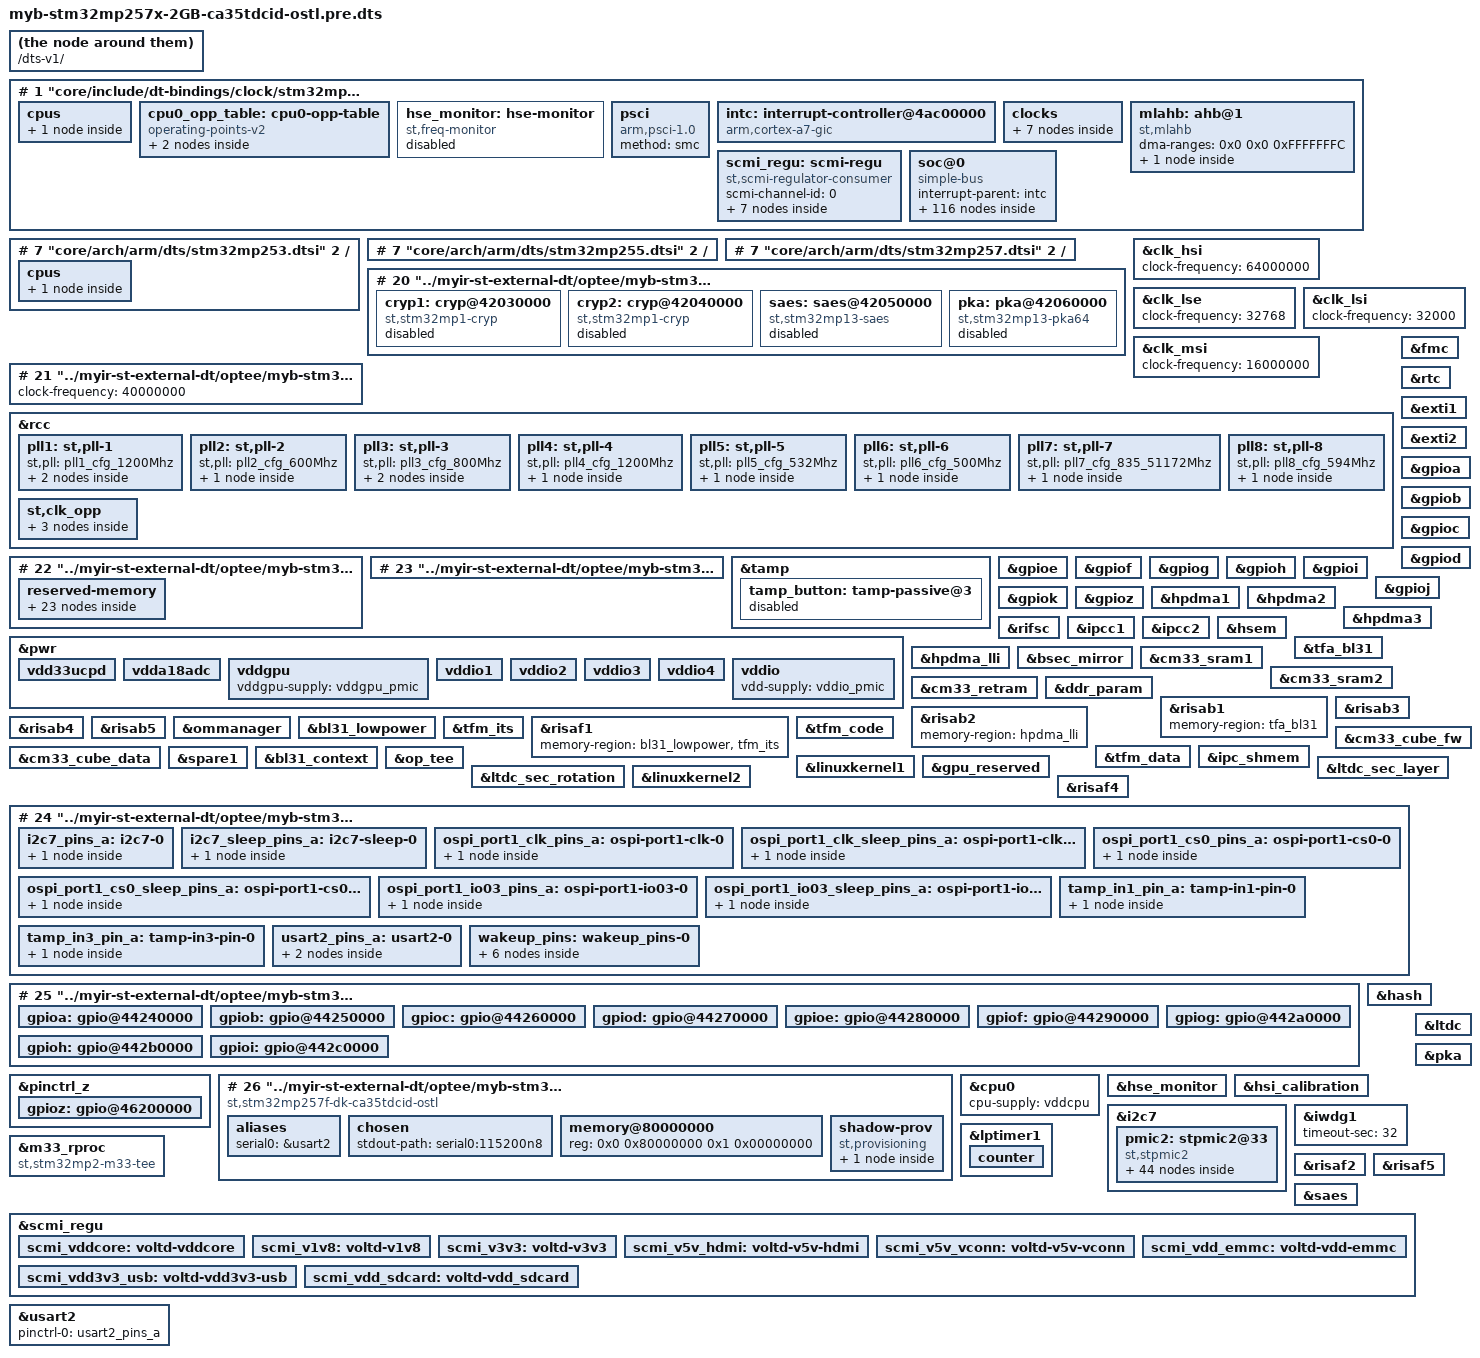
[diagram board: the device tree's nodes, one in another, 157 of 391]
# 0 "../myir-st-external-dt/optee/myb-stm32mp257x-2GB-ca35tdcid-ostl.dts"
# 0 "<built-in>"
# 0 "<command-line>"
# 1 "../myir-st-external-dt/optee/myb-stm32mp257x-2GB-ca35tdcid-ostl.dts"






/dts-v1/;

# 1 "core/include/dt-bindings/clock/stm32mp25-clksrc.h" 1
# 10 "../myir-st-external-dt/optee/myb-stm32mp257x-2GB-ca35tdcid-ostl.dts" 2
# 1 "core/include/dt-bindings/mfd/st,stpmic2.h" 1
# 11 "../myir-st-external-dt/optee/myb-stm32mp257x-2GB-ca35tdcid-ostl.dts" 2
# 1 "core/include/dt-bindings/regulator/st,stm32mp25-regulator.h" 1
# 12 "../myir-st-external-dt/optee/myb-stm32mp257x-2GB-ca35tdcid-ostl.dts" 2
# 1 "core/include/dt-bindings/reset/stm32mp25-resets.h" 1
# 13 "../myir-st-external-dt/optee/myb-stm32mp257x-2GB-ca35tdcid-ostl.dts" 2
# 1 "core/include/dt-bindings/soc/stm32mp-provisioning.h" 1
# 14 "../myir-st-external-dt/optee/myb-stm32mp257x-2GB-ca35tdcid-ostl.dts" 2
# 1 "core/include/dt-bindings/soc/stm32mp25-rif.h" 1
# 15 "../myir-st-external-dt/optee/myb-stm32mp257x-2GB-ca35tdcid-ostl.dts" 2
# 1 "core/include/dt-bindings/soc/stm32mp25-risab.h" 1
# 16 "../myir-st-external-dt/optee/myb-stm32mp257x-2GB-ca35tdcid-ostl.dts" 2
# 1 "core/include/dt-bindings/soc/stm32mp25-risaf.h" 1
# 17 "../myir-st-external-dt/optee/myb-stm32mp257x-2GB-ca35tdcid-ostl.dts" 2
# 1 "core/include/dt-bindings/soc/stm32mp25-rifsc.h" 1
# 18 "../myir-st-external-dt/optee/myb-stm32mp257x-2GB-ca35tdcid-ostl.dts" 2
# 1 "core/include/dt-bindings/tamper/st,stm32mp25-tamp.h" 1
# 19 "../myir-st-external-dt/optee/myb-stm32mp257x-2GB-ca35tdcid-ostl.dts" 2
# 1 "core/arch/arm/dts/stm32mp257.dtsi" 1





# 1 "core/arch/arm/dts/stm32mp255.dtsi" 1





# 1 "core/arch/arm/dts/stm32mp253.dtsi" 1





# 1 "core/arch/arm/dts/stm32mp251.dtsi" 1






# 1 "core/include/dt-bindings/interrupt-controller/arm-gic.h" 1
# 9 "core/include/dt-bindings/interrupt-controller/arm-gic.h"
# 1 "core/include/dt-bindings/interrupt-controller/irq.h" 1
# 10 "core/include/dt-bindings/interrupt-controller/arm-gic.h" 2
# 8 "core/arch/arm/dts/stm32mp251.dtsi" 2
# 1 "core/include/dt-bindings/clock/stm32mp25-clks.h" 1
# 9 "core/arch/arm/dts/stm32mp251.dtsi" 2



/ {
 #address-cells = <2>;
 #size-cells = <2>;

 cpus {
  #address-cells = <1>;
  #size-cells = <0>;

  cpu0: cpu@0 {
   compatible = "arm,cortex-a35";
   device_type = "cpu";
   reg = <0>;
   enable-method = "psci";
   operating-points-v2 = <&cpu0_opp_table>;
   clocks = <&rcc 16>;
  };
 };

 cpu0_opp_table: cpu0-opp-table {
  compatible = "operating-points-v2";

  opp-1200000000 {
   opp-hz = /bits/ 64 <1200000000>;
   opp-microvolt = <800000>;
   opp-supported-hw = <0x3>;
   st,opp-default;
  };

  opp-1500000000 {
   opp-hz = /bits/ 64 <1500000000>;
   opp-microvolt = <910000>;
   opp-supported-hw = <0x2>;
  };
 };

 hse_monitor: hse-monitor {
  compatible = "st,freq-monitor";
  counter = <&lptimer1 1 5 1 1>;
  clocks = <&rcc 1>, <&rcc 0>;
  clock-names = "hse", "hsi";
  status = "disabled";
 };

 psci {
  compatible = "arm,psci-1.0";
  method = "smc";
 };

 intc: interrupt-controller@4ac00000 {
  compatible = "arm,cortex-a7-gic";
  #interrupt-cells = <3>;
  interrupt-controller;
  reg = <0x0 0x4ac10000 0x0 0x1000>,
        <0x0 0x4ac20000 0x0 0x2000>,
        <0x0 0x4ac40000 0x0 0x2000>,
        <0x0 0x4ac60000 0x0 0x2000>;
  #address-cells = <1>;
 };

 clocks {
  clk_hse: clk-hse {
   #clock-cells = <0>;
   compatible = "fixed-clock";
   clock-frequency = <24000000>;
  };

  clk_hsi: clk-hsi {
   #clock-cells = <0>;
   compatible = "fixed-clock";
   clock-frequency = <64000000>;
  };

  clk_lse: clk-lse {
   #clock-cells = <0>;
   compatible = "fixed-clock";
   clock-frequency = <32768>;
  };

  clk_lsi: clk-lsi {
   #clock-cells = <0>;
   compatible = "fixed-clock";
   clock-frequency = <32000>;
  };

  clk_msi: clk-msi {
   #clock-cells = <0>;
   compatible = "fixed-clock";
   clock-frequency = <4000000>;
  };

  clk_i2sin: clk-i2sin {
   #clock-cells = <0>;
   compatible = "fixed-clock";
   clock-frequency = <0>;
  };

  clk_rcbsec: clk-rcbsec {
   #clock-cells = <0>;
   compatible = "fixed-clock";
   clock-frequency = <64000000>;
  };
 };

 mlahb: ahb@1 {
  compatible = "st,mlahb", "simple-bus";
  #address-cells = <1>;
  #size-cells = <1>;
  ranges = <0x0 0x0 0xFFFFFFFC>;
  dma-ranges = <0x0 0x0 0xFFFFFFFC>;

  m33_rproc: m33@0 {
   compatible = "st,stm32mp2-m33";
   reg = <0 0>;
   resets = <&rcc 8288>,
     <&rcc 8608>;
   reset-names = "mcu_rst", "hold_boot";
   status = "disabled";
  };
 };

 scmi_regu: scmi-regu {
  compatible = "st,scmi-regulator-consumer";
  #address-cells = <1>;
  #size-cells = <0>;

  scmi-channel-id = <0>;

  scmi_vddio1: voltd-vddio1 {
   reg = <0>;
   voltd-supply = <&vddio1>;
  };
  scmi_vddio2: voltd-vddio2 {
   reg = <1>;
   voltd-supply = <&vddio2>;
  };
  scmi_vddio3: voltd-vddio3 {
   reg = <2>;
   voltd-supply = <&vddio3>;
  };
  scmi_vddio4: voltd-vddio4 {
   reg = <3>;
   voltd-supply = <&vddio4>;
  };
  scmi_vdd33ucpd: voltd-vdd33ucpd {
   reg = <5>;
   voltd-supply = <&vdd33ucpd>;
  };
  scmi_vdda18adc: voltd-vdda18adc {
   reg = <7>;
   voltd-supply = <&vdda18adc>;
  };
  scmi_vddgpu: voltd-vddgpu {
   reg = <8>;
   voltd-supply = <&vddgpu>;
  };
 };

 soc@0 {
  compatible = "simple-bus";
  #address-cells = <1>;
  #size-cells = <1>;
  interrupt-parent = <&intc>;
  ranges = <0x0 0x0 0x0 0x80000000>;

  hpdma1: dma-controller@40400000 {
   compatible = "st,stm32-dma3";
   reg = <0x40400000 0x1000>;
   clocks = <&rcc 98>;
   resets = <&rcc 10976>;
   #dma-cells = <4>;
  };

  hpdma2: dma-controller@40410000 {
   compatible = "st,stm32-dma3";
   reg = <0x40410000 0x1000>;
   clocks = <&rcc 99>;
   resets = <&rcc 11008>;
   #dma-cells = <4>;
  };

  hpdma3: dma-controller@40420000 {
   compatible = "st,stm32-dma3";
   reg = <0x40420000 0x1000>;
   clocks = <&rcc 100>;
   resets = <&rcc 11040>;
   #dma-cells = <4>;
  };

  ipcc1: mailbox@40490000 {
   compatible = "st,stm32mp25-ipcc";
   reg = <0x40490000 0x400>;
   clocks = <&rcc 103>;
  };

  ommanager: ommanager@40500000 {
   #address-cells = <2>;
   #size-cells = <1>;
   compatible = "st,stm32mp25-omm";
   reg = <0x40500000 0x400>, <0x60000000 0x10000000>;
   reg-names = "omm", "omm_mm";
   clocks = <&rcc 107>;
   resets = <&rcc 17888>;
   st,syscfg-amcr = <&syscfg 0x2c00 0x7>;
   status = "disabled";

   ranges = <0 0 0x40430000 0x400>,
     <1 0 0x40440000 0x400>;

   ospi1: spi@40430000 {
    compatible = "st,stm32mp25-omi";
    reg = <0 0 0x400>;
    clocks = <&rcc 310>;
    resets = <&rcc 10400>, <&rcc 10416>;
    status = "disabled";
   };

   ospi2: spi@40440000 {
    compatible = "st,stm32mp25-omi";
    reg = <1 0 0x400>;
    clocks = <&rcc 311>;
    resets = <&rcc 10432>, <&rcc 10448>;
    status = "disabled";
   };
  };

  rifsc: rifsc@42080000 {
   compatible = "st,stm32mp25-rifsc";
   reg = <0x42080000 0x1000>;
   #address-cells = <1>;
   #size-cells = <1>;

   lptimer1: timer@40090000 {
    compatible = "st,stm32mp25-lptimer";
    reg = <0x40090000 0x400>;
    interrupts = <0 166 4>;
    clocks = <&rcc 253>;
    clock-names = "mux";
    #address-cells = <1>;
    #size-cells = <0>;
    status = "disabled";

    counter {
     compatible = "st,stm32mp25-lptimer-counter";
     status = "disabled";
    };

    pwm {
     compatible = "st,stm32mp25-pwm-lp";
     #pwm-cells = <3>;
     status = "disabled";
    };

    timer {
     compatible = "st,stm32mp25-lptimer-timer";
     status = "disabled";
    };

    trigger@0 {
     compatible = "st,stm32mp25-lptimer-trigger";
     reg = <0>;
     status = "disabled";
    };
   };

   lptimer2: timer@400a0000 {
    compatible = "st,stm32mp25-lptimer";
    reg = <0x400a0000 0x400>;
    interrupts = <0 215 4>;
    clocks = <&rcc 254>;
    clock-names = "mux";
    #address-cells = <1>;
    #size-cells = <0>;
    status = "disabled";

    counter {
     compatible = "st,stm32mp25-lptimer-counter";
     status = "disabled";
    };

    pwm {
     compatible = "st,stm32mp25-pwm-lp";
     #pwm-cells = <3>;
     status = "disabled";
    };

    timer {
     compatible = "st,stm32mp25-lptimer-timer";
     status = "disabled";
    };

    trigger@1 {
     compatible = "st,stm32mp25-lptimer-trigger";
     reg = <1>;
     status = "disabled";
    };
   };

   usart2: serial@400e0000 {
    compatible = "st,stm32h7-uart";
    reg = <0x400e0000 0x400>;
    interrupts = <0 115 4>;
    clocks = <&rcc 255>;
    status = "disabled";
   };

   usart3: serial@400f0000 {
    compatible = "st,stm32h7-uart";
    reg = <0x400f0000 0x400>;
    interrupts = <0 116 4>;
    clocks = <&rcc 257>;
    status = "disabled";
   };

   uart4: serial@40100000 {
    compatible = "st,stm32h7-uart";
    reg = <0x40100000 0x400>;
    interrupts = <0 126 4>;
    clocks = <&rcc 256>;
    status = "disabled";
   };

   uart5: serial@40110000 {
    compatible = "st,stm32h7-uart";
    reg = <0x40110000 0x400>;
    interrupts = <0 127 4>;
    clocks = <&rcc 258>;
    status = "disabled";
   };

   i2c1: i2c@40120000 {
    compatible = "st,stm32mp25-i2c";
    reg = <0x40120000 0x400>;
    clocks = <&rcc 262>;
    resets = <&rcc 15648>;
    #address-cells = <1>;
    #size-cells = <0>;
    i2c-analog-filter;
    status = "disabled";
   };

   i2c2: i2c@40130000 {
    compatible = "st,stm32mp25-i2c";
    reg = <0x40130000 0x400>;
    clocks = <&rcc 263>;
    resets = <&rcc 15680>;
    #address-cells = <1>;
    #size-cells = <0>;
    i2c-analog-filter;
    status = "disabled";
   };

   i2c3: i2c@40140000 {
    compatible = "st,stm32mp25-i2c";
    reg = <0x40140000 0x400>;
    clocks = <&rcc 266>;
    resets = <&rcc 15712>;
    #address-cells = <1>;
    #size-cells = <0>;
    i2c-analog-filter;
    status = "disabled";
   };

   i2c4: i2c@40150000 {
    compatible = "st,stm32mp25-i2c";
    reg = <0x40150000 0x400>;
    clocks = <&rcc 269>;
    resets = <&rcc 15744>;
    #address-cells = <1>;
    #size-cells = <0>;
    i2c-analog-filter;
    status = "disabled";
   };

   i2c5: i2c@40160000 {
    compatible = "st,stm32mp25-i2c";
    reg = <0x40160000 0x400>;
    clocks = <&rcc 267>;
    resets = <&rcc 15776>;
    #address-cells = <1>;
    #size-cells = <0>;
    i2c-analog-filter;
    status = "disabled";
   };

   i2c6: i2c@40170000 {
    compatible = "st,stm32mp25-i2c";
    reg = <0x40170000 0x400>;
    clocks = <&rcc 270>;
    resets = <&rcc 15808>;
    #address-cells = <1>;
    #size-cells = <0>;
    i2c-analog-filter;
    status = "disabled";
   };

   i2c7: i2c@40180000 {
    compatible = "st,stm32mp25-i2c";
    reg = <0x40180000 0x400>;
    clocks = <&rcc 271>;
    resets = <&rcc 15840>;
    #address-cells = <1>;
    #size-cells = <0>;
    i2c-analog-filter;
    status = "disabled";
   };

   usart6: serial@40220000 {
    compatible = "st,stm32h7-uart";
    reg = <0x40220000 0x400>;
    interrupts = <0 136 4>;
    clocks = <&rcc 278>;
    status = "disabled";
   };

   uart9: serial@402c0000 {
    compatible = "st,stm32h7-uart";
    reg = <0x402c0000 0x400>;
    interrupts = <0 150 4>;
    clocks = <&rcc 281>;
    status = "disabled";
   };

   usart1: serial@40330000 {
    compatible = "st,stm32h7-uart";
    reg = <0x40330000 0x400>;
    interrupts = <0 114 4>;
    clocks = <&rcc 277>;
    status = "disabled";
   };

   uart7: serial@40370000 {
    compatible = "st,stm32h7-uart";
    reg = <0x40370000 0x400>;
    interrupts = <0 148 4>;
    clocks = <&rcc 279>;
    status = "disabled";
   };

   uart8: serial@40380000 {
    compatible = "st,stm32h7-uart";
    reg = <0x40380000 0x400>;
    interrupts = <0 149 4>;
    clocks = <&rcc 280>;
    status = "disabled";
   };

   hash: hash@42010000 {
    compatible = "st,stm32mp13-hash";
    reg = <0x42010000 0x400>;
    interrupts = <0 145 4>;
    clocks = <&rcc 109>;
    resets = <&rcc 17376>;
    status = "disabled";
   };

   rng: rng@42020000 {
    compatible = "st,stm32mp25-rng";
    reg = <0x42020000 0x400>;
    clocks = <&clk_rcbsec>, <&rcc 110>;
    clock-names = "rng_clk", "rng_hclk";
    resets = <&rcc 17280>;
   };

   iwdg1: watchdog@44010000 {
    compatible = "st,stm32mp1-iwdg";
    reg = <0x44010000 0x400>;
    interrupts = <0 2 4>;
    clocks = <&rcc 195>, <&rcc 3>;
    clock-names = "pclk", "lsi";
    status = "disabled";
   };

   iwdg2: watchdog@44020000 {
    compatible = "st,stm32mp1-iwdg";
    reg = <0x44020000 0x400>;
    interrupts = <0 3 4>;
    clocks = <&rcc 196>, <&rcc 3>;
    clock-names = "pclk", "lsi";
    status = "disabled";
   };

   i2c8: i2c@46040000 {
    compatible = "st,stm32mp25-i2c";
    reg = <0x46040000 0x400>;
    clocks = <&rcc 299>;
    resets = <&rcc 15872>;
    #address-cells = <1>;
    #size-cells = <0>;
    i2c-analog-filter;
    status = "disabled";
   };

   lptimer3: timer@46050000 {
    compatible = "st,stm32mp25-lptimer";
    reg = <0x46050000 0x400>;
    interrupts = <0 216 4>;
    clocks = <&rcc 301>;
    clock-names = "mux";
    #address-cells = <1>;
    #size-cells = <0>;
    status = "disabled";

    counter {
     compatible = "st,stm32mp25-lptimer-counter";
     status = "disabled";
    };

    pwm {
     compatible = "st,stm32mp25-pwm-lp";
     #pwm-cells = <3>;
     status = "disabled";
    };

    timer {
     compatible = "st,stm32mp25-lptimer-timer";
     status = "disabled";
    };

    trigger@2 {
     compatible = "st,stm32mp25-lptimer-trigger";
     reg = <2>;
     status = "disabled";
    };
   };

   lptimer4: timer@46060000 {
    compatible = "st,stm32mp25-lptimer";
    reg = <0x46060000 0x400>;
    interrupts = <0 217 4>;
    clocks = <&rcc 302>;
    clock-names = "mux";
    #address-cells = <1>;
    #size-cells = <0>;
    status = "disabled";

    counter {
     compatible = "st,stm32mp25-lptimer-counter";
     status = "disabled";
    };

    pwm {
     compatible = "st,stm32mp25-pwm-lp";
     #pwm-cells = <3>;
     status = "disabled";
    };

    timer {
     compatible = "st,stm32mp25-lptimer-timer";
     status = "disabled";
    };

    trigger@3 {
     compatible = "st,stm32mp25-lptimer-trigger";
     reg = <3>;
     status = "disabled";
    };
   };

   lptimer5: timer@46070000 {
    compatible = "st,stm32mp25-lptimer";
    reg = <0x46070000 0x400>;
    interrupts = <0 218 4>;
    clocks = <&rcc 303>;
    clock-names = "mux";
    #address-cells = <1>;
    #size-cells = <0>;
    status = "disabled";

    counter {
     compatible = "st,stm32mp25-lptimer-counter";
     status = "disabled";
    };

    pwm {
     compatible = "st,stm32mp25-pwm-lp";
     #pwm-cells = <3>;
     status = "disabled";
    };

    timer {
     compatible = "st,stm32mp25-lptimer-timer";
     status = "disabled";
    };

    trigger@4 {
     compatible = "st,stm32mp25-lptimer-trigger";
     reg = <4>;
     status = "disabled";
    };
   };

   ltdc: display-controller@48010000 {
    compatible = "st,stm32-ltdc";
    reg = <0x48010000 0x400>;
    interrupts = <0 160 4>,
          <0 161 4>;
    clocks = <&rcc 206>, <&rcc 339>;
    clock-names = "bus", "lcd";
    resets = <&rcc 16896>;
    status = "disabled";
   };
  };

  iac: iac@42090000 {
   compatible = "st,stm32mp25-iac";
   reg = <0x42090000 0x400>;
   interrupts = <0 246 4>;
  };

  risaf1: risaf@420a0000 {
   compatible = "st,stm32mp25-risaf";
   reg = <0x420a0000 0x1000>;
   clocks = <&rcc 108>;
   st,mem-map = <0x0 0x42000000 0x0 0x2000>;
  };

  risaf2: risaf@420b0000 {
   compatible = "st,stm32mp25-risaf";
   reg = <0x420b0000 0x1000>;
   clocks = <&rcc 310>;
   st,mem-map = <0x0 0x60000000 0x0 0x10000000>;
   status = "disabled";
  };

  risaf4: risaf@420d0000 {
   compatible = "st,stm32mp25-risaf-enc";
   reg = <0x420d0000 0x1000>;
   clocks = <&rcc 249>;
   st,mem-map = <0x0 0x80000000 0x1 0x00000000>;
  };

  risaf5: risaf@420e0000 {
   compatible = "st,stm32mp25-risaf";
   reg = <0x420e0000 0x1000>;
   clocks = <&rcc 94>;
   st,mem-map = <0x0 0x10000000 0x0 0x10000000>;
   status = "disabled";
  };

  risab1: risab@420f0000 {
   compatible = "st,stm32mp25-risab";
   reg = <0x420f0000 0x1000>;
   clocks = <&rcc 88>;
   st,mem-map = <0xa000000 0x20000>;
  };

  risab2: risab@42100000 {
   compatible = "st,stm32mp25-risab";
   reg = <0x42100000 0x1000>;
   clocks = <&rcc 88>;
   st,mem-map = <0xa020000 0x20000>;
  };

  risab3: risab@42110000 {
   compatible = "st,stm32mp25-risab";
   reg = <0x42110000 0x1000>;
   clocks = <&rcc 88>;
   st,mem-map = <0xa040000 0x20000>;
  };

  risab4: risab@42120000 {
   compatible = "st,stm32mp25-risab";
   reg = <0x42120000 0x1000>;
   clocks = <&rcc 88>;
   st,mem-map = <0xa060000 0x20000>;
  };

  risab5: risab@42130000 {
   compatible = "st,stm32mp25-risab";
   reg = <0x42130000 0x1000>;
   clocks = <&rcc 88>;
   st,mem-map = <0xa080000 0x20000>;
  };

  risab6: risab@42140000 {
   compatible = "st,stm32mp25-risab";
   reg = <0x42140000 0x1000>;
   clocks = <&rcc 88>;
   st,mem-map = <0xa0a0000 0x20000>;
   status = "disabled";
  };

  bsec: efuse@44000000 {
   compatible = "st,stm32mp25-bsec";
   reg = <0x44000000 0x1000>;
   #address-cells = <1>;
   #size-cells = <1>;

   part_number_otp@24 {
    reg = <0x24 0x4>;
   };

   package_otp@1e8 {
    reg = <0x1e8 0x1>;
   };

   hconf1_otp: otp124@1f0 {
    reg = <0x1f0 0x4>;
   };

   pkh_otp: otp144@240 {
    reg = <0x240 0x20>;
   };

   oem_fip_enc_key: otp260@410 {
    reg = <0x410 0x20>;
    st,non-secure-otp-provisioning;
   };

   oem_enc_key_2: otp360@5a0 {
    reg = <0x5a0 0x10>;
    st,non-secure-otp-provisioning;
   };

   oem_enc_key_1: otp364@5b0 {
    reg = <0x5b0 0x10>;
    st,non-secure-otp-provisioning;
   };
  };

  vrefbuf: vrefbuf@44060000 {
   compatible = "st,stm32mp25-vrefbuf";
   reg = <0x44060000 0x8>;
   regulator-name = "vrefbuf";
   regulator-min-microvolt = <1210000>;
   regulator-max-microvolt = <1500000>;
   clocks = <&rcc 200>;
   status = "disabled";
  };

  serc: serc@44080000 {
   compatible = "st,stm32mp25-serc";
   reg = <0x44080000 0x1000>;
   interrupts = <0 240 4>;
   clocks = <&rcc 202>;
  };

  rcc: rcc@44200000 {
   compatible = "st,stm32mp25-rcc", "syscon";
   reg = <0x44200000 0x10000>;
   interrupts = <0 259 4>;

   #clock-cells = <1>;
   #reset-cells = <1>;
   clocks = <&clk_hse>, <&clk_hsi>, <&clk_lse>,
     <&clk_lsi>, <&clk_msi>, <&clk_i2sin>;
   clock-names = "clk-hse", "clk-hsi", "clk-lse",
          "clk-lsi", "clk-msi", "clk-i2sin";

   hsi_calibration: hsi-calibration {
    compatible = "st,hsi-cal";
    st,cal_hsi_dev = <31>;
    st,cal_hsi_ref = <1953>;
    status = "disabled";
   };

   msi_calibration: msi-calibration {
    compatible = "st,msi-cal";
    status = "disabled";
   };
  };

  pwr: pwr@44210000 {
   compatible = "st,stm32mp25-pwr";
   reg = <0x44210000 0x400>;
   wakeup-parent = <&exti1>;
   interrupts = <0 226 4>;
   status = "disabled";

   vdd33ucpd: vdd33ucpd {
    compatible = "st,stm32mp25-pwr-regu";
    regulator-name = "vdd33ucpd";
    status = "disabled";
   };

   vdda18adc: vdda18adc {
    compatible = "st,stm32mp25-pwr-regu";
    regulator-name = "vdda18adc";
    status = "disabled";
   };

   vddgpu: vddgpu {
    compatible = "st,stm32mp25-pwr-regu";
    regulator-name = "vddgpu";
    status = "disabled";
   };

   vddio1: vddio1 {
    compatible = "st,stm32mp25-pwr-regu";
    regulator-name = "vddio1";
    status = "disabled";
   };

   vddio2: vddio2 {
    compatible = "st,stm32mp25-pwr-regu";
    regulator-name = "vddio2";
    status = "disabled";
   };

   vddio3: vddio3 {
    compatible = "st,stm32mp25-pwr-regu";
    regulator-name = "vddio3";
    status = "disabled";
   };

   vddio4: vddio4 {
    compatible = "st,stm32mp25-pwr-regu";
    regulator-name = "vddio4";
    status = "disabled";
   };

   vddio: vddio {
    compatible = "st,stm32mp25-pwr-regu";
    regulator-name = "vddio";
    regulator-always-on;
    status = "disabled";
   };
  };

  exti1: interrupt-controller@44220000 {
   compatible = "st,stm32mp1-exti", "syscon";
   interrupt-controller;
   #interrupt-cells = <2>;
   #address-cells = <0>;
   reg = <0x44220000 0x400>;

   exti-interrupt-map {
    #address-cells = <0>;
    #interrupt-cells = <2>;
    interrupt-map-mask = <0xffffffff 0>;
    interrupt-map =
     <0 0 &intc 0 0 268 4>,
     <1 0 &intc 0 0 269 4>,
     <2 0 &intc 0 0 270 4>,
     <3 0 &intc 0 0 271 4>,
     <4 0 &intc 0 0 272 4>,
     <5 0 &intc 0 0 273 4>,
     <6 0 &intc 0 0 274 4>,
     <7 0 &intc 0 0 275 4>,
     <8 0 &intc 0 0 276 4>,
     <9 0 &intc 0 0 277 4>,
     <10 0 &intc 0 0 278 4>,
     <11 0 &intc 0 0 279 4>,
     <12 0 &intc 0 0 280 4>,
     <13 0 &intc 0 0 281 4>,
     <14 0 &intc 0 0 282 4>,
     <15 0 &intc 0 0 283 4>,
     <16 0 &intc 0 0 0 4>,
     <17 0 &intc 0 0 1 4>,
     <18 0 &intc 0 0 260 4>,
     <19 0 &intc 0 0 259 4>,
     <21 0 &intc 0 0 108 4>,
     <22 0 &intc 0 0 110 4>,
     <23 0 &intc 0 0 137 4>,
     <24 0 &intc 0 0 168 4>,
     <25 0 &intc 0 0 181 4>,
     <26 0 &intc 0 0 114 4>,
     <27 0 &intc 0 0 115 4>,
     <28 0 &intc 0 0 116 4>,
     <29 0 &intc 0 0 136 4>,
     <30 0 &intc 0 0 126 4>,
     <31 0 &intc 0 0 127 4>,
     <32 0 &intc 0 0 148 4>,
     <33 0 &intc 0 0 149 4>,
     <34 0 &intc 0 0 150 4>,
     <36 0 &intc 0 0 112 4>,
     <37 0 &intc 0 0 113 4>,
     <38 0 &intc 0 0 125 4>,
     <39 0 &intc 0 0 152 4>,
     <40 0 &intc 0 0 153 4>,
     <41 0 &intc 0 0 154 4>,
     <42 0 &intc 0 0 155 4>,
     <43 0 &intc 0 0 169 4>,
     <44 0 &intc 0 0 182 4>,
     <45 0 &intc 0 0 209 4>,
     <46 0 &intc 0 0 229 4>,
     <47 0 &intc 0 0 166 4>,
     <48 0 &intc 0 0 215 4>,
     <49 0 &intc 0 0 208 4>,
     <50 0 &intc 0 0 210 4>,
     <59 0 &intc 0 0 171 4>,

     <61 0 &intc 0 0 173 4>,

     <64 0 &intc 0 0 220 4>,
     <67 0 &intc 0 0 10 4>,
     <68 0 &intc 0 0 131 4>,
     <70 0 &intc 0 0 134 4>,
     <72 0 &intc 0 0 224 4>,
     <73 0 &intc 0 0 202 4>,
     <74 0 &intc 0 0 109 4>,
     <75 0 &intc 0 0 111 4>,
     <76 0 &intc 0 0 138 4>,
     <77 0 &intc 0 0 253 4>,
     <78 0 &intc 0 0 254 4>,
     <79 0 &intc 0 0 255 4>,
     <83 0 &intc 0 0 257 4>,
     <84 0 &intc 0 0 258 4>;
   };
  };

  syscfg: syscon@44230000 {
   reg = <0x44230000 0x10000>;
   status = "disabled";
  };

  pinctrl: pinctrl@44240000 {
   #address-cells = <1>;
   #size-cells = <1>;
   compatible = "st,stm32mp257-pinctrl";
   ranges = <0 0x44240000 0xa0400>;
   interrupt-parent = <&exti1>;
   st,syscfg = <&exti1 0x60 0xff>;
   pins-are-numbered;

   gpioa: gpio@44240000 {
    gpio-controller;
    #gpio-cells = <2>;
    interrupt-controller;
    #interrupt-cells = <2>;
    reg = <0x0 0x400>;
    clocks = <&rcc 115>;
    st,bank-name = "GPIOA";
    status = "disabled";
   };

   gpiob: gpio@44250000 {
    gpio-controller;
    #gpio-cells = <2>;
    interrupt-controller;
    #interrupt-cells = <2>;
    reg = <0x10000 0x400>;
    clocks = <&rcc 116>;
    st,bank-name = "GPIOB";
    status = "disabled";
   };

   gpioc: gpio@44260000 {
    gpio-controller;
    #gpio-cells = <2>;
    interrupt-controller;
    #interrupt-cells = <2>;
    reg = <0x20000 0x400>;
    clocks = <&rcc 117>;
    st,bank-name = "GPIOC";
    status = "disabled";
   };

   gpiod: gpio@44270000 {
    gpio-controller;
    #gpio-cells = <2>;
    interrupt-controller;
    #interrupt-cells = <2>;
    reg = <0x30000 0x400>;
    clocks = <&rcc 118>;
    st,bank-name = "GPIOD";
    status = "disabled";
   };

   gpioe: gpio@44280000 {
    gpio-controller;
    #gpio-cells = <2>;
    interrupt-controller;
    #interrupt-cells = <2>;
    reg = <0x40000 0x400>;
    clocks = <&rcc 119>;
    st,bank-name = "GPIOE";
    status = "disabled";
   };

   gpiof: gpio@44290000 {
    gpio-controller;
    #gpio-cells = <2>;
    interrupt-controller;
    #interrupt-cells = <2>;
    reg = <0x50000 0x400>;
    clocks = <&rcc 120>;
    st,bank-name = "GPIOF";
    status = "disabled";
   };

   gpiog: gpio@442a0000 {
    gpio-controller;
    #gpio-cells = <2>;
    interrupt-controller;
    #interrupt-cells = <2>;
    reg = <0x60000 0x400>;
    clocks = <&rcc 121>;
    st,bank-name = "GPIOG";
    status = "disabled";
   };

   gpioh: gpio@442b0000 {
    gpio-controller;
    #gpio-cells = <2>;
    interrupt-controller;
    #interrupt-cells = <2>;
    reg = <0x70000 0x400>;
    clocks = <&rcc 122>;
    st,bank-name = "GPIOH";
    status = "disabled";
   };

   gpioi: gpio@442c0000 {
    gpio-controller;
    #gpio-cells = <2>;
    interrupt-controller;
    #interrupt-cells = <2>;
    reg = <0x80000 0x400>;
    clocks = <&rcc 123>;
    st,bank-name = "GPIOI";
    status = "disabled";
   };

   gpioj: gpio@442d0000 {
    gpio-controller;
    #gpio-cells = <2>;
    interrupt-controller;
    #interrupt-cells = <2>;
    reg = <0x90000 0x400>;
    clocks = <&rcc 124>;
    st,bank-name = "GPIOJ";
    status = "disabled";
   };

   gpiok: gpio@442e0000 {
    gpio-controller;
    #gpio-cells = <2>;
    interrupt-controller;
    #interrupt-cells = <2>;
    reg = <0xa0000 0x400>;
    clocks = <&rcc 125>;
    st,bank-name = "GPIOK";
    status = "disabled";
   };
  };

  rtc: rtc@46000000 {
   compatible = "st,stm32mp25-rtc";
   reg = <0x46000000 0x400>;
   clocks = <&rcc 133>, <&rcc 6>;
   clock-names = "pclk", "rtc_ck";
   interrupts = <0 15 4>;
   status = "disabled";
  };

  tamp: tamp@46010000 {
   compatible = "st,stm32mp25-tamp";
   reg = <0x46010000 0x400>;
   clocks = <&rcc 133>;
   interrupts = <0 14 4>;
   #address-cells = <1>;
   #size-cells = <1>;
   ranges;
   st,backup-zones = <24 24 24 24 12 12 8>;

   nvram: nvram@46010100 {
    compatible = "st,stm32mp25-tamp-nvram";
    #address-cells = <1>;
    #size-cells = <1>;
    reg = <0x46010100 0x200>;

    boot_mode: tamp-bkp@180 {
     reg = <0x180 0x4>;
    };
   };

   reboot_mode: reboot-mode {
    compatible = "nvmem-reboot-mode";
    nvmem-cells = <&boot_mode>;
    nvmem-cell-names = "reboot-mode";
    mode-normal = <0x00>;
    mode-fastboot = <0x01>;
    mode-recovery = <0x02>;
    mode-stm32cubeprogrammer = <0x03>;
    mode-ums_mmc0 = <0x10>;
    mode-ums_mmc1 = <0x11>;
    mode-ums_mmc2 = <0x12>;
    mode-romcode_serial = <0xff>;
   };
  };

  pinctrl_z: pinctrl-z@46200000 {
   #address-cells = <1>;
   #size-cells = <1>;
   compatible = "st,stm32mp257-z-pinctrl";
   ranges = <0 0x46200000 0x400>;
   interrupt-parent = <&exti1>;
   st,syscfg = <&exti1 0x60 0xff>;
   pins-are-numbered;

   gpioz: gpio@46200000 {
    gpio-controller;
    #gpio-cells = <2>;
    interrupt-controller;
    #interrupt-cells = <2>;
    reg = <0 0x400>;
    clocks = <&rcc 129>;
    st,bank-name = "GPIOZ";
    st,bank-ioport = <11>;
    status = "disabled";
   };
  };

  exti2: interrupt-controller@46230000 {
   compatible = "st,stm32mp1-exti", "syscon";
   interrupt-controller;
   #interrupt-cells = <2>;
   #address-cells = <0>;
   reg = <0x46230000 0x400>;

   exti-interrupt-map {
    #address-cells = <0>;
    #interrupt-cells = <2>;
    interrupt-map-mask = <0xffffffff 0>;
    interrupt-map =
     <16 0 &intc 0 0 12 4>,
     <17 0 &intc 0 0 13 4>,
     <21 0 &intc 0 0 14 4>,
     <22 0 &intc 0 0 15 4>,
     <25 0 &intc 0 0 212 4>,
     <26 0 &intc 0 0 151 4>,
     <27 0 &intc 0 0 156 4>,
     <29 0 &intc 0 0 216 4>,
     <30 0 &intc 0 0 217 4>,
     <31 0 &intc 0 0 218 4>,
     <33 0 &intc 0 0 207 4>,
     <34 0 &intc 0 0 175 4>,

     <37 0 &intc 0 0 177 4>,

     <40 0 &intc 0 0 199 4>,
     <43 0 &intc 0 0 200 4>,
     <46 0 &intc 0 0 11 4>,
     <48 0 &intc 0 0 5 4>,
     <49 0 &intc 0 0 4 4>,
     <50 0 &intc 0 0 6 4>,
     <51 0 &intc 0 0 7 4>,
     <52 0 &intc 0 0 2 4>,
     <53 0 &intc 0 0 3 4>,
     <61 0 &intc 0 0 221 4>,
     <62 0 &intc 0 0 246 4>,
     <64 0 &intc 0 0 247 4>,
     <65 0 &intc 0 0 248 4>,
     <66 0 &intc 0 0 249 4>,
     <67 0 &intc 0 0 256 4>,
     <70 0 &intc 0 0 213 4>;
   };
  };

  hsem: hwspinlock@46240000 {
   compatible = "st,stm32mp25-hsem";
   reg = <0x46240000 0x400>;
   interrupts = <0 200 4>;
   clocks = <&rcc 131>;
  };

  ipcc2: mailbox@46250000 {
   compatible = "st,stm32mp25-ipcc";
   reg = <0x46250000 0x400>;
   clocks = <&rcc 132>;
  };

  stgenc: stgen@48080000 {
   compatible = "st,stm32mp25-stgen";
   reg = <0x48080000 0x1000>;
   clocks = <&rcc 215>, <&rcc 294>;
   clock-names = "bus", "tsgen_clk";
   st,tsgen-clk-source = <&rcc 1>;
  };

  fmc: memory-controller@48200000 {
   #address-cells = <2>;
   #size-cells = <1>;
   compatible = "st,stm32mp25-fmc2-ebi";
   reg = <0x48200000 0x400>;
   clocks = <&rcc 312>;
   resets = <&rcc 10464>;
   status = "disabled";

   ranges = <0 0 0x60000000 0x04000000>,
     <1 0 0x64000000 0x04000000>,
     <2 0 0x68000000 0x04000000>,
     <3 0 0x6c000000 0x04000000>,
     <4 0 0x80000000 0x10000000>;
  };
 };
};
# 7 "core/arch/arm/dts/stm32mp253.dtsi" 2

/ {
 cpus {
  cpu1: cpu@1 {
   compatible = "arm,cortex-a35";
   device_type = "cpu";
   reg = <1>;
   enable-method = "psci";
  };
 };
};
# 7 "core/arch/arm/dts/stm32mp255.dtsi" 2

/ {
};
# 7 "core/arch/arm/dts/stm32mp257.dtsi" 2

/ {
};
# 20 "../myir-st-external-dt/optee/myb-stm32mp257x-2GB-ca35tdcid-ostl.dts" 2
# 1 "core/arch/arm/dts/stm32mp25xf.dtsi" 1






&rifsc {
 cryp1: cryp@42030000 {
  compatible = "st,stm32mp1-cryp";
  reg = <0x42030000 0x400>;
  interrupts = <0 144 4>;
  clocks = <&rcc 111>;
  resets = <&rcc 17408>;
  status = "disabled";
 };

 cryp2: cryp@42040000 {
  compatible = "st,stm32mp1-cryp";
  reg = <0x42040000 0x400>;
  interrupts = <0 180 4>;
  clocks = <&rcc 112>;
  resets = <&rcc 17440>;
  status = "disabled";
 };

 saes: saes@42050000 {
  compatible = "st,stm32mp13-saes";
  reg = <0x42050000 0x400>;
  interrupts = <0 179 4>;
  clocks = <&rcc 113>, <&rcc 110>;
  clock-names = "bus", "rng";
  resets = <&rcc 17344>;
  status = "disabled";
 };

 pka: pka@42060000 {
  compatible = "st,stm32mp13-pka64";
  reg = <0x42060000 0x2000>;
  interrupts = <0 146 4>;
  clocks = <&rcc 114>, <&rcc 110>;
  clock-names = "bus", "rng";
  resets = <&rcc 17312>;
  status = "disabled";
 };
};
# 21 "../myir-st-external-dt/optee/myb-stm32mp257x-2GB-ca35tdcid-ostl.dts" 2
# 1 "../myir-st-external-dt/optee/stm32mp257f-dk-ca35tdcid-ostl-rcc.dtsi" 1
# 13 "../myir-st-external-dt/optee/stm32mp257f-dk-ca35tdcid-ostl-rcc.dtsi"
&clk_hse {
 clock-frequency = <40000000>;
};

&clk_hsi {
 clock-frequency = <64000000>;
};

&clk_lse {
 clock-frequency = <32768>;
};

&clk_lsi {
 clock-frequency = <32000>;
};

&clk_msi {
 clock-frequency = <16000000>;
};

&rcc {
 st,busclk = <
  ((0 << 26) | ((0) << 8 | (1)))
  ((0 << 26) | ((1) << 8 | (0)))
  ((0 << 26) | ((2) << 8 | (0)))
  ((0 << 26) | ((3) << 8 | (0)))
  ((0 << 26) | ((4) << 8 | (0)))
  ((0 << 26) | ((5) << 8 | (0)))
 >;

 st,flexgen = <
  ((3 << 26) | ((0) << 13) | ((0x0) << 9) | ((0) << 6) | ((2) << 0))
  ((3 << 26) | ((1) << 13) | ((0x0) << 9) | ((0) << 6) | ((5) << 0))
  ((3 << 26) | ((2) << 13) | ((0x0) << 9) | ((0) << 6) | ((1) << 0))
  ((3 << 26) | ((3) << 13) | ((0x0) << 9) | ((0) << 6) | ((2) << 0))
  ((3 << 26) | ((4) << 13) | ((0x0) << 9) | ((0) << 6) | ((3) << 0))
  ((3 << 26) | ((5) << 13) | ((0x0) << 9) | ((0) << 6) | ((2) << 0))
  ((3 << 26) | ((6) << 13) | ((0x0) << 9) | ((0) << 6) | ((1) << 0))
  ((3 << 26) | ((7) << 13) | ((0x0) << 9) | ((0) << 6) | ((11) << 0))
  ((3 << 26) | ((8) << 13) | ((0x8) << 9) | ((0) << 6) | ((0) << 0))
  ((3 << 26) | ((9) << 13) | ((0x8) << 9) | ((0) << 6) | ((0) << 0))
  ((3 << 26) | ((10) << 13) | ((0x3) << 9) | ((0) << 6) | ((16) << 0))
  ((3 << 26) | ((12) << 13) | ((0x0) << 9) | ((0) << 6) | ((11) << 0))
  ((3 << 26) | ((15) << 13) | ((0x0) << 9) | ((0) << 6) | ((11) << 0))
  ((3 << 26) | ((18) << 13) | ((0x1) << 9) | ((0) << 6) | ((3) << 0))
  ((3 << 26) | ((19) << 13) | ((0x8) << 9) | ((0) << 6) | ((0) << 0))
  ((3 << 26) | ((20) << 13) | ((0x8) << 9) | ((0) << 6) | ((0) << 0))
  ((3 << 26) | ((23) << 13) | ((0x3) << 9) | ((0) << 6) | ((16) << 0))
  ((3 << 26) | ((25) << 13) | ((0x3) << 9) | ((0) << 6) | ((16) << 0))
  ((3 << 26) | ((27) << 13) | ((0x4) << 9) | ((0) << 6) | ((3) << 0))
  ((3 << 26) | ((28) << 13) | ((0x4) << 9) | ((0) << 6) | ((21) << 0))
  ((3 << 26) | ((29) << 13) | ((0x1) << 9) | ((0) << 6) | ((1) << 0))
  ((3 << 26) | ((30) << 13) | ((0x9) << 9) | ((0) << 6) | ((1) << 0))
  ((3 << 26) | ((31) << 13) | ((0x1) << 9) | ((0) << 6) | ((19) << 0))
  ((3 << 26) | ((32) << 13) | ((0x1) << 9) | ((0) << 6) | ((19) << 0))
  ((3 << 26) | ((33) << 13) | ((0x0) << 9) | ((0) << 6) | ((23) << 0))
  ((3 << 26) | ((34) << 13) | ((0x0) << 9) | ((0) << 6) | ((59) << 0))
  ((3 << 26) | ((35) << 13) | ((0x8) << 9) | ((0) << 6) | ((3) << 0))
  ((3 << 26) | ((38) << 13) | ((0x1) << 9) | ((0) << 6) | ((3) << 0))
  ((3 << 26) | ((40) << 13) | ((0xE) << 9) | ((0) << 6) | ((0) << 0))
  ((3 << 26) | ((41) << 13) | ((0x0) << 9) | ((0) << 6) | ((11) << 0))
  ((3 << 26) | ((43) << 13) | ((0x0) << 9) | ((0) << 6) | ((23) << 0))
  ((3 << 26) | ((44) << 13) | ((0x0) << 9) | ((0) << 6) | ((5) << 0))
  ((3 << 26) | ((45) << 13) | ((0x0) << 9) | ((0) << 6) | ((2) << 0))
  ((3 << 26) | ((46) << 13) | ((0x1) << 9) | ((0) << 6) | ((3) << 0))
  ((3 << 26) | ((47) << 13) | ((0x1) << 9) | ((0) << 6) | ((3) << 0))
  ((3 << 26) | ((51) << 13) | ((0x0) << 9) | ((0) << 6) | ((5) << 0))
  ((3 << 26) | ((52) << 13) | ((0x0) << 9) | ((0) << 6) | ((5) << 0))
  ((3 << 26) | ((53) << 13) | ((0x0) << 9) | ((0) << 6) | ((5) << 0))
  ((3 << 26) | ((54) << 13) | ((0x2) << 9) | ((0) << 6) | ((3) << 0))
  ((3 << 26) | ((56) << 13) | ((0x0) << 9) | ((0) << 6) | ((5) << 0))
  ((3 << 26) | ((57) << 13) | ((0x9) << 9) | ((0) << 6) | ((1) << 0))
  ((3 << 26) | ((58) << 13) | ((0x9) << 9) | ((0) << 6) | ((1) << 0))
  ((3 << 26) | ((59) << 13) | ((0x0) << 9) | ((0) << 6) | ((1) << 0))
  ((3 << 26) | ((61) << 13) | ((0x0) << 9) | ((0) << 6) | ((7) << 0))
  ((3 << 26) | ((62) << 13) | ((0x0) << 9) | ((0) << 6) | ((7) << 0))
  ((3 << 26) | ((63) << 13) | ((0x0) << 9) | ((0) << 6) | ((2) << 0))
 >;

 st,kerclk = <
  ((1 << 26) | ((12) << 4 | (0x0)))
  ((1 << 26) | ((14) << 4 | (0x0)))
  ((1 << 26) | ((15) << 4 | (0x0)))
  ((1 << 26) | ((16) << 4 | (0x1)))
  ((1 << 26) | ((18) << 4 | (0x0)))
  ((1 << 26) | ((17) << 4 | (0x0)))
  ((1 << 26) | ((19) << 4 | (0x0)))
  ((1 << 26) | ((20) << 4 | (0x1)))
  ((1 << 26) | ((9) << 4 | (0x1)))
  ((1 << 26) | ((21) << 4 | (0x0)))
  (0x80000000 | ((0x494) << 16) | ((0) << 8) | (0x0))
  (0x80000000 | ((0x498) << 16) | ((0) << 8) | (0x0))
 >;

 pll1: st,pll-1 {
  st,pll = <&pll1_cfg_1200Mhz>;

  pll1_cfg_1200Mhz: pll1-cfg-1200Mhz {
   cfg = <30 1 1 1>;
   src = <((1 << 26) | ((5) << 4 | (1)))>;
  };

  pll1_cfg_1500Mhz: pll1-cfg-1500Mhz {
   cfg = <75 2 1 1>;
   src = <((1 << 26) | ((5) << 4 | (1)))>;
  };
 };

 pll2: st,pll-2 {
  st,pll = <&pll2_cfg_600Mhz>;

  pll2_cfg_600Mhz: pll2-cfg-600Mhz {
   cfg = <30 1 1 2>;
   src = <((1 << 26) | ((6) << 4 | (1)))>;
  };
 };

 pll3: st,pll-3 {
  st,pll = <&pll3_cfg_800Mhz>;

  pll3_cfg_800Mhz: pll3-cfg-800Mhz {
   cfg = <20 1 1 1>;
   src = <((1 << 26) | ((7) << 4 | (1)))>;
  };

  pll3_cfg_900Mhz: pll3-cfg-900Mhz {
   cfg = <45 2 1 1>;
   src = <((1 << 26) | ((7) << 4 | (1)))>;
  };
 };

 pll4: st,pll-4 {
  st,pll = <&pll4_cfg_1200Mhz>;

  pll4_cfg_1200Mhz: pll4-cfg-1200Mhz {
   cfg = <30 1 1 1>;
   src = <((1 << 26) | ((0) << 4 | (1)))>;
  };
 };

 pll5: st,pll-5 {
  st,pll = <&pll5_cfg_532Mhz>;

  pll5_cfg_532Mhz: pll5-cfg-532Mhz {
   cfg = <133 5 1 2>;
   src = <((1 << 26) | ((1) << 4 | (1)))>;
  };
 };

 pll6: st,pll-6 {
  st,pll = <&pll6_cfg_500Mhz>;

  pll6_cfg_500Mhz: pll6-cfg-500Mhz {
   cfg = <25 1 1 2>;
   src = <((1 << 26) | ((2) << 4 | (1)))>;
  };
 };

 pll7: st,pll-7 {
  st,pll = <&pll7_cfg_835_51172Mhz>;

  pll7_cfg_835_51172Mhz: pll7-cfg-835-51172Mhz {
   cfg = <167 4 1 2>;
   src = <((1 << 26) | ((3) << 4 | (1)))>;
   frac = < 0x1A3337 >;
  };
 };

 pll8: st,pll-8 {
  st,pll = <&pll8_cfg_594Mhz>;

  pll8_cfg_594Mhz: pll8-cfg-594Mhz {
   cfg = <297 5 1 4>;
   src = <((1 << 26) | ((4) << 4 | (1)))>;
  };
 };
};
# 22 "../myir-st-external-dt/optee/myb-stm32mp257x-2GB-ca35tdcid-ostl.dts" 2
# 1 "../myir-st-external-dt/optee/stm32mp257f-dk-ca35tdcid-ostl-resmem.dtsi" 1
# 13 "../myir-st-external-dt/optee/stm32mp257f-dk-ca35tdcid-ostl-resmem.dtsi"
/ {
 reserved-memory {
  #address-cells = <2>;
  #size-cells = <2>;
  ranges;


  tfa_bl31: tfa-bl31@a000000 {
   reg = <0x0 0xa000000 0x0 0x20000>;
   no-map;
  };

  hpdma_lli: hpdma-lli@a020000 {
   reg = <0x0 0xa020000 0x0 0x20000>;
   no-map;
  };

  bsec_mirror: bsec-mirror@a040000 {
   reg = <0x0 0xa040000 0x0 0x1000>;
   no-map;
  };

  cm33_sram1: cm33-sram1@a041000 {
   reg = <0x0 0xa041000 0x0 0x1f000>;
   no-map;
  };

  cm33_sram2: cm33-sram2@a060000 {
   reg = <0x0 0xa060000 0x0 0x20000>;
   no-map;
  };

  cm33_retram: cm33-retram@a080000 {
   reg = <0x0 0xa080000 0x0 0x1f000>;
   no-map;
  };

  ddr_param: ddr-param@a09f000 {
   reg = <0x0 0xa09f000 0x0 0x1000>;
   no-map;
  };



  bl31_lowpower: bl31-lowpower@42000000 {
   reg = <0x0 0x42000000 0x0 0x1000>;
   no-map;
  };

  tfm_its: tfm-its@42001000 {
   reg = <0x0 0x42001000 0x0 0x1000>;
   no-map;
  };


  mm_ospi1: mm-ospi@60000000 {
   reg = <0x0 0x60000000 0x0 0x10000000>;
   no-map;
  };


  tfm_code: tfm-code@80000000 {
   reg = <0x0 0x80000000 0x0 0x100000>;
   no-map;
  };

  cm33_cube_fw: cm33-cube-fw@80100000 {
   reg = <0x0 0x80100000 0x0 0x800000>;
   no-map;
  };

  tfm_data: tfm-data@80900000 {
   reg = <0x0 0x80900000 0x0 0x100000>;
   no-map;
  };

  cm33_cube_data: cm33-cube-data@80a00000 {
   reg = <0x0 0x80a00000 0x0 0x800000>;
   no-map;
  };

  ipc_shmem: ipc-shmem@81200000 {
   reg = <0x0 0x81200000 0x0 0x100000>;
   no-map;
  };

  spare1: spare1@81300000 {
   reg = <0x0 0x81300000 0x0 0xcc0000>;
   no-map;
  };

  bl31_context: bl31-context@81fc0000 {
   reg = <0x0 0x81fc0000 0x0 0x40000>;
   no-map;
  };

  op_tee: op-tee@82000000 {
   reg = <0x0 0x82000000 0x0 0x2000000>;
   no-map;
  };

  linuxkernel1: linuxkernel1@84000000 {
   reg = <0x0 0x84000000 0x0 0x76800000>;
   no-map;
  };

  gpu_reserved: gpu-reserved@fa800000 {
   reg = <0x0 0xfa800000 0x0 0x4000000>;
   no-map;
  };

  ltdc_sec_layer: ltdc-sec-layer@fe800000 {
   reg = <0x0 0xfe800000 0x0 0x800000>;
   no-map;
  };

  ltdc_sec_rotation: ltdc-sec-rotation@ff000000 {
   reg = <0x0 0xff000000 0x0 0x1000000>;
   no-map;
  };

  linuxkernel2: linuxkernel2@100000000 {
   reg = <0x1 0x00000000 0x0 0x80000000>;
   no-map;
  };

 };
};
# 23 "../myir-st-external-dt/optee/myb-stm32mp257x-2GB-ca35tdcid-ostl.dts" 2
# 1 "../myir-st-external-dt/optee/stm32mp257f-dk-ca35tdcid-ostl-rif.dtsi" 1
# 13 "../myir-st-external-dt/optee/stm32mp257f-dk-ca35tdcid-ostl-rif.dtsi"
&rifsc {
 st,protreg = <
  (((0) << 24) | ((0x0) << 16) | ((0x0) << 10) | ((0x1) << 9) | ((0x0) << 8) | ((0x1) << 4) | ((0x0) << 1) | ((0x1) << 0))
  (((1) << 24) | ((0x0) << 16) | ((0x0) << 10) | ((0x0) << 9) | ((0x0) << 8) | ((0x2) << 4) | ((0x0) << 1) | ((0x1) << 0))
  (((2) << 24) | ((0x0) << 16) | ((0x0) << 10) | ((0x1) << 9) | ((0x0) << 8) | ((0x1) << 4) | ((0x0) << 1) | ((0x1) << 0))
  (((3) << 24) | ((0x0) << 16) | ((0x0) << 10) | ((0x1) << 9) | ((0x0) << 8) | ((0x1) << 4) | ((0x0) << 1) | ((0x1) << 0))
  (((4) << 24) | ((0x0) << 16) | ((0x0) << 10) | ((0x1) << 9) | ((0x0) << 8) | ((0x1) << 4) | ((0x0) << 1) | ((0x1) << 0))
  (((5) << 24) | ((0x0) << 16) | ((0x0) << 10) | ((0x0) << 9) | ((0x0) << 8) | ((0x2) << 4) | ((0x0) << 1) | ((0x1) << 0))
  (((6) << 24) | ((0x0) << 16) | ((0x0) << 10) | ((0x1) << 9) | ((0x0) << 8) | ((0x1) << 4) | ((0x0) << 1) | ((0x1) << 0))
  (((7) << 24) | ((0x0) << 16) | ((0x0) << 10) | ((0x1) << 9) | ((0x0) << 8) | ((0x1) << 4) | ((0x0) << 1) | ((0x1) << 0))
  (((8) << 24) | ((0x0) << 16) | ((0x0) << 10) | ((0x1) << 9) | ((0x0) << 8) | ((0x1) << 4) | ((0x0) << 1) | ((0x1) << 0))
  (((9) << 24) | ((0x0) << 16) | ((0x0) << 10) | ((0x1) << 9) | ((0x0) << 8) | ((0x1) << 4) | ((0x0) << 1) | ((0x1) << 0))
  (((10) << 24) | ((0x0) << 16) | ((0x0) << 10) | ((0x1) << 9) | ((0x0) << 8) | ((0x1) << 4) | ((0x0) << 1) | ((0x1) << 0))
  (((11) << 24) | ((0x0) << 16) | ((0x0) << 10) | ((0x1) << 9) | ((0x0) << 8) | ((0x1) << 4) | ((0x0) << 1) | ((0x1) << 0))
  (((12) << 24) | ((0x0) << 16) | ((0x0) << 10) | ((0x1) << 9) | ((0x0) << 8) | ((0x1) << 4) | ((0x0) << 1) | ((0x1) << 0))
  (((13) << 24) | ((0x0) << 16) | ((0x0) << 10) | ((0x1) << 9) | ((0x0) << 8) | ((0x1) << 4) | ((0x0) << 1) | ((0x1) << 0))
  (((14) << 24) | ((0x0) << 16) | ((0x0) << 10) | ((0x1) << 9) | ((0x0) << 8) | ((0x1) << 4) | ((0x0) << 1) | ((0x1) << 0))
  (((15) << 24) | ((0x0) << 16) | ((0x0) << 10) | ((0x1) << 9) | ((0x0) << 8) | ((0x1) << 4) | ((0x0) << 1) | ((0x1) << 0))
  (((16) << 24) | ((0x0) << 16) | ((0x0) << 10) | ((0x1) << 9) | ((0x0) << 8) | ((0x1) << 4) | ((0x0) << 1) | ((0x1) << 0))
  (((17) << 24) | ((0x0) << 16) | ((0x0) << 10) | ((0x1) << 9) | ((0x1) << 8) | ((0x1) << 4) | ((0x0) << 1) | ((0x1) << 0))
  (((18) << 24) | ((0x0) << 16) | ((0x0) << 10) | ((0x1) << 9) | ((0x0) << 8) | ((0x1) << 4) | ((0x0) << 1) | ((0x1) << 0))
  (((19) << 24) | ((0x0) << 16) | ((0x0) << 10) | ((0x1) << 9) | ((0x0) << 8) | ((0x1) << 4) | ((0x0) << 1) | ((0x1) << 0))
  (((20) << 24) | ((0x0) << 16) | ((0x0) << 10) | ((0x1) << 9) | ((0x0) << 8) | ((0x1) << 4) | ((0x0) << 1) | ((0x1) << 0))
  (((21) << 24) | ((0x0) << 16) | ((0x0) << 10) | ((0x1) << 9) | ((0x0) << 8) | ((0x1) << 4) | ((0x0) << 1) | ((0x1) << 0))
  (((22) << 24) | ((0x0) << 16) | ((0x0) << 10) | ((0x0) << 9) | ((0x0) << 8) | ((0x0) << 4) | ((0x1) << 1) | ((0x1) << 0))
  (((23) << 24) | ((0x0) << 16) | ((0x0) << 10) | ((0x1) << 9) | ((0x0) << 8) | ((0x1) << 4) | ((0x0) << 1) | ((0x1) << 0))
  (((24) << 24) | ((0x0) << 16) | ((0x0) << 10) | ((0x0) << 9) | ((0x0) << 8) | ((0x0) << 4) | ((0x1) << 1) | ((0x1) << 0))
  (((25) << 24) | ((0x0) << 16) | ((0x0) << 10) | ((0x0) << 9) | ((0x0) << 8) | ((0x0) << 4) | ((0x1) << 1) | ((0x1) << 0))
  (((26) << 24) | ((0x0) << 16) | ((0x0) << 10) | ((0x0) << 9) | ((0x0) << 8) | ((0x0) << 4) | ((0x1) << 1) | ((0x1) << 0))
  (((27) << 24) | ((0x0) << 16) | ((0x0) << 10) | ((0x1) << 9) | ((0x0) << 8) | ((0x1) << 4) | ((0x0) << 1) | ((0x1) << 0))
  (((28) << 24) | ((0x0) << 16) | ((0x0) << 10) | ((0x0) << 9) | ((0x0) << 8) | ((0x0) << 4) | ((0x1) << 1) | ((0x1) << 0))
  (((29) << 24) | ((0x0) << 16) | ((0x0) << 10) | ((0x0) << 9) | ((0x0) << 8) | ((0x0) << 4) | ((0x1) << 1) | ((0x1) << 0))
  (((30) << 24) | ((0x0) << 16) | ((0x0) << 10) | ((0x0) << 9) | ((0x0) << 8) | ((0x0) << 4) | ((0x1) << 1) | ((0x1) << 0))
  (((31) << 24) | ((0x0) << 16) | ((0x0) << 10) | ((0x1) << 9) | ((0x0) << 8) | ((0x1) << 4) | ((0x0) << 1) | ((0x1) << 0))
  (((32) << 24) | ((0x0) << 16) | ((0x0) << 10) | ((0x1) << 9) | ((0x0) << 8) | ((0x1) << 4) | ((0x0) << 1) | ((0x1) << 0))
  (((33) << 24) | ((0x0) << 16) | ((0x0) << 10) | ((0x0) << 9) | ((0x0) << 8) | ((0x0) << 4) | ((0x1) << 1) | ((0x1) << 0))
  (((34) << 24) | ((0x0) << 16) | ((0x0) << 10) | ((0x0) << 9) | ((0x0) << 8) | ((0x0) << 4) | ((0x1) << 1) | ((0x1) << 0))
  (((35) << 24) | ((0x0) << 16) | ((0x0) << 10) | ((0x0) << 9) | ((0x0) << 8) | ((0x2) << 4) | ((0x0) << 1) | ((0x1) << 0))
  (((36) << 24) | ((0x0) << 16) | ((0x0) << 10) | ((0x0) << 9) | ((0x0) << 8) | ((0x2) << 4) | ((0x0) << 1) | ((0x1) << 0))
  (((37) << 24) | ((0x0) << 16) | ((0x0) << 10) | ((0x0) << 9) | ((0x0) << 8) | ((0x0) << 4) | ((0x1) << 1) | ((0x1) << 0))
  (((38) << 24) | ((0x0) << 16) | ((0x0) << 10) | ((0x0) << 9) | ((0x0) << 8) | ((0x0) << 4) | ((0x1) << 1) | ((0x1) << 0))
  (((39) << 24) | ((0x0) << 16) | ((0x0) << 10) | ((0x0) << 9) | ((0x0) << 8) | ((0x0) << 4) | ((0x1) << 1) | ((0x1) << 0))
  (((40) << 24) | ((0x0) << 16) | ((0x0) << 10) | ((0x0) << 9) | ((0x0) << 8) | ((0x0) << 4) | ((0x1) << 1) | ((0x1) << 0))
  (((41) << 24) | ((0x0) << 16) | ((0x0) << 10) | ((0x0) << 9) | ((0x0) << 8) | ((0x2) << 4) | ((0x0) << 1) | ((0x1) << 0))
  (((42) << 24) | ((0x0) << 16) | ((0x0) << 10) | ((0x1) << 9) | ((0x0) << 8) | ((0x1) << 4) | ((0x0) << 1) | ((0x1) << 0))
  (((43) << 24) | ((0x0) << 16) | ((0x0) << 10) | ((0x0) << 9) | ((0x0) << 8) | ((0x0) << 4) | ((0x1) << 1) | ((0x1) << 0))
  (((44) << 24) | ((0x0) << 16) | ((0x0) << 10) | ((0x0) << 9) | ((0x0) << 8) | ((0x0) << 4) | ((0x1) << 1) | ((0x1) << 0))
  (((45) << 24) | ((0x0) << 16) | ((0x0) << 10) | ((0x0) << 9) | ((0x0) << 8) | ((0x0) << 4) | ((0x1) << 1) | ((0x1) << 0))
  (((46) << 24) | ((0x0) << 16) | ((0x0) << 10) | ((0x0) << 9) | ((0x0) << 8) | ((0x0) << 4) | ((0x1) << 1) | ((0x1) << 0))
  (((47) << 24) | ((0x0) << 16) | ((0x0) << 10) | ((0x1) << 9) | ((0x1) << 8) | ((0x1) << 4) | ((0x0) << 1) | ((0x1) << 0))
  (((48) << 24) | ((0x0) << 16) | ((0x0) << 10) | ((0x1) << 9) | ((0x0) << 8) | ((0x1) << 4) | ((0x0) << 1) | ((0x1) << 0))
  (((49) << 24) | ((0x0) << 16) | ((0x0) << 10) | ((0x1) << 9) | ((0x0) << 8) | ((0x1) << 4) | ((0x0) << 1) | ((0x1) << 0))
  (((50) << 24) | ((0x0) << 16) | ((0x0) << 10) | ((0x0) << 9) | ((0x0) << 8) | ((0x0) << 4) | ((0x1) << 1) | ((0x1) << 0))
  (((51) << 24) | ((0x0) << 16) | ((0x0) << 10) | ((0x0) << 9) | ((0x0) << 8) | ((0x0) << 4) | ((0x1) << 1) | ((0x1) << 0))
  (((52) << 24) | ((0x0) << 16) | ((0x0) << 10) | ((0x1) << 9) | ((0x0) << 8) | ((0x1) << 4) | ((0x0) << 1) | ((0x1) << 0))
  (((54) << 24) | ((0x0) << 16) | ((0x0) << 10) | ((0x1) << 9) | ((0x0) << 8) | ((0x1) << 4) | ((0x0) << 1) | ((0x1) << 0))
  (((55) << 24) | ((0x0) << 16) | ((0x0) << 10) | ((0x0) << 9) | ((0x0) << 8) | ((0x0) << 4) | ((0x1) << 1) | ((0x1) << 0))
  (((56) << 24) | ((0x0) << 16) | ((0x0) << 10) | ((0x0) << 9) | ((0x0) << 8) | ((0x0) << 4) | ((0x1) << 1) | ((0x1) << 0))
  (((57) << 24) | ((0x0) << 16) | ((0x0) << 10) | ((0x1) << 9) | ((0x0) << 8) | ((0x1) << 4) | ((0x0) << 1) | ((0x1) << 0))
  (((58) << 24) | ((0x0) << 16) | ((0x0) << 10) | ((0x1) << 9) | ((0x0) << 8) | ((0x1) << 4) | ((0x0) << 1) | ((0x1) << 0))
  (((59) << 24) | ((0x0) << 16) | ((0x0) << 10) | ((0x0) << 9) | ((0x0) << 8) | ((0x2) << 4) | ((0x0) << 1) | ((0x1) << 0))
  (((60) << 24) | ((0x0) << 16) | ((0x0) << 10) | ((0x1) << 9) | ((0x0) << 8) | ((0x1) << 4) | ((0x0) << 1) | ((0x1) << 0))
  (((61) << 24) | ((0x0) << 16) | ((0x0) << 10) | ((0x0) << 9) | ((0x0) << 8) | ((0x0) << 4) | ((0x1) << 1) | ((0x1) << 0))
  (((70) << 24) | ((0x0) << 16) | ((0x0) << 10) | ((0x0) << 9) | ((0x0) << 8) | ((0x0) << 4) | ((0x1) << 1) | ((0x1) << 0))
  (((72) << 24) | ((0x0) << 16) | ((0x0) << 10) | ((0x0) << 9) | ((0x0) << 8) | ((0x0) << 4) | ((0x1) << 1) | ((0x1) << 0))
  (((71) << 24) | ((0x0) << 16) | ((0x0) << 10) | ((0x0) << 9) | ((0x0) << 8) | ((0x0) << 4) | ((0x1) << 1) | ((0x1) << 0))
  (((63) << 24) | ((0x0) << 16) | ((0x0) << 10) | ((0x1) << 9) | ((0x0) << 8) | ((0x1) << 4) | ((0x0) << 1) | ((0x1) << 0))
  (((66) << 24) | ((0x0) << 16) | ((0x0) << 10) | ((0x1) << 9) | ((0x0) << 8) | ((0x1) << 4) | ((0x0) << 1) | ((0x1) << 0))
  (((67) << 24) | ((0x0) << 16) | ((0x0) << 10) | ((0x1) << 9) | ((0x0) << 8) | ((0x1) << 4) | ((0x0) << 1) | ((0x1) << 0))
  (((68) << 24) | ((0x0) << 16) | ((0x0) << 10) | ((0x0) << 9) | ((0x0) << 8) | ((0x0) << 4) | ((0x1) << 1) | ((0x1) << 0))
  (((69) << 24) | ((0x0) << 16) | ((0x0) << 10) | ((0x0) << 9) | ((0x0) << 8) | ((0x2) << 4) | ((0x0) << 1) | ((0x1) << 0))
  (((73) << 24) | ((0x0) << 16) | ((0x1) << 10) | ((0x1) << 9) | ((0x1) << 8) | ((0x1) << 4) | ((0x0) << 1) | ((0x1) << 0))
  (((76) << 24) | ((0x0) << 16) | ((0x0) << 10) | ((0x1) << 9) | ((0x0) << 8) | ((0x1) << 4) | ((0x0) << 1) | ((0x1) << 0))
  (((77) << 24) | ((0x0) << 16) | ((0x0) << 10) | ((0x1) << 9) | ((0x0) << 8) | ((0x1) << 4) | ((0x0) << 1) | ((0x1) << 0))
  (((78) << 24) | ((0x0) << 16) | ((0x0) << 10) | ((0x1) << 9) | ((0x0) << 8) | ((0x1) << 4) | ((0x0) << 1) | ((0x1) << 0))
  (((79) << 24) | ((0x0) << 16) | ((0x0) << 10) | ((0x1) << 9) | ((0x0) << 8) | ((0x1) << 4) | ((0x0) << 1) | ((0x1) << 0))
  (((80) << 24) | ((0x0) << 16) | ((0x0) << 10) | ((0x1) << 9) | ((0x1) << 8) | ((0x1) << 4) | ((0x0) << 1) | ((0x1) << 0))
  (((119) << 24) | ((0x0) << 16) | ((0x0) << 10) | ((0x1) << 9) | ((0x0) << 8) | ((0x1) << 4) | ((0x0) << 1) | ((0x1) << 0))
  (((120) << 24) | ((0x0) << 16) | ((0x0) << 10) | ((0x1) << 9) | ((0x1) << 8) | ((0x1) << 4) | ((0x0) << 1) | ((0x1) << 0))
  (((121) << 24) | ((0x0) << 16) | ((0x0) << 10) | ((0x1) << 9) | ((0x0) << 8) | ((0x1) << 4) | ((0x0) << 1) | ((0x1) << 0))
  (((81) << 24) | ((0x0) << 16) | ((0x0) << 10) | ((0x1) << 9) | ((0x0) << 8) | ((0x1) << 4) | ((0x0) << 1) | ((0x1) << 0))
  (((122) << 24) | ((0x0) << 16) | ((0x0) << 10) | ((0x1) << 9) | ((0x0) << 8) | ((0x1) << 4) | ((0x0) << 1) | ((0x1) << 0))
  (((123) << 24) | ((0x0) << 16) | ((0x0) << 10) | ((0x1) << 9) | ((0x0) << 8) | ((0x1) << 4) | ((0x0) << 1) | ((0x1) << 0))
  (((84) << 24) | ((0x0) << 16) | ((0x0) << 10) | ((0x1) << 9) | ((0x0) << 8) | ((0x1) << 4) | ((0x0) << 1) | ((0x1) << 0))
  (((86) << 24) | ((0x0) << 16) | ((0x0) << 10) | ((0x1) << 9) | ((0x0) << 8) | ((0x1) << 4) | ((0x0) << 1) | ((0x1) << 0))
  (((87) << 24) | ((0x0) << 16) | ((0x0) << 10) | ((0x1) << 9) | ((0x0) << 8) | ((0x1) << 4) | ((0x0) << 1) | ((0x1) << 0))
  (((88) << 24) | ((0x0) << 16) | ((0x0) << 10) | ((0x0) << 9) | ((0x0) << 8) | ((0x0) << 4) | ((0x1) << 1) | ((0x1) << 0))
  (((89) << 24) | ((0x0) << 16) | ((0x0) << 10) | ((0x1) << 9) | ((0x0) << 8) | ((0x1) << 4) | ((0x0) << 1) | ((0x1) << 0))
  (((90) << 24) | ((0x0) << 16) | ((0x0) << 10) | ((0x1) << 9) | ((0x0) << 8) | ((0x1) << 4) | ((0x0) << 1) | ((0x1) << 0))
  (((92) << 24) | ((0x0) << 16) | ((0x1) << 10) | ((0x1) << 9) | ((0x1) << 8) | ((0x1) << 4) | ((0x0) << 1) | ((0x1) << 0))
  (((93) << 24) | ((0x0) << 16) | ((0x1) << 10) | ((0x1) << 9) | ((0x1) << 8) | ((0x1) << 4) | ((0x0) << 1) | ((0x1) << 0))
  (((94) << 24) | ((0x0) << 16) | ((0x1) << 10) | ((0x1) << 9) | ((0x1) << 8) | ((0x1) << 4) | ((0x0) << 1) | ((0x1) << 0))
  (((95) << 24) | ((0x0) << 16) | ((0x1) << 10) | ((0x1) << 9) | ((0x1) << 8) | ((0x1) << 4) | ((0x0) << 1) | ((0x1) << 0))
  (((96) << 24) | ((0x0) << 16) | ((0x0) << 10) | ((0x1) << 9) | ((0x0) << 8) | ((0x1) << 4) | ((0x0) << 1) | ((0x1) << 0))
  (((97) << 24) | ((0x0) << 16) | ((0x0) << 10) | ((0x1) << 9) | ((0x1) << 8) | ((0x2) << 4) | ((0x0) << 1) | ((0x1) << 0))
  (((98) << 24) | ((0x0) << 16) | ((0x1) << 10) | ((0x1) << 9) | ((0x1) << 8) | ((0x1) << 4) | ((0x0) << 1) | ((0x1) << 0))
  (((99) << 24) | ((0x0) << 16) | ((0x0) << 10) | ((0x1) << 9) | ((0x0) << 8) | ((0x1) << 4) | ((0x0) << 1) | ((0x1) << 0))
  (((100) << 24) | ((0x0) << 16) | ((0x0) << 10) | ((0x1) << 9) | ((0x1) << 8) | ((0x2) << 4) | ((0x0) << 1) | ((0x1) << 0))
  (((101) << 24) | ((0x0) << 16) | ((0x0) << 10) | ((0x0) << 9) | ((0x0) << 8) | ((0x2) << 4) | ((0x0) << 1) | ((0x1) << 0))
  (((102) << 24) | ((0x0) << 16) | ((0x0) << 10) | ((0x0) << 9) | ((0x0) << 8) | ((0x0) << 4) | ((0x1) << 1) | ((0x1) << 0))
  (((103) << 24) | ((0x0) << 16) | ((0x0) << 10) | ((0x0) << 9) | ((0x0) << 8) | ((0x2) << 4) | ((0x0) << 1) | ((0x1) << 0))
  (((104) << 24) | ((0x0) << 16) | ((0x0) << 10) | ((0x0) << 9) | ((0x0) << 8) | ((0x0) << 4) | ((0x1) << 1) | ((0x1) << 0))
  (((106) << 24) | ((0x0) << 16) | ((0x0) << 10) | ((0x1) << 9) | ((0x1) << 8) | ((0x1) << 4) | ((0x0) << 1) | ((0x1) << 0))
  (((107) << 24) | ((0x0) << 16) | ((0x0) << 10) | ((0x1) << 9) | ((0x0) << 8) | ((0x1) << 4) | ((0x0) << 1) | ((0x1) << 0))
  (((108) << 24) | ((0x0) << 16) | ((0x0) << 10) | ((0x1) << 9) | ((0x1) << 8) | ((0x1) << 4) | ((0x0) << 1) | ((0x1) << 0))
  (((109) << 24) | ((0x0) << 16) | ((0x0) << 10) | ((0x0) << 9) | ((0x0) << 8) | ((0x2) << 4) | ((0x0) << 1) | ((0x1) << 0))
  (((110) << 24) | ((0x0) << 16) | ((0x0) << 10) | ((0x1) << 9) | ((0x1) << 8) | ((0x1) << 4) | ((0x0) << 1) | ((0x1) << 0))
  (((112) << 24) | ((0x0) << 16) | ((0x0) << 10) | ((0x1) << 9) | ((0x0) << 8) | ((0x1) << 4) | ((0x0) << 1) | ((0x1) << 0))
  (((114) << 24) | ((0x0) << 16) | ((0x0) << 10) | ((0x0) << 9) | ((0x0) << 8) | ((0x0) << 4) | ((0x1) << 1) | ((0x1) << 0))
  (((115) << 24) | ((0x0) << 16) | ((0x0) << 10) | ((0x0) << 9) | ((0x0) << 8) | ((0x0) << 4) | ((0x1) << 1) | ((0x1) << 0))
  (((116) << 24) | ((0x0) << 16) | ((0x0) << 10) | ((0x0) << 9) | ((0x0) << 8) | ((0x0) << 4) | ((0x1) << 1) | ((0x1) << 0))
  (((117) << 24) | ((0x0) << 16) | ((0x0) << 10) | ((0x0) << 9) | ((0x0) << 8) | ((0x0) << 4) | ((0x1) << 1) | ((0x1) << 0))
  (((118) << 24) | ((0x0) << 16) | ((0x0) << 10) | ((0x0) << 9) | ((0x0) << 8) | ((0x2) << 4) | ((0x0) << 1) | ((0x1) << 0))
 >;
};

&fmc {
 st,protreg = <
  ((((0)) << 24) | ((0x0) << 16) | ((0x0) << 10) | ((0x0) << 9) | ((0x0) << 8) | ((0x0) << 4) | ((0x1) << 1) | ((0x1) << 0))
  ((((1)) << 24) | ((0x0) << 16) | ((0x0) << 10) | ((0x0) << 9) | ((0x0) << 8) | ((0x0) << 4) | ((0x1) << 1) | ((0x1) << 0))
  ((((2)) << 24) | ((0x0) << 16) | ((0x0) << 10) | ((0x0) << 9) | ((0x0) << 8) | ((0x0) << 4) | ((0x1) << 1) | ((0x1) << 0))
  ((((3)) << 24) | ((0x0) << 16) | ((0x0) << 10) | ((0x0) << 9) | ((0x0) << 8) | ((0x0) << 4) | ((0x1) << 1) | ((0x1) << 0))
  ((((4)) << 24) | ((0x0) << 16) | ((0x0) << 10) | ((0x0) << 9) | ((0x0) << 8) | ((0x0) << 4) | ((0x1) << 1) | ((0x1) << 0))
  ((((5)) << 24) | ((0x0) << 16) | ((0x0) << 10) | ((0x0) << 9) | ((0x0) << 8) | ((0x0) << 4) | ((0x1) << 1) | ((0x1) << 0))
 >;
};

&rtc {
 st,protreg = <
  ((((0)) << 24) | ((0x0) << 16) | ((0x0) << 10) | ((0x1) << 9) | ((0x0) << 8) | ((0x1) << 4) | ((0x0) << 1) | ((0x1) << 0))
  ((((1)) << 24) | ((0x0) << 16) | ((0x0) << 10) | ((0x0) << 9) | ((0x0) << 8) | ((0x2) << 4) | ((0x0) << 1) | ((0x1) << 0))
  ((((2)) << 24) | ((0x0) << 16) | ((0x0) << 10) | ((0x1) << 9) | ((0x0) << 8) | ((0x1) << 4) | ((0x0) << 1) | ((0x1) << 0))
  ((((3)) << 24) | ((0x0) << 16) | ((0x0) << 10) | ((0x1) << 9) | ((0x0) << 8) | ((0x1) << 4) | ((0x0) << 1) | ((0x1) << 0))
  ((((4)) << 24) | ((0x0) << 16) | ((0x0) << 10) | ((0x1) << 9) | ((0x0) << 8) | ((0x1) << 4) | ((0x0) << 1) | ((0x1) << 0))
  ((((5)) << 24) | ((0x0) << 16) | ((0x0) << 10) | ((0x1) << 9) | ((0x0) << 8) | ((0x1) << 4) | ((0x0) << 1) | ((0x1) << 0))
 >;
};

&tamp {
 st,protreg = <
  ((((0)) << 24) | ((0x0) << 16) | ((0x0) << 10) | ((0x1) << 9) | ((0x1) << 8) | ((0x1) << 4) | ((0x0) << 1) | ((0x1) << 0))
  ((((1)) << 24) | ((0x0) << 16) | ((0x0) << 10) | ((0x1) << 9) | ((0x1) << 8) | ((0x1) << 4) | ((0x0) << 1) | ((0x1) << 0))
  ((((2)) << 24) | ((0x0) << 16) | ((0x0) << 10) | ((0x1) << 9) | ((0x1) << 8) | ((0x2) << 4) | ((0x0) << 1) | ((0x1) << 0))
 >;
 st,backup-zones = <24 24 24 24 12 12 8>;
};

&pwr {
 st,protreg = <
  ((((0)) << 24) | ((0x0) << 16) | ((0x0) << 10) | ((0x1) << 9) | ((0x1) << 8) | ((0x1) << 4) | ((0x0) << 1) | ((0x1) << 0))
  ((((1)) << 24) | ((0x0) << 16) | ((0x0) << 10) | ((0x1) << 9) | ((0x1) << 8) | ((0x1) << 4) | ((0x0) << 1) | ((0x1) << 0))
  ((((2)) << 24) | ((0x0) << 16) | ((0x0) << 10) | ((0x1) << 9) | ((0x1) << 8) | ((0x1) << 4) | ((0x0) << 1) | ((0x1) << 0))
  ((((3)) << 24) | ((0x0) << 16) | ((0x0) << 10) | ((0x1) << 9) | ((0x1) << 8) | ((0x1) << 4) | ((0x0) << 1) | ((0x1) << 0))
  ((((4)) << 24) | ((0x0) << 16) | ((0x0) << 10) | ((0x1) << 9) | ((0x1) << 8) | ((0x1) << 4) | ((0x0) << 1) | ((0x1) << 0))
  ((((5)) << 24) | ((0x0) << 16) | ((0x0) << 10) | ((0x1) << 9) | ((0x1) << 8) | ((0x1) << 4) | ((0x0) << 1) | ((0x1) << 0))
  ((((6)) << 24) | ((0x0) << 16) | ((0x0) << 10) | ((0x1) << 9) | ((0x1) << 8) | ((0x1) << 4) | ((0x0) << 1) | ((0x1) << 0))
  (((((1) + 6)) << 24) | ((0x0) << 16) | ((0x0) << 10) | ((0x1) << 9) | ((0x0) << 8) | ((0x1) << 4) | ((0x0) << 1) | ((0x1) << 0))
  (((((2) + 6)) << 24) | ((0x0) << 16) | ((0x0) << 10) | ((0x0) << 9) | ((0x0) << 8) | ((0x0) << 4) | ((0x1) << 1) | ((0x1) << 0))
  (((((3) + 6)) << 24) | ((0x0) << 16) | ((0x0) << 10) | ((0x0) << 9) | ((0x0) << 8) | ((0x2) << 4) | ((0x0) << 1) | ((0x1) << 0))
  (((((4) + 6)) << 24) | ((0x0) << 16) | ((0x0) << 10) | ((0x0) << 9) | ((0x0) << 8) | ((0x0) << 4) | ((0x1) << 1) | ((0x1) << 0))
  (((((5) + 6)) << 24) | ((0x0) << 16) | ((0x0) << 10) | ((0x0) << 9) | ((0x0) << 8) | ((0x0) << 4) | ((0x1) << 1) | ((0x1) << 0))
  (((((6) + 6)) << 24) | ((0x0) << 16) | ((0x0) << 10) | ((0x0) << 9) | ((0x0) << 8) | ((0x0) << 4) | ((0x1) << 1) | ((0x1) << 0))
 >;
};

&exti1 {
 st,proccid = <1 0x1>, <2 0x2>;
 st,protreg = <
  ((((0)) << 24) | ((0x0) << 16) | ((0x0) << 10) | ((0x0) << 9) | ((0x0) << 8) | ((0x0) << 4) | ((0x0) << 1) | ((0x0) << 0))
  ((((1)) << 24) | ((0x0) << 16) | ((0x0) << 10) | ((0x0) << 9) | ((0x0) << 8) | ((0x0) << 4) | ((0x0) << 1) | ((0x0) << 0))
  ((((2)) << 24) | ((0x0) << 16) | ((0x0) << 10) | ((0x0) << 9) | ((0x0) << 8) | ((0x0) << 4) | ((0x0) << 1) | ((0x0) << 0))
  ((((3)) << 24) | ((0x0) << 16) | ((0x0) << 10) | ((0x0) << 9) | ((0x0) << 8) | ((0x0) << 4) | ((0x0) << 1) | ((0x0) << 0))
  ((((4)) << 24) | ((0x0) << 16) | ((0x0) << 10) | ((0x0) << 9) | ((0x0) << 8) | ((0x0) << 4) | ((0x0) << 1) | ((0x0) << 0))
  ((((5)) << 24) | ((0x0) << 16) | ((0x0) << 10) | ((0x0) << 9) | ((0x0) << 8) | ((0x0) << 4) | ((0x0) << 1) | ((0x0) << 0))
  ((((6)) << 24) | ((0x0) << 16) | ((0x0) << 10) | ((0x0) << 9) | ((0x0) << 8) | ((0x0) << 4) | ((0x0) << 1) | ((0x0) << 0))
  ((((7)) << 24) | ((0x0) << 16) | ((0x0) << 10) | ((0x0) << 9) | ((0x0) << 8) | ((0x0) << 4) | ((0x0) << 1) | ((0x0) << 0))
  ((((8)) << 24) | ((0x0) << 16) | ((0x0) << 10) | ((0x0) << 9) | ((0x0) << 8) | ((0x0) << 4) | ((0x0) << 1) | ((0x0) << 0))
  ((((9)) << 24) | ((0x0) << 16) | ((0x0) << 10) | ((0x0) << 9) | ((0x0) << 8) | ((0x0) << 4) | ((0x0) << 1) | ((0x0) << 0))
  ((((10)) << 24) | ((0x0) << 16) | ((0x0) << 10) | ((0x0) << 9) | ((0x0) << 8) | ((0x0) << 4) | ((0x0) << 1) | ((0x0) << 0))
  ((((11)) << 24) | ((0x0) << 16) | ((0x0) << 10) | ((0x0) << 9) | ((0x0) << 8) | ((0x0) << 4) | ((0x0) << 1) | ((0x0) << 0))
  ((((12)) << 24) | ((0x0) << 16) | ((0x0) << 10) | ((0x0) << 9) | ((0x0) << 8) | ((0x0) << 4) | ((0x0) << 1) | ((0x0) << 0))
  ((((13)) << 24) | ((0x0) << 16) | ((0x0) << 10) | ((0x0) << 9) | ((0x0) << 8) | ((0x0) << 4) | ((0x0) << 1) | ((0x0) << 0))
  ((((14)) << 24) | ((0x0) << 16) | ((0x0) << 10) | ((0x0) << 9) | ((0x0) << 8) | ((0x0) << 4) | ((0x0) << 1) | ((0x0) << 0))
  ((((15)) << 24) | ((0x0) << 16) | ((0x0) << 10) | ((0x0) << 9) | ((0x0) << 8) | ((0x0) << 4) | ((0x0) << 1) | ((0x0) << 0))
  ((((16)) << 24) | ((0x0) << 16) | ((0x0) << 10) | ((0x1) << 9) | ((0x1) << 8) | ((0x1) << 4) | ((0x0) << 1) | ((0x1) << 0))
  ((((17)) << 24) | ((0x0) << 16) | ((0x0) << 10) | ((0x1) << 9) | ((0x1) << 8) | ((0x1) << 4) | ((0x0) << 1) | ((0x1) << 0))
  ((((18)) << 24) | ((0x0) << 16) | ((0x0) << 10) | ((0x1) << 9) | ((0x1) << 8) | ((0x1) << 4) | ((0x0) << 1) | ((0x1) << 0))
  ((((19)) << 24) | ((0x0) << 16) | ((0x0) << 10) | ((0x1) << 9) | ((0x1) << 8) | ((0x1) << 4) | ((0x0) << 1) | ((0x1) << 0))
  ((((21)) << 24) | ((0x0) << 16) | ((0x0) << 10) | ((0x0) << 9) | ((0x0) << 8) | ((0x2) << 4) | ((0x0) << 1) | ((0x1) << 0))
  ((((22)) << 24) | ((0x0) << 16) | ((0x0) << 10) | ((0x0) << 9) | ((0x0) << 8) | ((0x2) << 4) | ((0x0) << 1) | ((0x1) << 0))
  ((((23)) << 24) | ((0x0) << 16) | ((0x0) << 10) | ((0x0) << 9) | ((0x0) << 8) | ((0x0) << 4) | ((0x0) << 1) | ((0x0) << 0))
  ((((24)) << 24) | ((0x0) << 16) | ((0x0) << 10) | ((0x0) << 9) | ((0x0) << 8) | ((0x0) << 4) | ((0x0) << 1) | ((0x0) << 0))
  ((((25)) << 24) | ((0x0) << 16) | ((0x0) << 10) | ((0x0) << 9) | ((0x0) << 8) | ((0x0) << 4) | ((0x0) << 1) | ((0x0) << 0))
  ((((26)) << 24) | ((0x0) << 16) | ((0x0) << 10) | ((0x1) << 9) | ((0x0) << 8) | ((0x1) << 4) | ((0x0) << 1) | ((0x1) << 0))
  ((((27)) << 24) | ((0x0) << 16) | ((0x0) << 10) | ((0x1) << 9) | ((0x0) << 8) | ((0x1) << 4) | ((0x0) << 1) | ((0x1) << 0))
  ((((28)) << 24) | ((0x0) << 16) | ((0x0) << 10) | ((0x0) << 9) | ((0x0) << 8) | ((0x0) << 4) | ((0x0) << 1) | ((0x0) << 0))
  ((((29)) << 24) | ((0x0) << 16) | ((0x0) << 10) | ((0x0) << 9) | ((0x0) << 8) | ((0x2) << 4) | ((0x0) << 1) | ((0x1) << 0))
  ((((30)) << 24) | ((0x0) << 16) | ((0x0) << 10) | ((0x0) << 9) | ((0x0) << 8) | ((0x0) << 4) | ((0x0) << 1) | ((0x0) << 0))
  ((((31)) << 24) | ((0x0) << 16) | ((0x0) << 10) | ((0x0) << 9) | ((0x0) << 8) | ((0x2) << 4) | ((0x0) << 1) | ((0x1) << 0))
  ((((32)) << 24) | ((0x0) << 16) | ((0x0) << 10) | ((0x0) << 9) | ((0x0) << 8) | ((0x0) << 4) | ((0x0) << 1) | ((0x0) << 0))
  ((((33)) << 24) | ((0x0) << 16) | ((0x0) << 10) | ((0x0) << 9) | ((0x0) << 8) | ((0x0) << 4) | ((0x0) << 1) | ((0x0) << 0))
  ((((34)) << 24) | ((0x0) << 16) | ((0x0) << 10) | ((0x0) << 9) | ((0x0) << 8) | ((0x0) << 4) | ((0x0) << 1) | ((0x0) << 0))
  ((((36)) << 24) | ((0x0) << 16) | ((0x0) << 10) | ((0x0) << 9) | ((0x0) << 8) | ((0x0) << 4) | ((0x0) << 1) | ((0x0) << 0))
  ((((37)) << 24) | ((0x0) << 16) | ((0x0) << 10) | ((0x1) << 9) | ((0x0) << 8) | ((0x1) << 4) | ((0x0) << 1) | ((0x1) << 0))
  ((((38)) << 24) | ((0x0) << 16) | ((0x0) << 10) | ((0x0) << 9) | ((0x0) << 8) | ((0x0) << 4) | ((0x0) << 1) | ((0x0) << 0))
  ((((39)) << 24) | ((0x0) << 16) | ((0x0) << 10) | ((0x0) << 9) | ((0x0) << 8) | ((0x0) << 4) | ((0x0) << 1) | ((0x0) << 0))
  ((((40)) << 24) | ((0x0) << 16) | ((0x0) << 10) | ((0x0) << 9) | ((0x0) << 8) | ((0x0) << 4) | ((0x0) << 1) | ((0x0) << 0))
  ((((41)) << 24) | ((0x0) << 16) | ((0x0) << 10) | ((0x1) << 9) | ((0x0) << 8) | ((0x1) << 4) | ((0x0) << 1) | ((0x1) << 0))
  ((((42)) << 24) | ((0x0) << 16) | ((0x0) << 10) | ((0x0) << 9) | ((0x0) << 8) | ((0x0) << 4) | ((0x0) << 1) | ((0x0) << 0))
  ((((43)) << 24) | ((0x0) << 16) | ((0x0) << 10) | ((0x1) << 9) | ((0x0) << 8) | ((0x1) << 4) | ((0x0) << 1) | ((0x1) << 0))
  ((((44)) << 24) | ((0x0) << 16) | ((0x0) << 10) | ((0x1) << 9) | ((0x0) << 8) | ((0x1) << 4) | ((0x0) << 1) | ((0x1) << 0))
  ((((45)) << 24) | ((0x0) << 16) | ((0x0) << 10) | ((0x1) << 9) | ((0x0) << 8) | ((0x1) << 4) | ((0x0) << 1) | ((0x1) << 0))
  ((((46)) << 24) | ((0x0) << 16) | ((0x0) << 10) | ((0x0) << 9) | ((0x0) << 8) | ((0x0) << 4) | ((0x0) << 1) | ((0x0) << 0))
  ((((47)) << 24) | ((0x0) << 16) | ((0x0) << 10) | ((0x1) << 9) | ((0x1) << 8) | ((0x1) << 4) | ((0x0) << 1) | ((0x1) << 0))
  ((((48)) << 24) | ((0x0) << 16) | ((0x0) << 10) | ((0x1) << 9) | ((0x0) << 8) | ((0x1) << 4) | ((0x0) << 1) | ((0x1) << 0))
  ((((49)) << 24) | ((0x0) << 16) | ((0x0) << 10) | ((0x0) << 9) | ((0x0) << 8) | ((0x0) << 4) | ((0x0) << 1) | ((0x0) << 0))
  ((((50)) << 24) | ((0x0) << 16) | ((0x0) << 10) | ((0x1) << 9) | ((0x1) << 8) | ((0x1) << 4) | ((0x0) << 1) | ((0x1) << 0))
  ((((52)) << 24) | ((0x0) << 16) | ((0x0) << 10) | ((0x0) << 9) | ((0x0) << 8) | ((0x0) << 4) | ((0x0) << 1) | ((0x0) << 0))
  ((((53)) << 24) | ((0x0) << 16) | ((0x0) << 10) | ((0x0) << 9) | ((0x0) << 8) | ((0x0) << 4) | ((0x0) << 1) | ((0x0) << 0))
  ((((54)) << 24) | ((0x0) << 16) | ((0x0) << 10) | ((0x0) << 9) | ((0x0) << 8) | ((0x0) << 4) | ((0x0) << 1) | ((0x0) << 0))
  ((((55)) << 24) | ((0x0) << 16) | ((0x0) << 10) | ((0x0) << 9) | ((0x0) << 8) | ((0x0) << 4) | ((0x0) << 1) | ((0x0) << 0))
  ((((56)) << 24) | ((0x0) << 16) | ((0x0) << 10) | ((0x0) << 9) | ((0x0) << 8) | ((0x0) << 4) | ((0x0) << 1) | ((0x0) << 0))
  ((((57)) << 24) | ((0x0) << 16) | ((0x0) << 10) | ((0x0) << 9) | ((0x0) << 8) | ((0x0) << 4) | ((0x0) << 1) | ((0x0) << 0))
  ((((59)) << 24) | ((0x0) << 16) | ((0x0) << 10) | ((0x1) << 9) | ((0x0) << 8) | ((0x1) << 4) | ((0x0) << 1) | ((0x1) << 0))
  ((((60)) << 24) | ((0x0) << 16) | ((0x0) << 10) | ((0x0) << 9) | ((0x0) << 8) | ((0x2) << 4) | ((0x0) << 1) | ((0x1) << 0))
  ((((61)) << 24) | ((0x0) << 16) | ((0x0) << 10) | ((0x1) << 9) | ((0x1) << 8) | ((0x1) << 4) | ((0x0) << 1) | ((0x1) << 0))
  ((((62)) << 24) | ((0x0) << 16) | ((0x0) << 10) | ((0x1) << 9) | ((0x1) << 8) | ((0x2) << 4) | ((0x0) << 1) | ((0x1) << 0))
  ((((64)) << 24) | ((0x0) << 16) | ((0x0) << 10) | ((0x0) << 9) | ((0x0) << 8) | ((0x0) << 4) | ((0x0) << 1) | ((0x0) << 0))
  ((((65)) << 24) | ((0x0) << 16) | ((0x0) << 10) | ((0x0) << 9) | ((0x0) << 8) | ((0x0) << 4) | ((0x0) << 1) | ((0x0) << 0))
  ((((67)) << 24) | ((0x0) << 16) | ((0x0) << 10) | ((0x0) << 9) | ((0x0) << 8) | ((0x2) << 4) | ((0x0) << 1) | ((0x1) << 0))
  ((((68)) << 24) | ((0x0) << 16) | ((0x0) << 10) | ((0x1) << 9) | ((0x0) << 8) | ((0x1) << 4) | ((0x0) << 1) | ((0x1) << 0))
  ((((69)) << 24) | ((0x0) << 16) | ((0x0) << 10) | ((0x1) << 9) | ((0x0) << 8) | ((0x1) << 4) | ((0x0) << 1) | ((0x1) << 0))
  ((((70)) << 24) | ((0x0) << 16) | ((0x0) << 10) | ((0x0) << 9) | ((0x0) << 8) | ((0x0) << 4) | ((0x0) << 1) | ((0x0) << 0))
  ((((71)) << 24) | ((0x0) << 16) | ((0x0) << 10) | ((0x0) << 9) | ((0x0) << 8) | ((0x0) << 4) | ((0x0) << 1) | ((0x0) << 0))
  ((((72)) << 24) | ((0x0) << 16) | ((0x0) << 10) | ((0x0) << 9) | ((0x0) << 8) | ((0x0) << 4) | ((0x0) << 1) | ((0x0) << 0))
  ((((73)) << 24) | ((0x0) << 16) | ((0x0) << 10) | ((0x1) << 9) | ((0x0) << 8) | ((0x1) << 4) | ((0x0) << 1) | ((0x1) << 0))
  ((((74)) << 24) | ((0x0) << 16) | ((0x0) << 10) | ((0x0) << 9) | ((0x0) << 8) | ((0x0) << 4) | ((0x0) << 1) | ((0x0) << 0))
  ((((75)) << 24) | ((0x0) << 16) | ((0x0) << 10) | ((0x0) << 9) | ((0x0) << 8) | ((0x0) << 4) | ((0x0) << 1) | ((0x0) << 0))
  ((((76)) << 24) | ((0x0) << 16) | ((0x0) << 10) | ((0x0) << 9) | ((0x0) << 8) | ((0x0) << 4) | ((0x0) << 1) | ((0x0) << 0))
  ((((77)) << 24) | ((0x0) << 16) | ((0x0) << 10) | ((0x1) << 9) | ((0x0) << 8) | ((0x1) << 4) | ((0x0) << 1) | ((0x1) << 0))
  ((((78)) << 24) | ((0x0) << 16) | ((0x0) << 10) | ((0x1) << 9) | ((0x0) << 8) | ((0x1) << 4) | ((0x0) << 1) | ((0x1) << 0))
  ((((79)) << 24) | ((0x0) << 16) | ((0x0) << 10) | ((0x1) << 9) | ((0x0) << 8) | ((0x1) << 4) | ((0x0) << 1) | ((0x1) << 0))
  ((((80)) << 24) | ((0x0) << 16) | ((0x0) << 10) | ((0x0) << 9) | ((0x0) << 8) | ((0x2) << 4) | ((0x0) << 1) | ((0x1) << 0))
  ((((81)) << 24) | ((0x0) << 16) | ((0x0) << 10) | ((0x0) << 9) | ((0x0) << 8) | ((0x2) << 4) | ((0x0) << 1) | ((0x1) << 0))
  ((((82)) << 24) | ((0x0) << 16) | ((0x0) << 10) | ((0x0) << 9) | ((0x0) << 8) | ((0x2) << 4) | ((0x0) << 1) | ((0x1) << 0))
  ((((83)) << 24) | ((0x0) << 16) | ((0x0) << 10) | ((0x0) << 9) | ((0x0) << 8) | ((0x0) << 4) | ((0x0) << 1) | ((0x0) << 0))
  ((((84)) << 24) | ((0x0) << 16) | ((0x0) << 10) | ((0x0) << 9) | ((0x0) << 8) | ((0x0) << 4) | ((0x0) << 1) | ((0x0) << 0))
 >;
};

&exti2 {
 st,proccid = <1 0x1>, <2 0x2>, <3 0x3>;
 st,protreg = <
  ((((0)) << 24) | ((0x0) << 16) | ((0x0) << 10) | ((0x0) << 9) | ((0x0) << 8) | ((0x0) << 4) | ((0x0) << 1) | ((0x0) << 0))
  ((((1)) << 24) | ((0x0) << 16) | ((0x0) << 10) | ((0x0) << 9) | ((0x0) << 8) | ((0x0) << 4) | ((0x0) << 1) | ((0x0) << 0))
  ((((2)) << 24) | ((0x0) << 16) | ((0x0) << 10) | ((0x0) << 9) | ((0x0) << 8) | ((0x0) << 4) | ((0x0) << 1) | ((0x0) << 0))
  ((((3)) << 24) | ((0x0) << 16) | ((0x0) << 10) | ((0x0) << 9) | ((0x0) << 8) | ((0x0) << 4) | ((0x0) << 1) | ((0x0) << 0))
  ((((4)) << 24) | ((0x0) << 16) | ((0x0) << 10) | ((0x0) << 9) | ((0x0) << 8) | ((0x0) << 4) | ((0x0) << 1) | ((0x0) << 0))
  ((((5)) << 24) | ((0x0) << 16) | ((0x0) << 10) | ((0x0) << 9) | ((0x0) << 8) | ((0x0) << 4) | ((0x0) << 1) | ((0x0) << 0))
  ((((6)) << 24) | ((0x0) << 16) | ((0x0) << 10) | ((0x0) << 9) | ((0x0) << 8) | ((0x0) << 4) | ((0x0) << 1) | ((0x0) << 0))
  ((((7)) << 24) | ((0x0) << 16) | ((0x0) << 10) | ((0x0) << 9) | ((0x0) << 8) | ((0x0) << 4) | ((0x0) << 1) | ((0x0) << 0))
  ((((8)) << 24) | ((0x0) << 16) | ((0x0) << 10) | ((0x0) << 9) | ((0x0) << 8) | ((0x0) << 4) | ((0x0) << 1) | ((0x0) << 0))
  ((((9)) << 24) | ((0x0) << 16) | ((0x0) << 10) | ((0x0) << 9) | ((0x0) << 8) | ((0x0) << 4) | ((0x0) << 1) | ((0x0) << 0))
  ((((10)) << 24) | ((0x0) << 16) | ((0x0) << 10) | ((0x0) << 9) | ((0x0) << 8) | ((0x0) << 4) | ((0x0) << 1) | ((0x0) << 0))
  ((((11)) << 24) | ((0x0) << 16) | ((0x0) << 10) | ((0x0) << 9) | ((0x0) << 8) | ((0x0) << 4) | ((0x0) << 1) | ((0x0) << 0))
  ((((12)) << 24) | ((0x0) << 16) | ((0x0) << 10) | ((0x0) << 9) | ((0x0) << 8) | ((0x0) << 4) | ((0x0) << 1) | ((0x0) << 0))
  ((((13)) << 24) | ((0x0) << 16) | ((0x0) << 10) | ((0x0) << 9) | ((0x0) << 8) | ((0x0) << 4) | ((0x0) << 1) | ((0x0) << 0))
  ((((14)) << 24) | ((0x0) << 16) | ((0x0) << 10) | ((0x0) << 9) | ((0x0) << 8) | ((0x0) << 4) | ((0x0) << 1) | ((0x0) << 0))
  ((((15)) << 24) | ((0x0) << 16) | ((0x0) << 10) | ((0x0) << 9) | ((0x0) << 8) | ((0x0) << 4) | ((0x0) << 1) | ((0x0) << 0))
  ((((16)) << 24) | ((0x0) << 16) | ((0x0) << 10) | ((0x1) << 9) | ((0x0) << 8) | ((0x1) << 4) | ((0x0) << 1) | ((0x1) << 0))
  ((((17)) << 24) | ((0x0) << 16) | ((0x0) << 10) | ((0x1) << 9) | ((0x0) << 8) | ((0x1) << 4) | ((0x0) << 1) | ((0x1) << 0))
  ((((18)) << 24) | ((0x0) << 16) | ((0x0) << 10) | ((0x0) << 9) | ((0x0) << 8) | ((0x2) << 4) | ((0x0) << 1) | ((0x1) << 0))
  ((((19)) << 24) | ((0x0) << 16) | ((0x0) << 10) | ((0x0) << 9) | ((0x0) << 8) | ((0x2) << 4) | ((0x0) << 1) | ((0x1) << 0))
  ((((20)) << 24) | ((0x0) << 16) | ((0x0) << 10) | ((0x0) << 9) | ((0x0) << 8) | ((0x0) << 4) | ((0x0) << 1) | ((0x0) << 0))
  ((((21)) << 24) | ((0x0) << 16) | ((0x0) << 10) | ((0x1) << 9) | ((0x1) << 8) | ((0x1) << 4) | ((0x0) << 1) | ((0x1) << 0))
  ((((22)) << 24) | ((0x0) << 16) | ((0x0) << 10) | ((0x1) << 9) | ((0x1) << 8) | ((0x1) << 4) | ((0x0) << 1) | ((0x1) << 0))
  ((((23)) << 24) | ((0x0) << 16) | ((0x0) << 10) | ((0x1) << 9) | ((0x1) << 8) | ((0x2) << 4) | ((0x0) << 1) | ((0x1) << 0))
  ((((24)) << 24) | ((0x0) << 16) | ((0x0) << 10) | ((0x1) << 9) | ((0x1) << 8) | ((0x2) << 4) | ((0x0) << 1) | ((0x1) << 0))
  ((((25)) << 24) | ((0x0) << 16) | ((0x0) << 10) | ((0x1) << 9) | ((0x0) << 8) | ((0x1) << 4) | ((0x0) << 1) | ((0x1) << 0))
  ((((26)) << 24) | ((0x0) << 16) | ((0x0) << 10) | ((0x0) << 9) | ((0x0) << 8) | ((0x0) << 4) | ((0x0) << 1) | ((0x0) << 0))
  ((((27)) << 24) | ((0x0) << 16) | ((0x0) << 10) | ((0x0) << 9) | ((0x0) << 8) | ((0x0) << 4) | ((0x0) << 1) | ((0x0) << 0))
  ((((29)) << 24) | ((0x0) << 16) | ((0x0) << 10) | ((0x1) << 9) | ((0x0) << 8) | ((0x1) << 4) | ((0x0) << 1) | ((0x1) << 0))
  ((((30)) << 24) | ((0x0) << 16) | ((0x0) << 10) | ((0x1) << 9) | ((0x0) << 8) | ((0x1) << 4) | ((0x0) << 1) | ((0x1) << 0))
  ((((31)) << 24) | ((0x0) << 16) | ((0x0) << 10) | ((0x1) << 9) | ((0x0) << 8) | ((0x1) << 4) | ((0x0) << 1) | ((0x1) << 0))
  ((((33)) << 24) | ((0x0) << 16) | ((0x0) << 10) | ((0x0) << 9) | ((0x0) << 8) | ((0x0) << 4) | ((0x0) << 1) | ((0x0) << 0))
  ((((34)) << 24) | ((0x0) << 16) | ((0x0) << 10) | ((0x1) << 9) | ((0x0) << 8) | ((0x1) << 4) | ((0x0) << 1) | ((0x1) << 0))
  ((((35)) << 24) | ((0x0) << 16) | ((0x0) << 10) | ((0x0) << 9) | ((0x0) << 8) | ((0x2) << 4) | ((0x0) << 1) | ((0x1) << 0))
  ((((36)) << 24) | ((0x0) << 16) | ((0x0) << 10) | ((0x0) << 9) | ((0x0) << 8) | ((0x0) << 4) | ((0x0) << 1) | ((0x0) << 0))
  ((((37)) << 24) | ((0x0) << 16) | ((0x0) << 10) | ((0x1) << 9) | ((0x1) << 8) | ((0x1) << 4) | ((0x0) << 1) | ((0x1) << 0))
  ((((38)) << 24) | ((0x0) << 16) | ((0x0) << 10) | ((0x1) << 9) | ((0x1) << 8) | ((0x2) << 4) | ((0x0) << 1) | ((0x1) << 0))
  ((((40)) << 24) | ((0x0) << 16) | ((0x0) << 10) | ((0x1) << 9) | ((0x0) << 8) | ((0x1) << 4) | ((0x0) << 1) | ((0x1) << 0))
  ((((41)) << 24) | ((0x0) << 16) | ((0x0) << 10) | ((0x0) << 9) | ((0x0) << 8) | ((0x2) << 4) | ((0x0) << 1) | ((0x1) << 0))
  ((((42)) << 24) | ((0x0) << 16) | ((0x0) << 10) | ((0x0) << 9) | ((0x0) << 8) | ((0x0) << 4) | ((0x0) << 1) | ((0x0) << 0))
  ((((43)) << 24) | ((0x0) << 16) | ((0x0) << 10) | ((0x1) << 9) | ((0x1) << 8) | ((0x1) << 4) | ((0x0) << 1) | ((0x1) << 0))
  ((((44)) << 24) | ((0x0) << 16) | ((0x0) << 10) | ((0x1) << 9) | ((0x1) << 8) | ((0x2) << 4) | ((0x0) << 1) | ((0x1) << 0))
  ((((46)) << 24) | ((0x0) << 16) | ((0x0) << 10) | ((0x0) << 9) | ((0x0) << 8) | ((0x0) << 4) | ((0x0) << 1) | ((0x0) << 0))
  ((((47)) << 24) | ((0x0) << 16) | ((0x0) << 10) | ((0x1) << 9) | ((0x1) << 8) | ((0x1) << 4) | ((0x0) << 1) | ((0x1) << 0))
  ((((48)) << 24) | ((0x0) << 16) | ((0x0) << 10) | ((0x1) << 9) | ((0x0) << 8) | ((0x1) << 4) | ((0x0) << 1) | ((0x1) << 0))
  ((((49)) << 24) | ((0x0) << 16) | ((0x0) << 10) | ((0x1) << 9) | ((0x1) << 8) | ((0x2) << 4) | ((0x0) << 1) | ((0x1) << 0))
  ((((50)) << 24) | ((0x0) << 16) | ((0x0) << 10) | ((0x0) << 9) | ((0x0) << 8) | ((0x2) << 4) | ((0x0) << 1) | ((0x1) << 0))
  ((((51)) << 24) | ((0x0) << 16) | ((0x0) << 10) | ((0x0) << 9) | ((0x0) << 8) | ((0x0) << 4) | ((0x0) << 1) | ((0x0) << 0))
  ((((52)) << 24) | ((0x0) << 16) | ((0x0) << 10) | ((0x1) << 9) | ((0x1) << 8) | ((0x1) << 4) | ((0x0) << 1) | ((0x1) << 0))
  ((((53)) << 24) | ((0x0) << 16) | ((0x0) << 10) | ((0x1) << 9) | ((0x0) << 8) | ((0x1) << 4) | ((0x0) << 1) | ((0x1) << 0))
  ((((54)) << 24) | ((0x0) << 16) | ((0x0) << 10) | ((0x1) << 9) | ((0x1) << 8) | ((0x2) << 4) | ((0x0) << 1) | ((0x1) << 0))
  ((((55)) << 24) | ((0x0) << 16) | ((0x0) << 10) | ((0x0) << 9) | ((0x0) << 8) | ((0x2) << 4) | ((0x0) << 1) | ((0x1) << 0))
  ((((56)) << 24) | ((0x0) << 16) | ((0x0) << 10) | ((0x0) << 9) | ((0x0) << 8) | ((0x0) << 4) | ((0x0) << 1) | ((0x0) << 0))
  ((((59)) << 24) | ((0x0) << 16) | ((0x0) << 10) | ((0x0) << 9) | ((0x0) << 8) | ((0x0) << 4) | ((0x0) << 1) | ((0x0) << 0))
  ((((60)) << 24) | ((0x0) << 16) | ((0x0) << 10) | ((0x0) << 9) | ((0x0) << 8) | ((0x0) << 4) | ((0x0) << 1) | ((0x0) << 0))
  ((((61)) << 24) | ((0x0) << 16) | ((0x0) << 10) | ((0x1) << 9) | ((0x1) << 8) | ((0x1) << 4) | ((0x0) << 1) | ((0x1) << 0))
  ((((62)) << 24) | ((0x0) << 16) | ((0x0) << 10) | ((0x1) << 9) | ((0x1) << 8) | ((0x1) << 4) | ((0x0) << 1) | ((0x1) << 0))
  ((((63)) << 24) | ((0x0) << 16) | ((0x0) << 10) | ((0x1) << 9) | ((0x1) << 8) | ((0x2) << 4) | ((0x0) << 1) | ((0x1) << 0))
  ((((64)) << 24) | ((0x0) << 16) | ((0x0) << 10) | ((0x1) << 9) | ((0x1) << 8) | ((0x1) << 4) | ((0x0) << 1) | ((0x1) << 0))
  ((((65)) << 24) | ((0x0) << 16) | ((0x0) << 10) | ((0x1) << 9) | ((0x1) << 8) | ((0x1) << 4) | ((0x0) << 1) | ((0x1) << 0))
  ((((66)) << 24) | ((0x0) << 16) | ((0x0) << 10) | ((0x1) << 9) | ((0x1) << 8) | ((0x1) << 4) | ((0x0) << 1) | ((0x1) << 0))
  ((((67)) << 24) | ((0x0) << 16) | ((0x0) << 10) | ((0x1) << 9) | ((0x1) << 8) | ((0x1) << 4) | ((0x0) << 1) | ((0x1) << 0))
  ((((68)) << 24) | ((0x0) << 16) | ((0x0) << 10) | ((0x1) << 9) | ((0x1) << 8) | ((0x2) << 4) | ((0x0) << 1) | ((0x1) << 0))
  ((((69)) << 24) | ((0x0) << 16) | ((0x0) << 10) | ((0x0) << 9) | ((0x0) << 8) | ((0x0) << 4) | ((0x0) << 1) | ((0x0) << 0))
  ((((70)) << 24) | ((0x0) << 16) | ((0x0) << 10) | ((0x0) << 9) | ((0x0) << 8) | ((0x0) << 4) | ((0x0) << 1) | ((0x0) << 0))
  ((((76)) << 24) | ((0x0) << 16) | ((0x0) << 10) | ((0x1) << 9) | ((0x1) << 8) | ((0x1) << 4) | ((0x0) << 1) | ((0x1) << 0))
 >;
};

&gpioa {
 st,protreg = <
  ((((0)) << 24) | ((0x0) << 16) | ((0x0) << 10) | ((0x1) << 9) | ((0x0) << 8) | ((0x1) << 4) | ((0x0) << 1) | ((0x1) << 0))
  ((((1)) << 24) | ((0x0) << 16) | ((0x0) << 10) | ((0x1) << 9) | ((0x0) << 8) | ((0x1) << 4) | ((0x0) << 1) | ((0x1) << 0))
  ((((2)) << 24) | ((0x0) << 16) | ((0x0) << 10) | ((0x1) << 9) | ((0x0) << 8) | ((0x1) << 4) | ((0x0) << 1) | ((0x1) << 0))
  ((((3)) << 24) | ((0x0) << 16) | ((0x0) << 10) | ((0x1) << 9) | ((0x0) << 8) | ((0x2) << 4) | ((0x0) << 1) | ((0x1) << 0))
  ((((4)) << 24) | ((0x0) << 16) | ((0x0) << 10) | ((0x1) << 9) | ((0x0) << 8) | ((0x1) << 4) | ((0x0) << 1) | ((0x1) << 0))
  ((((5)) << 24) | ((0x0) << 16) | ((0x0) << 10) | ((0x0) << 9) | ((0x0) << 8) | ((0x2) << 4) | ((0x0) << 1) | ((0x1) << 0))
  ((((6)) << 24) | ((0x0) << 16) | ((0x0) << 10) | ((0x1) << 9) | ((0x0) << 8) | ((0x1) << 4) | ((0x0) << 1) | ((0x1) << 0))
  ((((7)) << 24) | ((0x0) << 16) | ((0x0) << 10) | ((0x1) << 9) | ((0x0) << 8) | ((0x1) << 4) | ((0x0) << 1) | ((0x1) << 0))
  ((((8)) << 24) | ((0x0) << 16) | ((0x0) << 10) | ((0x1) << 9) | ((0x0) << 8) | ((0x1) << 4) | ((0x0) << 1) | ((0x1) << 0))
  ((((9)) << 24) | ((0x0) << 16) | ((0x0) << 10) | ((0x1) << 9) | ((0x0) << 8) | ((0x1) << 4) | ((0x0) << 1) | ((0x1) << 0))
  ((((10)) << 24) | ((0x0) << 16) | ((0x0) << 10) | ((0x1) << 9) | ((0x0) << 8) | ((0x1) << 4) | ((0x0) << 1) | ((0x1) << 0))
  ((((11)) << 24) | ((0x0) << 16) | ((0x0) << 10) | ((0x1) << 9) | ((0x0) << 8) | ((0x1) << 4) | ((0x0) << 1) | ((0x1) << 0))
  ((((12)) << 24) | ((0x0) << 16) | ((0x0) << 10) | ((0x1) << 9) | ((0x0) << 8) | ((0x1) << 4) | ((0x0) << 1) | ((0x1) << 0))
  ((((13)) << 24) | ((0x0) << 16) | ((0x0) << 10) | ((0x1) << 9) | ((0x0) << 8) | ((0x1) << 4) | ((0x0) << 1) | ((0x1) << 0))
  ((((14)) << 24) | ((0x0) << 16) | ((0x0) << 10) | ((0x1) << 9) | ((0x0) << 8) | ((0x1) << 4) | ((0x0) << 1) | ((0x1) << 0))
  ((((15)) << 24) | ((0x0) << 16) | ((0x0) << 10) | ((0x1) << 9) | ((0x0) << 8) | ((0x1) << 4) | ((0x0) << 1) | ((0x1) << 0))
 >;
};

&gpiob {
 st,protreg = <
  ((((0)) << 24) | ((0x0) << 16) | ((0x0) << 10) | ((0x1) << 9) | ((0x0) << 8) | ((0x1) << 4) | ((0x0) << 1) | ((0x1) << 0))
  ((((1)) << 24) | ((0x0) << 16) | ((0x0) << 10) | ((0x1) << 9) | ((0x0) << 8) | ((0x1) << 4) | ((0x0) << 1) | ((0x1) << 0))
  ((((2)) << 24) | ((0x0) << 16) | ((0x0) << 10) | ((0x1) << 9) | ((0x0) << 8) | ((0x1) << 4) | ((0x0) << 1) | ((0x1) << 0))
  ((((3)) << 24) | ((0x0) << 16) | ((0x0) << 10) | ((0x1) << 9) | ((0x0) << 8) | ((0x1) << 4) | ((0x0) << 1) | ((0x1) << 0))
  ((((4)) << 24) | ((0x0) << 16) | ((0x0) << 10) | ((0x1) << 9) | ((0x0) << 8) | ((0x1) << 4) | ((0x0) << 1) | ((0x1) << 0))
  ((((5)) << 24) | ((0x0) << 16) | ((0x0) << 10) | ((0x1) << 9) | ((0x0) << 8) | ((0x1) << 4) | ((0x0) << 1) | ((0x1) << 0))
  ((((6)) << 24) | ((0x0) << 16) | ((0x0) << 10) | ((0x1) << 9) | ((0x0) << 8) | ((0x1) << 4) | ((0x0) << 1) | ((0x1) << 0))
  ((((7)) << 24) | ((0x0) << 16) | ((0x0) << 10) | ((0x1) << 9) | ((0x0) << 8) | ((0x1) << 4) | ((0x0) << 1) | ((0x1) << 0))
  ((((8)) << 24) | ((0x0) << 16) | ((0x0) << 10) | ((0x1) << 9) | ((0x0) << 8) | ((0x1) << 4) | ((0x0) << 1) | ((0x1) << 0))
  ((((9)) << 24) | ((0x0) << 16) | ((0x0) << 10) | ((0x1) << 9) | ((0x0) << 8) | ((0x1) << 4) | ((0x0) << 1) | ((0x1) << 0))
  ((((10)) << 24) | ((0x0) << 16) | ((0x0) << 10) | ((0x1) << 9) | ((0x0) << 8) | ((0x1) << 4) | ((0x0) << 1) | ((0x1) << 0))
  ((((11)) << 24) | ((0x0) << 16) | ((0x0) << 10) | ((0x1) << 9) | ((0x0) << 8) | ((0x1) << 4) | ((0x0) << 1) | ((0x1) << 0))
  ((((12)) << 24) | ((0x0) << 16) | ((0x0) << 10) | ((0x1) << 9) | ((0x0) << 8) | ((0x1) << 4) | ((0x0) << 1) | ((0x1) << 0))
  ((((13)) << 24) | ((0x0) << 16) | ((0x0) << 10) | ((0x1) << 9) | ((0x0) << 8) | ((0x1) << 4) | ((0x0) << 1) | ((0x1) << 0))
  ((((14)) << 24) | ((0x0) << 16) | ((0x0) << 10) | ((0x1) << 9) | ((0x0) << 8) | ((0x1) << 4) | ((0x0) << 1) | ((0x1) << 0))
  ((((15)) << 24) | ((0x0) << 16) | ((0x0) << 10) | ((0x1) << 9) | ((0x0) << 8) | ((0x1) << 4) | ((0x0) << 1) | ((0x1) << 0))
 >;
};

&gpioc {
 st,protreg = <
  ((((0)) << 24) | ((0x0) << 16) | ((0x0) << 10) | ((0x1) << 9) | ((0x0) << 8) | ((0x1) << 4) | ((0x0) << 1) | ((0x1) << 0))
  ((((1)) << 24) | ((0x0) << 16) | ((0x0) << 10) | ((0x1) << 9) | ((0x0) << 8) | ((0x1) << 4) | ((0x0) << 1) | ((0x1) << 0))
  ((((2)) << 24) | ((0x0) << 16) | ((0x0) << 10) | ((0x1) << 9) | ((0x0) << 8) | ((0x1) << 4) | ((0x0) << 1) | ((0x1) << 0))
  ((((3)) << 24) | ((0x0) << 16) | ((0x0) << 10) | ((0x0) << 9) | ((0x0) << 8) | ((0x2) << 4) | ((0x0) << 1) | ((0x1) << 0))
  ((((4)) << 24) | ((0x0) << 16) | ((0x0) << 10) | ((0x1) << 9) | ((0x0) << 8) | ((0x1) << 4) | ((0x0) << 1) | ((0x1) << 0))
  ((((5)) << 24) | ((0x0) << 16) | ((0x0) << 10) | ((0x1) << 9) | ((0x0) << 8) | ((0x1) << 4) | ((0x0) << 1) | ((0x1) << 0))
  ((((6)) << 24) | ((0x0) << 16) | ((0x0) << 10) | ((0x0) << 9) | ((0x0) << 8) | ((0x0) << 4) | ((0x1) << 1) | ((0x1) << 0))
  ((((7)) << 24) | ((0x0) << 16) | ((0x0) << 10) | ((0x1) << 9) | ((0x0) << 8) | ((0x1) << 4) | ((0x0) << 1) | ((0x1) << 0))
  ((((8)) << 24) | ((0x0) << 16) | ((0x0) << 10) | ((0x0) << 9) | ((0x0) << 8) | ((0x0) << 4) | ((0x1) << 1) | ((0x1) << 0))
  ((((9)) << 24) | ((0x0) << 16) | ((0x0) << 10) | ((0x0) << 9) | ((0x0) << 8) | ((0x0) << 4) | ((0x1) << 1) | ((0x1) << 0))
  ((((10)) << 24) | ((0x0) << 16) | ((0x0) << 10) | ((0x1) << 9) | ((0x0) << 8) | ((0x1) << 4) | ((0x0) << 1) | ((0x1) << 0))
  ((((11)) << 24) | ((0x0) << 16) | ((0x0) << 10) | ((0x1) << 9) | ((0x0) << 8) | ((0x1) << 4) | ((0x0) << 1) | ((0x1) << 0))
  ((((12)) << 24) | ((0x0) << 16) | ((0x0) << 10) | ((0x0) << 9) | ((0x0) << 8) | ((0x0) << 4) | ((0x1) << 1) | ((0x1) << 0))
  ((((13)) << 24) | ((0x0) << 16) | ((0x0) << 10) | ((0x0) << 9) | ((0x0) << 8) | ((0x0) << 4) | ((0x1) << 1) | ((0x1) << 0))
 >;
};

&gpiod {
 st,protreg = <
  ((((0)) << 24) | ((0x0) << 16) | ((0x0) << 10) | ((0x1) << 9) | ((0x0) << 8) | ((0x1) << 4) | ((0x0) << 1) | ((0x1) << 0))
  ((((1)) << 24) | ((0x0) << 16) | ((0x0) << 10) | ((0x1) << 9) | ((0x0) << 8) | ((0x1) << 4) | ((0x0) << 1) | ((0x1) << 0))
  ((((2)) << 24) | ((0x0) << 16) | ((0x0) << 10) | ((0x1) << 9) | ((0x0) << 8) | ((0x1) << 4) | ((0x0) << 1) | ((0x1) << 0))
  ((((3)) << 24) | ((0x0) << 16) | ((0x0) << 10) | ((0x1) << 9) | ((0x0) << 8) | ((0x1) << 4) | ((0x0) << 1) | ((0x1) << 0))
  ((((4)) << 24) | ((0x0) << 16) | ((0x0) << 10) | ((0x1) << 9) | ((0x0) << 8) | ((0x1) << 4) | ((0x0) << 1) | ((0x1) << 0))
  ((((5)) << 24) | ((0x0) << 16) | ((0x0) << 10) | ((0x0) << 9) | ((0x0) << 8) | ((0x0) << 4) | ((0x1) << 1) | ((0x1) << 0))
  ((((6)) << 24) | ((0x0) << 16) | ((0x0) << 10) | ((0x1) << 9) | ((0x0) << 8) | ((0x1) << 4) | ((0x0) << 1) | ((0x1) << 0))
  ((((7)) << 24) | ((0x0) << 16) | ((0x0) << 10) | ((0x0) << 9) | ((0x0) << 8) | ((0x0) << 4) | ((0x1) << 1) | ((0x1) << 0))
  ((((8)) << 24) | ((0x0) << 16) | ((0x0) << 10) | ((0x1) << 9) | ((0x0) << 8) | ((0x1) << 4) | ((0x0) << 1) | ((0x1) << 0))
  ((((9)) << 24) | ((0x0) << 16) | ((0x0) << 10) | ((0x1) << 9) | ((0x0) << 8) | ((0x1) << 4) | ((0x0) << 1) | ((0x1) << 0))
  ((((10)) << 24) | ((0x0) << 16) | ((0x0) << 10) | ((0x1) << 9) | ((0x0) << 8) | ((0x1) << 4) | ((0x0) << 1) | ((0x1) << 0))
  ((((11)) << 24) | ((0x0) << 16) | ((0x0) << 10) | ((0x1) << 9) | ((0x0) << 8) | ((0x1) << 4) | ((0x0) << 1) | ((0x1) << 0))
  ((((12)) << 24) | ((0x0) << 16) | ((0x0) << 10) | ((0x1) << 9) | ((0x0) << 8) | ((0x1) << 4) | ((0x0) << 1) | ((0x1) << 0))
  ((((13)) << 24) | ((0x0) << 16) | ((0x0) << 10) | ((0x1) << 9) | ((0x0) << 8) | ((0x1) << 4) | ((0x0) << 1) | ((0x1) << 0))
  ((((14)) << 24) | ((0x0) << 16) | ((0x0) << 10) | ((0x1) << 9) | ((0x1) << 8) | ((0x1) << 4) | ((0x0) << 1) | ((0x1) << 0))
  ((((15)) << 24) | ((0x0) << 16) | ((0x0) << 10) | ((0x1) << 9) | ((0x1) << 8) | ((0x1) << 4) | ((0x0) << 1) | ((0x1) << 0))
 >;
};

&gpioe {
 st,protreg = <
  ((((0)) << 24) | ((0x0) << 16) | ((0x0) << 10) | ((0x1) << 9) | ((0x0) << 8) | ((0x1) << 4) | ((0x0) << 1) | ((0x1) << 0))
  ((((1)) << 24) | ((0x0) << 16) | ((0x0) << 10) | ((0x1) << 9) | ((0x0) << 8) | ((0x1) << 4) | ((0x0) << 1) | ((0x1) << 0))
  ((((2)) << 24) | ((0x0) << 16) | ((0x0) << 10) | ((0x1) << 9) | ((0x0) << 8) | ((0x1) << 4) | ((0x0) << 1) | ((0x1) << 0))
  ((((3)) << 24) | ((0x0) << 16) | ((0x0) << 10) | ((0x1) << 9) | ((0x0) << 8) | ((0x1) << 4) | ((0x0) << 1) | ((0x1) << 0))
  ((((4)) << 24) | ((0x0) << 16) | ((0x0) << 10) | ((0x1) << 9) | ((0x0) << 8) | ((0x1) << 4) | ((0x0) << 1) | ((0x1) << 0))
  ((((5)) << 24) | ((0x0) << 16) | ((0x0) << 10) | ((0x1) << 9) | ((0x0) << 8) | ((0x1) << 4) | ((0x0) << 1) | ((0x1) << 0))
  ((((6)) << 24) | ((0x0) << 16) | ((0x0) << 10) | ((0x1) << 9) | ((0x0) << 8) | ((0x1) << 4) | ((0x0) << 1) | ((0x1) << 0))
  ((((7)) << 24) | ((0x0) << 16) | ((0x0) << 10) | ((0x1) << 9) | ((0x0) << 8) | ((0x1) << 4) | ((0x0) << 1) | ((0x1) << 0))
  ((((8)) << 24) | ((0x0) << 16) | ((0x0) << 10) | ((0x1) << 9) | ((0x0) << 8) | ((0x1) << 4) | ((0x0) << 1) | ((0x1) << 0))
  ((((9)) << 24) | ((0x0) << 16) | ((0x0) << 10) | ((0x1) << 9) | ((0x0) << 8) | ((0x1) << 4) | ((0x0) << 1) | ((0x1) << 0))
  ((((10)) << 24) | ((0x0) << 16) | ((0x0) << 10) | ((0x1) << 9) | ((0x0) << 8) | ((0x1) << 4) | ((0x0) << 1) | ((0x1) << 0))
  ((((11)) << 24) | ((0x0) << 16) | ((0x0) << 10) | ((0x1) << 9) | ((0x0) << 8) | ((0x1) << 4) | ((0x0) << 1) | ((0x1) << 0))
  ((((12)) << 24) | ((0x0) << 16) | ((0x0) << 10) | ((0x1) << 9) | ((0x0) << 8) | ((0x1) << 4) | ((0x0) << 1) | ((0x1) << 0))
  ((((13)) << 24) | ((0x0) << 16) | ((0x0) << 10) | ((0x1) << 9) | ((0x0) << 8) | ((0x1) << 4) | ((0x0) << 1) | ((0x1) << 0))
  ((((14)) << 24) | ((0x0) << 16) | ((0x0) << 10) | ((0x1) << 9) | ((0x0) << 8) | ((0x1) << 4) | ((0x0) << 1) | ((0x1) << 0))
  ((((15)) << 24) | ((0x0) << 16) | ((0x0) << 10) | ((0x1) << 9) | ((0x0) << 8) | ((0x1) << 4) | ((0x0) << 1) | ((0x1) << 0))
 >;
};

&gpiof {
 st,protreg = <
  ((((0)) << 24) | ((0x0) << 16) | ((0x0) << 10) | ((0x1) << 9) | ((0x0) << 8) | ((0x1) << 4) | ((0x0) << 1) | ((0x1) << 0))
  ((((1)) << 24) | ((0x0) << 16) | ((0x0) << 10) | ((0x1) << 9) | ((0x0) << 8) | ((0x1) << 4) | ((0x0) << 1) | ((0x1) << 0))
  ((((2)) << 24) | ((0x0) << 16) | ((0x0) << 10) | ((0x1) << 9) | ((0x0) << 8) | ((0x1) << 4) | ((0x0) << 1) | ((0x1) << 0))
  ((((3)) << 24) | ((0x0) << 16) | ((0x0) << 10) | ((0x1) << 9) | ((0x0) << 8) | ((0x1) << 4) | ((0x0) << 1) | ((0x1) << 0))
  ((((4)) << 24) | ((0x0) << 16) | ((0x0) << 10) | ((0x1) << 9) | ((0x0) << 8) | ((0x1) << 4) | ((0x0) << 1) | ((0x1) << 0))
  ((((5)) << 24) | ((0x0) << 16) | ((0x0) << 10) | ((0x0) << 9) | ((0x0) << 8) | ((0x2) << 4) | ((0x0) << 1) | ((0x1) << 0))
  ((((6)) << 24) | ((0x0) << 16) | ((0x0) << 10) | ((0x0) << 9) | ((0x0) << 8) | ((0x0) << 4) | ((0x1) << 1) | ((0x1) << 0))
  ((((7)) << 24) | ((0x0) << 16) | ((0x0) << 10) | ((0x1) << 9) | ((0x0) << 8) | ((0x1) << 4) | ((0x0) << 1) | ((0x1) << 0))
  ((((8)) << 24) | ((0x0) << 16) | ((0x0) << 10) | ((0x0) << 9) | ((0x0) << 8) | ((0x0) << 4) | ((0x1) << 1) | ((0x1) << 0))
  ((((9)) << 24) | ((0x0) << 16) | ((0x0) << 10) | ((0x0) << 9) | ((0x0) << 8) | ((0x0) << 4) | ((0x1) << 1) | ((0x1) << 0))
  ((((10)) << 24) | ((0x0) << 16) | ((0x0) << 10) | ((0x0) << 9) | ((0x0) << 8) | ((0x2) << 4) | ((0x0) << 1) | ((0x1) << 0))
  ((((11)) << 24) | ((0x0) << 16) | ((0x0) << 10) | ((0x1) << 9) | ((0x0) << 8) | ((0x1) << 4) | ((0x0) << 1) | ((0x1) << 0))
  ((((12)) << 24) | ((0x0) << 16) | ((0x0) << 10) | ((0x1) << 9) | ((0x0) << 8) | ((0x1) << 4) | ((0x0) << 1) | ((0x1) << 0))
  ((((13)) << 24) | ((0x0) << 16) | ((0x0) << 10) | ((0x0) << 9) | ((0x0) << 8) | ((0x2) << 4) | ((0x0) << 1) | ((0x1) << 0))
  ((((14)) << 24) | ((0x0) << 16) | ((0x0) << 10) | ((0x0) << 9) | ((0x0) << 8) | ((0x2) << 4) | ((0x0) << 1) | ((0x1) << 0))
  ((((15)) << 24) | ((0x0) << 16) | ((0x0) << 10) | ((0x0) << 9) | ((0x0) << 8) | ((0x2) << 4) | ((0x0) << 1) | ((0x1) << 0))
 >;
};

&gpiog {
 st,protreg = <
  ((((0)) << 24) | ((0x0) << 16) | ((0x0) << 10) | ((0x0) << 9) | ((0x0) << 8) | ((0x0) << 4) | ((0x1) << 1) | ((0x1) << 0))
  ((((1)) << 24) | ((0x0) << 16) | ((0x0) << 10) | ((0x0) << 9) | ((0x0) << 8) | ((0x2) << 4) | ((0x0) << 1) | ((0x1) << 0))
  ((((2)) << 24) | ((0x0) << 16) | ((0x0) << 10) | ((0x1) << 9) | ((0x0) << 8) | ((0x1) << 4) | ((0x0) << 1) | ((0x1) << 0))
  ((((3)) << 24) | ((0x0) << 16) | ((0x0) << 10) | ((0x0) << 9) | ((0x0) << 8) | ((0x0) << 4) | ((0x1) << 1) | ((0x1) << 0))
  ((((4)) << 24) | ((0x0) << 16) | ((0x0) << 10) | ((0x1) << 9) | ((0x0) << 8) | ((0x1) << 4) | ((0x0) << 1) | ((0x1) << 0))
  ((((5)) << 24) | ((0x0) << 16) | ((0x0) << 10) | ((0x0) << 9) | ((0x0) << 8) | ((0x2) << 4) | ((0x0) << 1) | ((0x1) << 0))
  ((((6)) << 24) | ((0x0) << 16) | ((0x0) << 10) | ((0x1) << 9) | ((0x0) << 8) | ((0x1) << 4) | ((0x0) << 1) | ((0x1) << 0))
  ((((7)) << 24) | ((0x0) << 16) | ((0x0) << 10) | ((0x1) << 9) | ((0x0) << 8) | ((0x1) << 4) | ((0x0) << 1) | ((0x1) << 0))
  ((((8)) << 24) | ((0x0) << 16) | ((0x0) << 10) | ((0x1) << 9) | ((0x0) << 8) | ((0x1) << 4) | ((0x0) << 1) | ((0x1) << 0))
  ((((9)) << 24) | ((0x0) << 16) | ((0x0) << 10) | ((0x0) << 9) | ((0x0) << 8) | ((0x2) << 4) | ((0x0) << 1) | ((0x1) << 0))
  ((((10)) << 24) | ((0x0) << 16) | ((0x0) << 10) | ((0x0) << 9) | ((0x0) << 8) | ((0x2) << 4) | ((0x0) << 1) | ((0x1) << 0))
  ((((11)) << 24) | ((0x0) << 16) | ((0x0) << 10) | ((0x1) << 9) | ((0x0) << 8) | ((0x1) << 4) | ((0x0) << 1) | ((0x1) << 0))
  ((((12)) << 24) | ((0x0) << 16) | ((0x0) << 10) | ((0x0) << 9) | ((0x0) << 8) | ((0x0) << 4) | ((0x1) << 1) | ((0x1) << 0))
  ((((13)) << 24) | ((0x0) << 16) | ((0x0) << 10) | ((0x0) << 9) | ((0x0) << 8) | ((0x2) << 4) | ((0x0) << 1) | ((0x1) << 0))
  ((((14)) << 24) | ((0x0) << 16) | ((0x0) << 10) | ((0x1) << 9) | ((0x0) << 8) | ((0x1) << 4) | ((0x0) << 1) | ((0x1) << 0))
  ((((15)) << 24) | ((0x0) << 16) | ((0x0) << 10) | ((0x1) << 9) | ((0x0) << 8) | ((0x1) << 4) | ((0x0) << 1) | ((0x1) << 0))
 >;
};

&gpioh {
 st,protreg = <
  ((((0)) << 24) | ((0x0) << 16) | ((0x0) << 10) | ((0x0) << 9) | ((0x0) << 8) | ((0x0) << 4) | ((0x1) << 1) | ((0x1) << 0))
  ((((1)) << 24) | ((0x0) << 16) | ((0x0) << 10) | ((0x0) << 9) | ((0x0) << 8) | ((0x0) << 4) | ((0x1) << 1) | ((0x1) << 0))
  ((((2)) << 24) | ((0x0) << 16) | ((0x0) << 10) | ((0x0) << 9) | ((0x0) << 8) | ((0x2) << 4) | ((0x0) << 1) | ((0x1) << 0))
  ((((3)) << 24) | ((0x0) << 16) | ((0x0) << 10) | ((0x0) << 9) | ((0x0) << 8) | ((0x2) << 4) | ((0x0) << 1) | ((0x1) << 0))
  ((((4)) << 24) | ((0x0) << 16) | ((0x0) << 10) | ((0x1) << 9) | ((0x1) << 8) | ((0x1) << 4) | ((0x0) << 1) | ((0x1) << 0))
  ((((5)) << 24) | ((0x0) << 16) | ((0x0) << 10) | ((0x1) << 9) | ((0x0) << 8) | ((0x1) << 4) | ((0x0) << 1) | ((0x1) << 0))
  ((((6)) << 24) | ((0x0) << 16) | ((0x0) << 10) | ((0x0) << 9) | ((0x0) << 8) | ((0x2) << 4) | ((0x0) << 1) | ((0x1) << 0))
  ((((7)) << 24) | ((0x0) << 16) | ((0x0) << 10) | ((0x1) << 9) | ((0x0) << 8) | ((0x1) << 4) | ((0x0) << 1) | ((0x1) << 0))
  ((((8)) << 24) | ((0x0) << 16) | ((0x0) << 10) | ((0x1) << 9) | ((0x0) << 8) | ((0x1) << 4) | ((0x0) << 1) | ((0x1) << 0))
  ((((9)) << 24) | ((0x0) << 16) | ((0x0) << 10) | ((0x1) << 9) | ((0x0) << 8) | ((0x1) << 4) | ((0x0) << 1) | ((0x1) << 0))
  ((((10)) << 24) | ((0x0) << 16) | ((0x0) << 10) | ((0x1) << 9) | ((0x0) << 8) | ((0x1) << 4) | ((0x0) << 1) | ((0x1) << 0))
  ((((11)) << 24) | ((0x0) << 16) | ((0x0) << 10) | ((0x1) << 9) | ((0x0) << 8) | ((0x1) << 4) | ((0x0) << 1) | ((0x1) << 0))
  ((((12)) << 24) | ((0x0) << 16) | ((0x0) << 10) | ((0x1) << 9) | ((0x0) << 8) | ((0x1) << 4) | ((0x0) << 1) | ((0x1) << 0))
  ((((13)) << 24) | ((0x0) << 16) | ((0x0) << 10) | ((0x1) << 9) | ((0x0) << 8) | ((0x1) << 4) | ((0x0) << 1) | ((0x1) << 0))
 >;
};

&gpioi {
 st,protreg = <
  ((((0)) << 24) | ((0x0) << 16) | ((0x0) << 10) | ((0x1) << 9) | ((0x0) << 8) | ((0x1) << 4) | ((0x0) << 1) | ((0x1) << 0))
  ((((1)) << 24) | ((0x0) << 16) | ((0x0) << 10) | ((0x0) << 9) | ((0x0) << 8) | ((0x2) << 4) | ((0x0) << 1) | ((0x1) << 0))
  ((((2)) << 24) | ((0x0) << 16) | ((0x0) << 10) | ((0x1) << 9) | ((0x0) << 8) | ((0x1) << 4) | ((0x0) << 1) | ((0x1) << 0))
  ((((3)) << 24) | ((0x0) << 16) | ((0x0) << 10) | ((0x1) << 9) | ((0x0) << 8) | ((0x1) << 4) | ((0x0) << 1) | ((0x1) << 0))
  ((((4)) << 24) | ((0x0) << 16) | ((0x0) << 10) | ((0x1) << 9) | ((0x0) << 8) | ((0x1) << 4) | ((0x0) << 1) | ((0x1) << 0))
  ((((5)) << 24) | ((0x0) << 16) | ((0x0) << 10) | ((0x0) << 9) | ((0x0) << 8) | ((0x0) << 4) | ((0x1) << 1) | ((0x1) << 0))
  ((((6)) << 24) | ((0x0) << 16) | ((0x0) << 10) | ((0x1) << 9) | ((0x0) << 8) | ((0x1) << 4) | ((0x0) << 1) | ((0x1) << 0))
  ((((7)) << 24) | ((0x0) << 16) | ((0x0) << 10) | ((0x1) << 9) | ((0x0) << 8) | ((0x1) << 4) | ((0x0) << 1) | ((0x1) << 0))
  ((((8)) << 24) | ((0x0) << 16) | ((0x0) << 10) | ((0x1) << 9) | ((0x0) << 8) | ((0x1) << 4) | ((0x0) << 1) | ((0x1) << 0))
  ((((9)) << 24) | ((0x0) << 16) | ((0x0) << 10) | ((0x0) << 9) | ((0x0) << 8) | ((0x0) << 4) | ((0x1) << 1) | ((0x1) << 0))
  ((((10)) << 24) | ((0x0) << 16) | ((0x0) << 10) | ((0x0) << 9) | ((0x0) << 8) | ((0x0) << 4) | ((0x1) << 1) | ((0x1) << 0))
  ((((11)) << 24) | ((0x0) << 16) | ((0x0) << 10) | ((0x1) << 9) | ((0x0) << 8) | ((0x1) << 4) | ((0x0) << 1) | ((0x1) << 0))
  ((((12)) << 24) | ((0x0) << 16) | ((0x0) << 10) | ((0x0) << 9) | ((0x0) << 8) | ((0x0) << 4) | ((0x1) << 1) | ((0x1) << 0))
  ((((13)) << 24) | ((0x0) << 16) | ((0x0) << 10) | ((0x0) << 9) | ((0x0) << 8) | ((0x0) << 4) | ((0x1) << 1) | ((0x1) << 0))
  ((((14)) << 24) | ((0x0) << 16) | ((0x0) << 10) | ((0x0) << 9) | ((0x0) << 8) | ((0x0) << 4) | ((0x1) << 1) | ((0x1) << 0))
  ((((15)) << 24) | ((0x0) << 16) | ((0x0) << 10) | ((0x0) << 9) | ((0x0) << 8) | ((0x0) << 4) | ((0x1) << 1) | ((0x1) << 0))
 >;
};

&gpioj {
 st,protreg = <
  ((((0)) << 24) | ((0x0) << 16) | ((0x0) << 10) | ((0x0) << 9) | ((0x0) << 8) | ((0x0) << 4) | ((0x1) << 1) | ((0x1) << 0))
  ((((1)) << 24) | ((0x0) << 16) | ((0x0) << 10) | ((0x0) << 9) | ((0x0) << 8) | ((0x0) << 4) | ((0x1) << 1) | ((0x1) << 0))
  ((((2)) << 24) | ((0x0) << 16) | ((0x0) << 10) | ((0x0) << 9) | ((0x0) << 8) | ((0x0) << 4) | ((0x1) << 1) | ((0x1) << 0))
  ((((3)) << 24) | ((0x0) << 16) | ((0x0) << 10) | ((0x0) << 9) | ((0x0) << 8) | ((0x0) << 4) | ((0x1) << 1) | ((0x1) << 0))
  ((((4)) << 24) | ((0x0) << 16) | ((0x0) << 10) | ((0x0) << 9) | ((0x0) << 8) | ((0x0) << 4) | ((0x1) << 1) | ((0x1) << 0))
  ((((5)) << 24) | ((0x0) << 16) | ((0x0) << 10) | ((0x0) << 9) | ((0x0) << 8) | ((0x0) << 4) | ((0x1) << 1) | ((0x1) << 0))
  ((((6)) << 24) | ((0x0) << 16) | ((0x0) << 10) | ((0x0) << 9) | ((0x0) << 8) | ((0x0) << 4) | ((0x1) << 1) | ((0x1) << 0))
  ((((7)) << 24) | ((0x0) << 16) | ((0x0) << 10) | ((0x0) << 9) | ((0x0) << 8) | ((0x0) << 4) | ((0x1) << 1) | ((0x1) << 0))
  ((((8)) << 24) | ((0x0) << 16) | ((0x0) << 10) | ((0x0) << 9) | ((0x0) << 8) | ((0x0) << 4) | ((0x1) << 1) | ((0x1) << 0))
  ((((9)) << 24) | ((0x0) << 16) | ((0x0) << 10) | ((0x0) << 9) | ((0x0) << 8) | ((0x0) << 4) | ((0x1) << 1) | ((0x1) << 0))
  ((((10)) << 24) | ((0x0) << 16) | ((0x0) << 10) | ((0x0) << 9) | ((0x0) << 8) | ((0x0) << 4) | ((0x1) << 1) | ((0x1) << 0))
  ((((11)) << 24) | ((0x0) << 16) | ((0x0) << 10) | ((0x0) << 9) | ((0x0) << 8) | ((0x0) << 4) | ((0x1) << 1) | ((0x1) << 0))
  ((((12)) << 24) | ((0x0) << 16) | ((0x0) << 10) | ((0x0) << 9) | ((0x0) << 8) | ((0x0) << 4) | ((0x1) << 1) | ((0x1) << 0))
  ((((13)) << 24) | ((0x0) << 16) | ((0x0) << 10) | ((0x0) << 9) | ((0x0) << 8) | ((0x0) << 4) | ((0x1) << 1) | ((0x1) << 0))
  ((((14)) << 24) | ((0x0) << 16) | ((0x0) << 10) | ((0x0) << 9) | ((0x0) << 8) | ((0x0) << 4) | ((0x1) << 1) | ((0x1) << 0))
  ((((15)) << 24) | ((0x0) << 16) | ((0x0) << 10) | ((0x0) << 9) | ((0x0) << 8) | ((0x0) << 4) | ((0x1) << 1) | ((0x1) << 0))
 >;
};

&gpiok {
 st,protreg = <
  ((((0)) << 24) | ((0x0) << 16) | ((0x0) << 10) | ((0x0) << 9) | ((0x0) << 8) | ((0x0) << 4) | ((0x1) << 1) | ((0x1) << 0))
  ((((1)) << 24) | ((0x0) << 16) | ((0x0) << 10) | ((0x0) << 9) | ((0x0) << 8) | ((0x0) << 4) | ((0x1) << 1) | ((0x1) << 0))
  ((((2)) << 24) | ((0x0) << 16) | ((0x0) << 10) | ((0x0) << 9) | ((0x0) << 8) | ((0x0) << 4) | ((0x1) << 1) | ((0x1) << 0))
  ((((3)) << 24) | ((0x0) << 16) | ((0x0) << 10) | ((0x0) << 9) | ((0x0) << 8) | ((0x0) << 4) | ((0x1) << 1) | ((0x1) << 0))
  ((((4)) << 24) | ((0x0) << 16) | ((0x0) << 10) | ((0x0) << 9) | ((0x0) << 8) | ((0x0) << 4) | ((0x1) << 1) | ((0x1) << 0))
  ((((5)) << 24) | ((0x0) << 16) | ((0x0) << 10) | ((0x0) << 9) | ((0x0) << 8) | ((0x0) << 4) | ((0x1) << 1) | ((0x1) << 0))
  ((((6)) << 24) | ((0x0) << 16) | ((0x0) << 10) | ((0x0) << 9) | ((0x0) << 8) | ((0x0) << 4) | ((0x1) << 1) | ((0x1) << 0))
  ((((7)) << 24) | ((0x0) << 16) | ((0x0) << 10) | ((0x0) << 9) | ((0x0) << 8) | ((0x0) << 4) | ((0x1) << 1) | ((0x1) << 0))
 >;
};

&gpioz {
 st,protreg = <
  ((((0)) << 24) | ((0x0) << 16) | ((0x0) << 10) | ((0x1) << 9) | ((0x0) << 8) | ((0x1) << 4) | ((0x0) << 1) | ((0x1) << 0))
  ((((1)) << 24) | ((0x0) << 16) | ((0x0) << 10) | ((0x1) << 9) | ((0x0) << 8) | ((0x1) << 4) | ((0x0) << 1) | ((0x1) << 0))
  ((((2)) << 24) | ((0x0) << 16) | ((0x0) << 10) | ((0x1) << 9) | ((0x1) << 8) | ((0x1) << 4) | ((0x0) << 1) | ((0x1) << 0))
  ((((3)) << 24) | ((0x0) << 16) | ((0x0) << 10) | ((0x1) << 9) | ((0x0) << 8) | ((0x1) << 4) | ((0x0) << 1) | ((0x1) << 0))
  ((((4)) << 24) | ((0x0) << 16) | ((0x0) << 10) | ((0x1) << 9) | ((0x0) << 8) | ((0x1) << 4) | ((0x0) << 1) | ((0x1) << 0))
  ((((5)) << 24) | ((0x0) << 16) | ((0x0) << 10) | ((0x1) << 9) | ((0x0) << 8) | ((0x1) << 4) | ((0x0) << 1) | ((0x1) << 0))
  ((((6)) << 24) | ((0x0) << 16) | ((0x0) << 10) | ((0x1) << 9) | ((0x0) << 8) | ((0x1) << 4) | ((0x0) << 1) | ((0x1) << 0))
  ((((7)) << 24) | ((0x0) << 16) | ((0x0) << 10) | ((0x1) << 9) | ((0x0) << 8) | ((0x1) << 4) | ((0x0) << 1) | ((0x1) << 0))
  ((((8)) << 24) | ((0x0) << 16) | ((0x0) << 10) | ((0x1) << 9) | ((0x0) << 8) | ((0x1) << 4) | ((0x0) << 1) | ((0x1) << 0))
  ((((9)) << 24) | ((0x0) << 16) | ((0x0) << 10) | ((0x1) << 9) | ((0x0) << 8) | ((0x1) << 4) | ((0x0) << 1) | ((0x1) << 0))
 >;
};

&hpdma1 {
 st,protreg = <
  ((((0)) << 24) | ((0x0) << 16) | ((0x0) << 10) | ((0x1) << 9) | ((0x0) << 8) | ((0x1) << 4) | ((0x0) << 1) | ((0x1) << 0))
  ((((1)) << 24) | ((0x0) << 16) | ((0x0) << 10) | ((0x1) << 9) | ((0x0) << 8) | ((0x1) << 4) | ((0x0) << 1) | ((0x1) << 0))
  ((((2)) << 24) | ((0x0) << 16) | ((0x0) << 10) | ((0x1) << 9) | ((0x0) << 8) | ((0x1) << 4) | ((0x0) << 1) | ((0x1) << 0))
  ((((3)) << 24) | ((0x0) << 16) | ((0x0) << 10) | ((0x1) << 9) | ((0x0) << 8) | ((0x1) << 4) | ((0x0) << 1) | ((0x1) << 0))
  ((((4)) << 24) | ((0x0) << 16) | ((0x0) << 10) | ((0x1) << 9) | ((0x0) << 8) | ((0x1) << 4) | ((0x0) << 1) | ((0x1) << 0))
  ((((5)) << 24) | ((0x0) << 16) | ((0x0) << 10) | ((0x1) << 9) | ((0x0) << 8) | ((0x1) << 4) | ((0x0) << 1) | ((0x1) << 0))
  ((((6)) << 24) | ((0x0) << 16) | ((0x0) << 10) | ((0x1) << 9) | ((0x0) << 8) | ((0x1) << 4) | ((0x0) << 1) | ((0x1) << 0))
  ((((7)) << 24) | ((0x0) << 16) | ((0x0) << 10) | ((0x1) << 9) | ((0x0) << 8) | ((0x1) << 4) | ((0x0) << 1) | ((0x1) << 0))
  ((((8)) << 24) | ((0x0) << 16) | ((0x0) << 10) | ((0x1) << 9) | ((0x0) << 8) | ((0x1) << 4) | ((0x0) << 1) | ((0x1) << 0))
  ((((9)) << 24) | ((0x0) << 16) | ((0x0) << 10) | ((0x1) << 9) | ((0x0) << 8) | ((0x1) << 4) | ((0x0) << 1) | ((0x1) << 0))
  ((((10)) << 24) | ((0x0) << 16) | ((0x0) << 10) | ((0x1) << 9) | ((0x0) << 8) | ((0x1) << 4) | ((0x0) << 1) | ((0x1) << 0))
  ((((11)) << 24) | ((0x0) << 16) | ((0x0) << 10) | ((0x1) << 9) | ((0x0) << 8) | ((0x1) << 4) | ((0x0) << 1) | ((0x1) << 0))
  ((((12)) << 24) | ((0x0) << 16) | ((0x0) << 10) | ((0x1) << 9) | ((0x0) << 8) | ((0x1) << 4) | ((0x0) << 1) | ((0x1) << 0))
  ((((13)) << 24) | ((0x0) << 16) | ((0x0) << 10) | ((0x1) << 9) | ((0x0) << 8) | ((0x1) << 4) | ((0x0) << 1) | ((0x1) << 0))
  ((((14)) << 24) | ((0x0) << 16) | ((0x0) << 10) | ((0x1) << 9) | ((0x0) << 8) | ((0x1) << 4) | ((0x0) << 1) | ((0x1) << 0))
  ((((15)) << 24) | ((0x0) << 16) | ((0x0) << 10) | ((0x1) << 9) | ((0x0) << 8) | ((0x1) << 4) | ((0x0) << 1) | ((0x1) << 0))
 >;
};

&hpdma2 {
 st,protreg = <
  ((((0)) << 24) | ((0x0) << 16) | ((0x0) << 10) | ((0x1) << 9) | ((0x0) << 8) | ((0x1) << 4) | ((0x0) << 1) | ((0x1) << 0))
  ((((1)) << 24) | ((0x0) << 16) | ((0x0) << 10) | ((0x1) << 9) | ((0x0) << 8) | ((0x1) << 4) | ((0x0) << 1) | ((0x1) << 0))
  ((((2)) << 24) | ((0x0) << 16) | ((0x0) << 10) | ((0x1) << 9) | ((0x0) << 8) | ((0x1) << 4) | ((0x0) << 1) | ((0x1) << 0))
  ((((3)) << 24) | ((0x0) << 16) | ((0x0) << 10) | ((0x1) << 9) | ((0x0) << 8) | ((0x1) << 4) | ((0x0) << 1) | ((0x1) << 0))
  ((((4)) << 24) | ((0x0) << 16) | ((0x0) << 10) | ((0x1) << 9) | ((0x0) << 8) | ((0x1) << 4) | ((0x0) << 1) | ((0x1) << 0))
  ((((5)) << 24) | ((0x0) << 16) | ((0x0) << 10) | ((0x1) << 9) | ((0x0) << 8) | ((0x1) << 4) | ((0x0) << 1) | ((0x1) << 0))
  ((((6)) << 24) | ((0x0) << 16) | ((0x0) << 10) | ((0x1) << 9) | ((0x0) << 8) | ((0x1) << 4) | ((0x0) << 1) | ((0x1) << 0))
  ((((7)) << 24) | ((0x0) << 16) | ((0x0) << 10) | ((0x1) << 9) | ((0x0) << 8) | ((0x1) << 4) | ((0x0) << 1) | ((0x1) << 0))
  ((((8)) << 24) | ((0x0) << 16) | ((0x0) << 10) | ((0x1) << 9) | ((0x0) << 8) | ((0x1) << 4) | ((0x0) << 1) | ((0x1) << 0))
  ((((9)) << 24) | ((0x0) << 16) | ((0x0) << 10) | ((0x1) << 9) | ((0x0) << 8) | ((0x1) << 4) | ((0x0) << 1) | ((0x1) << 0))
  ((((10)) << 24) | ((0x0) << 16) | ((0x0) << 10) | ((0x1) << 9) | ((0x0) << 8) | ((0x1) << 4) | ((0x0) << 1) | ((0x1) << 0))
  ((((11)) << 24) | ((0x0) << 16) | ((0x0) << 10) | ((0x1) << 9) | ((0x0) << 8) | ((0x1) << 4) | ((0x0) << 1) | ((0x1) << 0))
  ((((12)) << 24) | ((0x0) << 16) | ((0x0) << 10) | ((0x1) << 9) | ((0x0) << 8) | ((0x1) << 4) | ((0x0) << 1) | ((0x1) << 0))
  ((((13)) << 24) | ((0x0) << 16) | ((0x0) << 10) | ((0x1) << 9) | ((0x0) << 8) | ((0x1) << 4) | ((0x0) << 1) | ((0x1) << 0))
  ((((14)) << 24) | ((0x0) << 16) | ((0x0) << 10) | ((0x1) << 9) | ((0x0) << 8) | ((0x1) << 4) | ((0x0) << 1) | ((0x1) << 0))
  ((((15)) << 24) | ((0x0) << 16) | ((0x0) << 10) | ((0x1) << 9) | ((0x0) << 8) | ((0x1) << 4) | ((0x0) << 1) | ((0x1) << 0))
 >;
};

&hpdma3 {
 st,protreg = <
  ((((0)) << 24) | ((0x0) << 16) | ((0x0) << 10) | ((0x1) << 9) | ((0x0) << 8) | ((0x2) << 4) | ((0x0) << 1) | ((0x1) << 0))
  ((((1)) << 24) | ((0x0) << 16) | ((0x0) << 10) | ((0x1) << 9) | ((0x0) << 8) | ((0x2) << 4) | ((0x0) << 1) | ((0x1) << 0))
  ((((2)) << 24) | ((0x0) << 16) | ((0x0) << 10) | ((0x1) << 9) | ((0x0) << 8) | ((0x2) << 4) | ((0x0) << 1) | ((0x1) << 0))
  ((((3)) << 24) | ((0x0) << 16) | ((0x0) << 10) | ((0x1) << 9) | ((0x0) << 8) | ((0x2) << 4) | ((0x0) << 1) | ((0x1) << 0))
  ((((4)) << 24) | ((0x0) << 16) | ((0x0) << 10) | ((0x1) << 9) | ((0x0) << 8) | ((0x2) << 4) | ((0x0) << 1) | ((0x1) << 0))
  ((((5)) << 24) | ((0x0) << 16) | ((0x0) << 10) | ((0x1) << 9) | ((0x0) << 8) | ((0x2) << 4) | ((0x0) << 1) | ((0x1) << 0))
  ((((6)) << 24) | ((0x0) << 16) | ((0x0) << 10) | ((0x1) << 9) | ((0x0) << 8) | ((0x2) << 4) | ((0x0) << 1) | ((0x1) << 0))
  ((((7)) << 24) | ((0x0) << 16) | ((0x0) << 10) | ((0x1) << 9) | ((0x0) << 8) | ((0x2) << 4) | ((0x0) << 1) | ((0x1) << 0))
  ((((8)) << 24) | ((0x0) << 16) | ((0x0) << 10) | ((0x1) << 9) | ((0x0) << 8) | ((0x2) << 4) | ((0x0) << 1) | ((0x1) << 0))
  ((((9)) << 24) | ((0x0) << 16) | ((0x0) << 10) | ((0x1) << 9) | ((0x0) << 8) | ((0x2) << 4) | ((0x0) << 1) | ((0x1) << 0))
  ((((10)) << 24) | ((0x0) << 16) | ((0x0) << 10) | ((0x1) << 9) | ((0x0) << 8) | ((0x2) << 4) | ((0x0) << 1) | ((0x1) << 0))
  ((((11)) << 24) | ((0x0) << 16) | ((0x0) << 10) | ((0x1) << 9) | ((0x0) << 8) | ((0x2) << 4) | ((0x0) << 1) | ((0x1) << 0))
  ((((12)) << 24) | ((0x0) << 16) | ((0x0) << 10) | ((0x1) << 9) | ((0x0) << 8) | ((0x2) << 4) | ((0x0) << 1) | ((0x1) << 0))
  ((((13)) << 24) | ((0x0) << 16) | ((0x0) << 10) | ((0x1) << 9) | ((0x0) << 8) | ((0x2) << 4) | ((0x0) << 1) | ((0x1) << 0))
  ((((14)) << 24) | ((0x0) << 16) | ((0x0) << 10) | ((0x1) << 9) | ((0x0) << 8) | ((0x1) << 4) | ((0x0) << 1) | ((0x1) << 0))
  ((((15)) << 24) | ((0x0) << 16) | ((0x0) << 10) | ((0x1) << 9) | ((0x0) << 8) | ((0x1) << 4) | ((0x0) << 1) | ((0x1) << 0))
 >;
};

&rifsc {
 st,rimu = <
  ((((0)) << 16) | ((0x1) << 9) | ((0x0) << 8) | ((0x1) << 4) | ((0x1) << 2))
  ((((1)) << 16) | ((0x1) << 9) | ((0x0) << 8) | ((0x0) << 4) | ((0x0) << 2))
  ((((2)) << 16) | ((0x1) << 9) | ((0x0) << 8) | ((0x0) << 4) | ((0x0) << 2))
  ((((3)) << 16) | ((0x1) << 9) | ((0x0) << 8) | ((0x0) << 4) | ((0x0) << 2))
  ((((4)) << 16) | ((0x1) << 9) | ((0x0) << 8) | ((0x0) << 4) | ((0x0) << 2))
  ((((5)) << 16) | ((0x1) << 9) | ((0x0) << 8) | ((0x0) << 4) | ((0x0) << 2))
  ((((6)) << 16) | ((0x1) << 9) | ((0x0) << 8) | ((0x0) << 4) | ((0x0) << 2))
  ((((7)) << 16) | ((0x0) << 9) | ((0x0) << 8) | ((0x0) << 4) | ((0x0) << 2))
  ((((8)) << 16) | ((0x0) << 9) | ((0x0) << 8) | ((0x0) << 4) | ((0x0) << 2))
  ((((9)) << 16) | ((0x1) << 9) | ((0x0) << 8) | ((0x0) << 4) | ((0x0) << 2))
  ((((10)) << 16) | ((0x1) << 9) | ((0x0) << 8) | ((0x0) << 4) | ((0x0) << 2))
  ((((11)) << 16) | ((0x1) << 9) | ((0x0) << 8) | ((0x4) << 4) | ((0x1) << 2))
  ((((12)) << 16) | ((0x1) << 9) | ((0x1) << 8) | ((0x4) << 4) | ((0x1) << 2))
  ((((13)) << 16) | ((0x1) << 9) | ((0x0) << 8) | ((0x4) << 4) | ((0x1) << 2))
  ((((14)) << 16) | ((0x1) << 9) | ((0x0) << 8) | ((0x0) << 4) | ((0x0) << 2))
  ((((15)) << 16) | ((0x1) << 9) | ((0x0) << 8) | ((0x0) << 4) | ((0x0) << 2))
 >;
};

&rcc {
 st,protreg = <
  ((((69)) << 24) | ((0x0) << 16) | ((0x0) << 10) | ((0x1) << 9) | ((0x1) << 8) | ((0x1) << 4) | ((0x0) << 1) | ((0x1) << 0))
  ((((64)) << 24) | ((0x0) << 16) | ((0x0) << 10) | ((0x1) << 9) | ((0x1) << 8) | ((0x1) << 4) | ((0x0) << 1) | ((0x1) << 0))
  ((((65)) << 24) | ((0x0) << 16) | ((0x0) << 10) | ((0x1) << 9) | ((0x1) << 8) | ((0x1) << 4) | ((0x0) << 1) | ((0x1) << 0))
  ((((66)) << 24) | ((0x0) << 16) | ((0x0) << 10) | ((0x1) << 9) | ((0x1) << 8) | ((0x1) << 4) | ((0x0) << 1) | ((0x1) << 0))
  ((((67)) << 24) | ((0x0) << 16) | ((0x0) << 10) | ((0x1) << 9) | ((0x1) << 8) | ((0x1) << 4) | ((0x0) << 1) | ((0x1) << 0))
  ((((68)) << 24) | ((0x0) << 16) | ((0x0) << 10) | ((0x1) << 9) | ((0x1) << 8) | ((0x1) << 4) | ((0x0) << 1) | ((0x1) << 0))
  ((((70)) << 24) | ((0x0) << 16) | ((0x0) << 10) | ((0x1) << 9) | ((0x1) << 8) | ((0x1) << 4) | ((0x0) << 1) | ((0x1) << 0))
  ((((71)) << 24) | ((0x0) << 16) | ((0x0) << 10) | ((0x1) << 9) | ((0x1) << 8) | ((0x2) << 4) | ((0x0) << 1) | ((0x1) << 0))
  ((((72)) << 24) | ((0x0) << 16) | ((0x0) << 10) | ((0x1) << 9) | ((0x1) << 8) | ((0x1) << 4) | ((0x0) << 1) | ((0x1) << 0))
  ((((73)) << 24) | (((1 << 0x1)) << 16) | ((0x0) << 10) | ((0x1) << 9) | ((0x1) << 8) | ((0x0) << 4) | ((0x1) << 1) | ((0x1) << 0))
  ((((74)) << 24) | (((1 << 0x1)) << 16) | ((0x0) << 10) | ((0x1) << 9) | ((0x1) << 8) | ((0x0) << 4) | ((0x1) << 1) | ((0x1) << 0))
  ((((75)) << 24) | ((0x0) << 16) | ((0x0) << 10) | ((0x1) << 9) | ((0x1) << 8) | ((0x1) << 4) | ((0x0) << 1) | ((0x1) << 0))
  ((((76)) << 24) | (((1 << 0x1)) << 16) | ((0x0) << 10) | ((0x1) << 9) | ((0x1) << 8) | ((0x0) << 4) | ((0x1) << 1) | ((0x1) << 0))
  ((((77)) << 24) | (((1 << 0x1)) << 16) | ((0x0) << 10) | ((0x1) << 9) | ((0x1) << 8) | ((0x0) << 4) | ((0x1) << 1) | ((0x1) << 0))
  ((((78)) << 24) | ((0x0) << 16) | ((0x0) << 10) | ((0x1) << 9) | ((0x1) << 8) | ((0x1) << 4) | ((0x0) << 1) | ((0x1) << 0))
  ((((79)) << 24) | ((0x0) << 16) | ((0x0) << 10) | ((0x1) << 9) | ((0x1) << 8) | ((0x1) << 4) | ((0x0) << 1) | ((0x1) << 0))
  ((((80)) << 24) | ((0x0) << 16) | ((0x0) << 10) | ((0x1) << 9) | ((0x1) << 8) | ((0x1) << 4) | ((0x0) << 1) | ((0x1) << 0))
  ((((81)) << 24) | ((0x0) << 16) | ((0x0) << 10) | ((0x1) << 9) | ((0x1) << 8) | ((0x1) << 4) | ((0x0) << 1) | ((0x1) << 0))
  ((((82)) << 24) | ((0x0) << 16) | ((0x0) << 10) | ((0x1) << 9) | ((0x1) << 8) | ((0x1) << 4) | ((0x0) << 1) | ((0x1) << 0))
  ((((83)) << 24) | (((1 << 0x1)) << 16) | ((0x0) << 10) | ((0x1) << 9) | ((0x1) << 8) | ((0x0) << 4) | ((0x1) << 1) | ((0x1) << 0))
  ((((84)) << 24) | (((1 << 0x1)) << 16) | ((0x0) << 10) | ((0x1) << 9) | ((0x1) << 8) | ((0x0) << 4) | ((0x1) << 1) | ((0x1) << 0))
  ((((85)) << 24) | (((1 << 0x1)) << 16) | ((0x0) << 10) | ((0x1) << 9) | ((0x1) << 8) | ((0x0) << 4) | ((0x1) << 1) | ((0x1) << 0))
  ((((86)) << 24) | ((0x0) << 16) | ((0x0) << 10) | ((0x0) << 9) | ((0x0) << 8) | ((0x0) << 4) | ((0x1) << 1) | ((0x1) << 0))
  ((((87)) << 24) | (((1 << 0x1)) << 16) | ((0x0) << 10) | ((0x1) << 9) | ((0x1) << 8) | ((0x0) << 4) | ((0x1) << 1) | ((0x1) << 0))
  ((((88)) << 24) | (((1 << 0x1)) << 16) | ((0x0) << 10) | ((0x1) << 9) | ((0x1) << 8) | ((0x0) << 4) | ((0x1) << 1) | ((0x1) << 0))
  ((((89)) << 24) | (((1 << 0x1)) << 16) | ((0x0) << 10) | ((0x1) << 9) | ((0x1) << 8) | ((0x0) << 4) | ((0x1) << 1) | ((0x1) << 0))
  ((((90)) << 24) | (((1 << 0x1)) << 16) | ((0x0) << 10) | ((0x1) << 9) | ((0x1) << 8) | ((0x0) << 4) | ((0x1) << 1) | ((0x1) << 0))
  ((((91)) << 24) | (((1 << 0x1)) << 16) | ((0x0) << 10) | ((0x1) << 9) | ((0x1) << 8) | ((0x0) << 4) | ((0x1) << 1) | ((0x1) << 0))
  ((((92)) << 24) | (((1 << 0x1)) << 16) | ((0x0) << 10) | ((0x1) << 9) | ((0x1) << 8) | ((0x0) << 4) | ((0x1) << 1) | ((0x1) << 0))
  ((((93)) << 24) | (((1 << 0x1)) << 16) | ((0x0) << 10) | ((0x1) << 9) | ((0x1) << 8) | ((0x0) << 4) | ((0x1) << 1) | ((0x1) << 0))
  ((((94)) << 24) | (((1 << 0x1)) << 16) | ((0x0) << 10) | ((0x1) << 9) | ((0x1) << 8) | ((0x0) << 4) | ((0x1) << 1) | ((0x1) << 0))
  ((((95)) << 24) | (((1 << 0x1)) << 16) | ((0x0) << 10) | ((0x1) << 9) | ((0x1) << 8) | ((0x0) << 4) | ((0x1) << 1) | ((0x1) << 0))
  ((((96)) << 24) | (((1 << 0x1)) << 16) | ((0x0) << 10) | ((0x1) << 9) | ((0x1) << 8) | ((0x0) << 4) | ((0x1) << 1) | ((0x1) << 0))
  ((((97)) << 24) | (((1 << 0x1)) << 16) | ((0x0) << 10) | ((0x1) << 9) | ((0x1) << 8) | ((0x0) << 4) | ((0x1) << 1) | ((0x1) << 0))
  ((((98)) << 24) | (((1 << 0x1)) << 16) | ((0x0) << 10) | ((0x1) << 9) | ((0x1) << 8) | ((0x0) << 4) | ((0x1) << 1) | ((0x1) << 0))
  ((((99)) << 24) | (((1 << 0x1)) << 16) | ((0x0) << 10) | ((0x1) << 9) | ((0x1) << 8) | ((0x0) << 4) | ((0x1) << 1) | ((0x1) << 0))
  ((((100)) << 24) | (((1 << 0x1)) << 16) | ((0x0) << 10) | ((0x1) << 9) | ((0x1) << 8) | ((0x0) << 4) | ((0x1) << 1) | ((0x1) << 0))
  ((((101)) << 24) | (((1 << 0x1)) << 16) | ((0x0) << 10) | ((0x1) << 9) | ((0x1) << 8) | ((0x0) << 4) | ((0x1) << 1) | ((0x1) << 0))
  ((((102)) << 24) | ((0x0) << 16) | ((0x0) << 10) | ((0x1) << 9) | ((0x0) << 8) | ((0x1) << 4) | ((0x0) << 1) | ((0x1) << 0))
  ((((103)) << 24) | ((0x0) << 16) | ((0x0) << 10) | ((0x1) << 9) | ((0x1) << 8) | ((0x1) << 4) | ((0x0) << 1) | ((0x1) << 0))
  ((((104)) << 24) | ((0x0) << 16) | ((0x0) << 10) | ((0x1) << 9) | ((0x1) << 8) | ((0x1) << 4) | ((0x0) << 1) | ((0x1) << 0))
  ((((105)) << 24) | ((0x0) << 16) | ((0x0) << 10) | ((0x1) << 9) | ((0x1) << 8) | ((0x1) << 4) | ((0x0) << 1) | ((0x1) << 0))
  ((((106)) << 24) | ((0x0) << 16) | ((0x0) << 10) | ((0x1) << 9) | ((0x1) << 8) | ((0x1) << 4) | ((0x0) << 1) | ((0x1) << 0))
  ((((108)) << 24) | ((0x0) << 16) | ((0x0) << 10) | ((0x1) << 9) | ((0x1) << 8) | ((0x1) << 4) | ((0x0) << 1) | ((0x1) << 0))
  ((((109)) << 24) | ((0x0) << 16) | ((0x0) << 10) | ((0x1) << 9) | ((0x1) << 8) | ((0x1) << 4) | ((0x0) << 1) | ((0x1) << 0))
  ((((110)) << 24) | ((0x0) << 16) | ((0x0) << 10) | ((0x0) << 9) | ((0x0) << 8) | ((0x0) << 4) | ((0x1) << 1) | ((0x1) << 0))
  ((((111)) << 24) | ((0x0) << 16) | ((0x0) << 10) | ((0x0) << 9) | ((0x0) << 8) | ((0x0) << 4) | ((0x1) << 1) | ((0x1) << 0))
  ((((112)) << 24) | ((0x0) << 16) | ((0x0) << 10) | ((0x0) << 9) | ((0x0) << 8) | ((0x0) << 4) | ((0x1) << 1) | ((0x1) << 0))
  ((((113)) << 24) | ((0x0) << 16) | ((0x0) << 10) | ((0x1) << 9) | ((0x1) << 8) | ((0x1) << 4) | ((0x0) << 1) | ((0x1) << 0))
  ((((0)) << 24) | ((0x0) << 16) | ((0x0) << 10) | ((0x1) << 9) | ((0x1) << 8) | ((0x1) << 4) | ((0x0) << 1) | ((0x1) << 0))
  ((((1)) << 24) | ((0x0) << 16) | ((0x0) << 10) | ((0x1) << 9) | ((0x1) << 8) | ((0x1) << 4) | ((0x0) << 1) | ((0x1) << 0))
  ((((2)) << 24) | ((0x0) << 16) | ((0x0) << 10) | ((0x1) << 9) | ((0x1) << 8) | ((0x1) << 4) | ((0x0) << 1) | ((0x1) << 0))
  ((((3)) << 24) | ((0x0) << 16) | ((0x0) << 10) | ((0x1) << 9) | ((0x1) << 8) | ((0x1) << 4) | ((0x0) << 1) | ((0x1) << 0))
  ((((4)) << 24) | ((0x0) << 16) | ((0x0) << 10) | ((0x1) << 9) | ((0x1) << 8) | ((0x1) << 4) | ((0x0) << 1) | ((0x1) << 0))
  ((((5)) << 24) | ((0x0) << 16) | ((0x0) << 10) | ((0x1) << 9) | ((0x1) << 8) | ((0x1) << 4) | ((0x0) << 1) | ((0x1) << 0))
  ((((6)) << 24) | ((0x0) << 16) | ((0x0) << 10) | ((0x1) << 9) | ((0x1) << 8) | ((0x1) << 4) | ((0x0) << 1) | ((0x1) << 0))
  ((((7)) << 24) | ((0x0) << 16) | ((0x0) << 10) | ((0x1) << 9) | ((0x1) << 8) | ((0x1) << 4) | ((0x0) << 1) | ((0x1) << 0))
  ((((8)) << 24) | ((0x0) << 16) | ((0x0) << 10) | ((0x1) << 9) | ((0x1) << 8) | ((0x1) << 4) | ((0x0) << 1) | ((0x1) << 0))
  ((((9)) << 24) | ((0x0) << 16) | ((0x0) << 10) | ((0x1) << 9) | ((0x1) << 8) | ((0x1) << 4) | ((0x0) << 1) | ((0x1) << 0))
  ((((10)) << 24) | ((0x0) << 16) | ((0x0) << 10) | ((0x1) << 9) | ((0x1) << 8) | ((0x1) << 4) | ((0x0) << 1) | ((0x1) << 0))
  ((((11)) << 24) | ((0x0) << 16) | ((0x0) << 10) | ((0x1) << 9) | ((0x0) << 8) | ((0x0) << 4) | ((0x1) << 1) | ((0x1) << 0))
  ((((12)) << 24) | ((0x0) << 16) | ((0x0) << 10) | ((0x1) << 9) | ((0x1) << 8) | ((0x1) << 4) | ((0x0) << 1) | ((0x1) << 0))
  ((((13)) << 24) | ((0x0) << 16) | ((0x0) << 10) | ((0x1) << 9) | ((0x0) << 8) | ((0x0) << 4) | ((0x1) << 1) | ((0x1) << 0))
  ((((14)) << 24) | ((0x0) << 16) | ((0x0) << 10) | ((0x1) << 9) | ((0x0) << 8) | ((0x0) << 4) | ((0x1) << 1) | ((0x1) << 0))
  ((((15)) << 24) | ((0x0) << 16) | ((0x0) << 10) | ((0x1) << 9) | ((0x1) << 8) | ((0x1) << 4) | ((0x0) << 1) | ((0x1) << 0))
  ((((16)) << 24) | ((0x0) << 16) | ((0x0) << 10) | ((0x1) << 9) | ((0x0) << 8) | ((0x0) << 4) | ((0x1) << 1) | ((0x1) << 0))
  ((((17)) << 24) | ((0x0) << 16) | ((0x0) << 10) | ((0x1) << 9) | ((0x0) << 8) | ((0x0) << 4) | ((0x1) << 1) | ((0x1) << 0))
  ((((18)) << 24) | ((0x0) << 16) | ((0x0) << 10) | ((0x1) << 9) | ((0x1) << 8) | ((0x1) << 4) | ((0x0) << 1) | ((0x1) << 0))
  ((((19)) << 24) | ((0x0) << 16) | ((0x0) << 10) | ((0x1) << 9) | ((0x1) << 8) | ((0x1) << 4) | ((0x0) << 1) | ((0x1) << 0))
  ((((20)) << 24) | ((0x0) << 16) | ((0x0) << 10) | ((0x1) << 9) | ((0x1) << 8) | ((0x1) << 4) | ((0x0) << 1) | ((0x1) << 0))
  ((((21)) << 24) | ((0x0) << 16) | ((0x0) << 10) | ((0x1) << 9) | ((0x0) << 8) | ((0x0) << 4) | ((0x1) << 1) | ((0x1) << 0))
  ((((22)) << 24) | ((0x0) << 16) | ((0x0) << 10) | ((0x1) << 9) | ((0x0) << 8) | ((0x0) << 4) | ((0x1) << 1) | ((0x1) << 0))
  ((((23)) << 24) | ((0x0) << 16) | ((0x0) << 10) | ((0x1) << 9) | ((0x1) << 8) | ((0x1) << 4) | ((0x0) << 1) | ((0x1) << 0))
  ((((24)) << 24) | ((0x0) << 16) | ((0x0) << 10) | ((0x1) << 9) | ((0x0) << 8) | ((0x0) << 4) | ((0x1) << 1) | ((0x1) << 0))
  ((((25)) << 24) | ((0x0) << 16) | ((0x0) << 10) | ((0x1) << 9) | ((0x1) << 8) | ((0x1) << 4) | ((0x0) << 1) | ((0x1) << 0))
  ((((26)) << 24) | ((0x0) << 16) | ((0x0) << 10) | ((0x1) << 9) | ((0x0) << 8) | ((0x0) << 4) | ((0x1) << 1) | ((0x1) << 0))
  ((((27)) << 24) | ((0x0) << 16) | ((0x0) << 10) | ((0x1) << 9) | ((0x1) << 8) | ((0x1) << 4) | ((0x0) << 1) | ((0x1) << 0))
  ((((28)) << 24) | ((0x0) << 16) | ((0x0) << 10) | ((0x1) << 9) | ((0x1) << 8) | ((0x1) << 4) | ((0x0) << 1) | ((0x1) << 0))
  ((((29)) << 24) | ((0x0) << 16) | ((0x0) << 10) | ((0x1) << 9) | ((0x1) << 8) | ((0x1) << 4) | ((0x0) << 1) | ((0x1) << 0))
  ((((30)) << 24) | ((0x0) << 16) | ((0x0) << 10) | ((0x1) << 9) | ((0x1) << 8) | ((0x1) << 4) | ((0x0) << 1) | ((0x1) << 0))
  ((((31)) << 24) | ((0x0) << 16) | ((0x0) << 10) | ((0x1) << 9) | ((0x1) << 8) | ((0x1) << 4) | ((0x0) << 1) | ((0x1) << 0))
  ((((32)) << 24) | ((0x0) << 16) | ((0x0) << 10) | ((0x1) << 9) | ((0x1) << 8) | ((0x1) << 4) | ((0x0) << 1) | ((0x1) << 0))
  ((((33)) << 24) | ((0x0) << 16) | ((0x0) << 10) | ((0x1) << 9) | ((0x1) << 8) | ((0x1) << 4) | ((0x0) << 1) | ((0x1) << 0))
  ((((34)) << 24) | ((0x0) << 16) | ((0x0) << 10) | ((0x1) << 9) | ((0x1) << 8) | ((0x1) << 4) | ((0x0) << 1) | ((0x1) << 0))
  ((((35)) << 24) | ((0x0) << 16) | ((0x0) << 10) | ((0x1) << 9) | ((0x1) << 8) | ((0x1) << 4) | ((0x0) << 1) | ((0x1) << 0))
  ((((36)) << 24) | ((0x0) << 16) | ((0x0) << 10) | ((0x1) << 9) | ((0x0) << 8) | ((0x0) << 4) | ((0x1) << 1) | ((0x1) << 0))
  ((((37)) << 24) | ((0x0) << 16) | ((0x0) << 10) | ((0x1) << 9) | ((0x0) << 8) | ((0x0) << 4) | ((0x1) << 1) | ((0x1) << 0))
  ((((38)) << 24) | ((0x0) << 16) | ((0x0) << 10) | ((0x1) << 9) | ((0x1) << 8) | ((0x1) << 4) | ((0x0) << 1) | ((0x1) << 0))
  ((((39)) << 24) | ((0x0) << 16) | ((0x0) << 10) | ((0x1) << 9) | ((0x0) << 8) | ((0x0) << 4) | ((0x1) << 1) | ((0x1) << 0))
  ((((40)) << 24) | ((0x0) << 16) | ((0x0) << 10) | ((0x1) << 9) | ((0x1) << 8) | ((0x1) << 4) | ((0x0) << 1) | ((0x1) << 0))
  ((((41)) << 24) | ((0x0) << 16) | ((0x0) << 10) | ((0x1) << 9) | ((0x1) << 8) | ((0x1) << 4) | ((0x0) << 1) | ((0x1) << 0))
  ((((42)) << 24) | ((0x0) << 16) | ((0x0) << 10) | ((0x1) << 9) | ((0x0) << 8) | ((0x0) << 4) | ((0x1) << 1) | ((0x1) << 0))
  ((((43)) << 24) | ((0x0) << 16) | ((0x0) << 10) | ((0x1) << 9) | ((0x1) << 8) | ((0x1) << 4) | ((0x0) << 1) | ((0x1) << 0))
  ((((44)) << 24) | ((0x0) << 16) | ((0x0) << 10) | ((0x1) << 9) | ((0x1) << 8) | ((0x1) << 4) | ((0x0) << 1) | ((0x1) << 0))
  ((((45)) << 24) | ((0x0) << 16) | ((0x0) << 10) | ((0x1) << 9) | ((0x1) << 8) | ((0x1) << 4) | ((0x0) << 1) | ((0x1) << 0))
  ((((46)) << 24) | ((0x0) << 16) | ((0x0) << 10) | ((0x1) << 9) | ((0x1) << 8) | ((0x1) << 4) | ((0x0) << 1) | ((0x1) << 0))
  ((((47)) << 24) | ((0x0) << 16) | ((0x0) << 10) | ((0x1) << 9) | ((0x1) << 8) | ((0x1) << 4) | ((0x0) << 1) | ((0x1) << 0))
  ((((48)) << 24) | ((0x0) << 16) | ((0x0) << 10) | ((0x1) << 9) | ((0x0) << 8) | ((0x0) << 4) | ((0x1) << 1) | ((0x1) << 0))
  ((((49)) << 24) | ((0x0) << 16) | ((0x0) << 10) | ((0x1) << 9) | ((0x0) << 8) | ((0x0) << 4) | ((0x1) << 1) | ((0x1) << 0))
  ((((50)) << 24) | ((0x0) << 16) | ((0x0) << 10) | ((0x1) << 9) | ((0x0) << 8) | ((0x0) << 4) | ((0x1) << 1) | ((0x1) << 0))
  ((((51)) << 24) | ((0x0) << 16) | ((0x0) << 10) | ((0x1) << 9) | ((0x1) << 8) | ((0x1) << 4) | ((0x0) << 1) | ((0x1) << 0))
  ((((52)) << 24) | ((0x0) << 16) | ((0x0) << 10) | ((0x1) << 9) | ((0x1) << 8) | ((0x1) << 4) | ((0x0) << 1) | ((0x1) << 0))
  ((((53)) << 24) | ((0x0) << 16) | ((0x0) << 10) | ((0x1) << 9) | ((0x1) << 8) | ((0x1) << 4) | ((0x0) << 1) | ((0x1) << 0))
  ((((54)) << 24) | ((0x0) << 16) | ((0x0) << 10) | ((0x1) << 9) | ((0x1) << 8) | ((0x1) << 4) | ((0x0) << 1) | ((0x1) << 0))
  ((((55)) << 24) | ((0x0) << 16) | ((0x0) << 10) | ((0x1) << 9) | ((0x0) << 8) | ((0x0) << 4) | ((0x1) << 1) | ((0x1) << 0))
  ((((56)) << 24) | ((0x0) << 16) | ((0x0) << 10) | ((0x1) << 9) | ((0x1) << 8) | ((0x1) << 4) | ((0x0) << 1) | ((0x1) << 0))
  ((((57)) << 24) | ((0x0) << 16) | ((0x0) << 10) | ((0x1) << 9) | ((0x1) << 8) | ((0x1) << 4) | ((0x0) << 1) | ((0x1) << 0))
  ((((58)) << 24) | ((0x0) << 16) | ((0x0) << 10) | ((0x1) << 9) | ((0x1) << 8) | ((0x1) << 4) | ((0x0) << 1) | ((0x1) << 0))
  ((((59)) << 24) | ((0x0) << 16) | ((0x0) << 10) | ((0x1) << 9) | ((0x1) << 8) | ((0x1) << 4) | ((0x0) << 1) | ((0x1) << 0))
  ((((60)) << 24) | ((0x0) << 16) | ((0x0) << 10) | ((0x1) << 9) | ((0x0) << 8) | ((0x0) << 4) | ((0x1) << 1) | ((0x1) << 0))
  ((((61)) << 24) | ((0x0) << 16) | ((0x0) << 10) | ((0x1) << 9) | ((0x1) << 8) | ((0x1) << 4) | ((0x0) << 1) | ((0x1) << 0))
  ((((62)) << 24) | ((0x0) << 16) | ((0x0) << 10) | ((0x1) << 9) | ((0x1) << 8) | ((0x1) << 4) | ((0x0) << 1) | ((0x1) << 0))
  ((((63)) << 24) | ((0x0) << 16) | ((0x0) << 10) | ((0x1) << 9) | ((0x1) << 8) | ((0x1) << 4) | ((0x0) << 1) | ((0x1) << 0))
 >;
};

&ipcc1 {
 st,protreg = <
  ((((1 - 1)) << 24) | ((0x0) << 16) | ((0x0) << 10) | ((0x0) << 9) | ((0x0) << 8) | ((0x1) << 4) | ((0x0) << 1) | ((0x1) << 0))
  ((((((1) - 1) + 16)) << 24) | ((0x0) << 16) | ((0x0) << 10) | ((0x0) << 9) | ((0x0) << 8) | ((0x2) << 4) | ((0x0) << 1) | ((0x1) << 0))
  ((((2 - 1)) << 24) | ((0x0) << 16) | ((0x0) << 10) | ((0x0) << 9) | ((0x0) << 8) | ((0x1) << 4) | ((0x0) << 1) | ((0x1) << 0))
  ((((((2) - 1) + 16)) << 24) | ((0x0) << 16) | ((0x0) << 10) | ((0x0) << 9) | ((0x0) << 8) | ((0x2) << 4) | ((0x0) << 1) | ((0x1) << 0))
  ((((3 - 1)) << 24) | ((0x0) << 16) | ((0x0) << 10) | ((0x0) << 9) | ((0x0) << 8) | ((0x1) << 4) | ((0x0) << 1) | ((0x1) << 0))
  ((((((3) - 1) + 16)) << 24) | ((0x0) << 16) | ((0x0) << 10) | ((0x0) << 9) | ((0x0) << 8) | ((0x2) << 4) | ((0x0) << 1) | ((0x1) << 0))
  ((((4 - 1)) << 24) | ((0x0) << 16) | ((0x0) << 10) | ((0x0) << 9) | ((0x0) << 8) | ((0x1) << 4) | ((0x0) << 1) | ((0x1) << 0))
  ((((((4) - 1) + 16)) << 24) | ((0x0) << 16) | ((0x0) << 10) | ((0x0) << 9) | ((0x0) << 8) | ((0x2) << 4) | ((0x0) << 1) | ((0x1) << 0))
  ((((5 - 1)) << 24) | ((0x0) << 16) | ((0x0) << 10) | ((0x0) << 9) | ((0x0) << 8) | ((0x1) << 4) | ((0x0) << 1) | ((0x1) << 0))
  ((((((5) - 1) + 16)) << 24) | ((0x0) << 16) | ((0x0) << 10) | ((0x0) << 9) | ((0x0) << 8) | ((0x2) << 4) | ((0x0) << 1) | ((0x1) << 0))
  ((((6 - 1)) << 24) | ((0x0) << 16) | ((0x0) << 10) | ((0x0) << 9) | ((0x0) << 8) | ((0x1) << 4) | ((0x0) << 1) | ((0x1) << 0))
  ((((((6) - 1) + 16)) << 24) | ((0x0) << 16) | ((0x0) << 10) | ((0x0) << 9) | ((0x0) << 8) | ((0x2) << 4) | ((0x0) << 1) | ((0x1) << 0))
  ((((7 - 1)) << 24) | ((0x0) << 16) | ((0x0) << 10) | ((0x0) << 9) | ((0x0) << 8) | ((0x1) << 4) | ((0x0) << 1) | ((0x1) << 0))
  ((((((7) - 1) + 16)) << 24) | ((0x0) << 16) | ((0x0) << 10) | ((0x0) << 9) | ((0x0) << 8) | ((0x2) << 4) | ((0x0) << 1) | ((0x1) << 0))
  ((((8 - 1)) << 24) | ((0x0) << 16) | ((0x0) << 10) | ((0x0) << 9) | ((0x0) << 8) | ((0x1) << 4) | ((0x0) << 1) | ((0x1) << 0))
  ((((((8) - 1) + 16)) << 24) | ((0x0) << 16) | ((0x0) << 10) | ((0x0) << 9) | ((0x0) << 8) | ((0x2) << 4) | ((0x0) << 1) | ((0x1) << 0))
  ((((9 - 1)) << 24) | ((0x0) << 16) | ((0x0) << 10) | ((0x0) << 9) | ((0x0) << 8) | ((0x1) << 4) | ((0x0) << 1) | ((0x1) << 0))
  ((((((9) - 1) + 16)) << 24) | ((0x0) << 16) | ((0x0) << 10) | ((0x0) << 9) | ((0x0) << 8) | ((0x2) << 4) | ((0x0) << 1) | ((0x1) << 0))
  ((((10 - 1)) << 24) | ((0x0) << 16) | ((0x0) << 10) | ((0x0) << 9) | ((0x0) << 8) | ((0x1) << 4) | ((0x0) << 1) | ((0x1) << 0))
  ((((((10) - 1) + 16)) << 24) | ((0x0) << 16) | ((0x0) << 10) | ((0x0) << 9) | ((0x0) << 8) | ((0x2) << 4) | ((0x0) << 1) | ((0x1) << 0))
  ((((11 - 1)) << 24) | ((0x0) << 16) | ((0x0) << 10) | ((0x0) << 9) | ((0x0) << 8) | ((0x1) << 4) | ((0x0) << 1) | ((0x1) << 0))
  ((((((11) - 1) + 16)) << 24) | ((0x0) << 16) | ((0x0) << 10) | ((0x0) << 9) | ((0x0) << 8) | ((0x2) << 4) | ((0x0) << 1) | ((0x1) << 0))
  ((((12 - 1)) << 24) | ((0x0) << 16) | ((0x0) << 10) | ((0x0) << 9) | ((0x0) << 8) | ((0x1) << 4) | ((0x0) << 1) | ((0x1) << 0))
  ((((((12) - 1) + 16)) << 24) | ((0x0) << 16) | ((0x0) << 10) | ((0x0) << 9) | ((0x0) << 8) | ((0x2) << 4) | ((0x0) << 1) | ((0x1) << 0))
  ((((13 - 1)) << 24) | ((0x0) << 16) | ((0x0) << 10) | ((0x1) << 9) | ((0x1) << 8) | ((0x1) << 4) | ((0x0) << 1) | ((0x1) << 0))
  ((((((13) - 1) + 16)) << 24) | ((0x0) << 16) | ((0x0) << 10) | ((0x0) << 9) | ((0x0) << 8) | ((0x2) << 4) | ((0x0) << 1) | ((0x1) << 0))
  ((((14 - 1)) << 24) | ((0x0) << 16) | ((0x0) << 10) | ((0x1) << 9) | ((0x1) << 8) | ((0x1) << 4) | ((0x0) << 1) | ((0x1) << 0))
  ((((((14) - 1) + 16)) << 24) | ((0x0) << 16) | ((0x0) << 10) | ((0x0) << 9) | ((0x0) << 8) | ((0x2) << 4) | ((0x0) << 1) | ((0x1) << 0))
  ((((15 - 1)) << 24) | ((0x0) << 16) | ((0x0) << 10) | ((0x1) << 9) | ((0x1) << 8) | ((0x1) << 4) | ((0x0) << 1) | ((0x1) << 0))
  ((((((15) - 1) + 16)) << 24) | ((0x0) << 16) | ((0x0) << 10) | ((0x0) << 9) | ((0x0) << 8) | ((0x2) << 4) | ((0x0) << 1) | ((0x1) << 0))
  ((((16 - 1)) << 24) | ((0x0) << 16) | ((0x0) << 10) | ((0x1) << 9) | ((0x1) << 8) | ((0x1) << 4) | ((0x0) << 1) | ((0x1) << 0))
  ((((((16) - 1) + 16)) << 24) | ((0x0) << 16) | ((0x0) << 10) | ((0x0) << 9) | ((0x0) << 8) | ((0x2) << 4) | ((0x0) << 1) | ((0x1) << 0))
 >;
};

&ipcc2 {
 st,protreg = <
  ((((1 - 1)) << 24) | ((0x0) << 16) | ((0x0) << 10) | ((0x0) << 9) | ((0x0) << 8) | ((0x1) << 4) | ((0x0) << 1) | ((0x1) << 0))
  ((((((1) - 1) + 16)) << 24) | ((0x0) << 16) | ((0x0) << 10) | ((0x0) << 9) | ((0x0) << 8) | ((0x3) << 4) | ((0x0) << 1) | ((0x1) << 0))
  ((((2 - 1)) << 24) | ((0x0) << 16) | ((0x0) << 10) | ((0x0) << 9) | ((0x0) << 8) | ((0x1) << 4) | ((0x0) << 1) | ((0x1) << 0))
  ((((((2) - 1) + 16)) << 24) | ((0x0) << 16) | ((0x0) << 10) | ((0x0) << 9) | ((0x0) << 8) | ((0x3) << 4) | ((0x0) << 1) | ((0x1) << 0))
  ((((3 - 1)) << 24) | ((0x0) << 16) | ((0x0) << 10) | ((0x0) << 9) | ((0x0) << 8) | ((0x1) << 4) | ((0x0) << 1) | ((0x1) << 0))
  ((((((3) - 1) + 16)) << 24) | ((0x0) << 16) | ((0x0) << 10) | ((0x0) << 9) | ((0x0) << 8) | ((0x3) << 4) | ((0x0) << 1) | ((0x1) << 0))
  ((((4 - 1)) << 24) | ((0x0) << 16) | ((0x0) << 10) | ((0x0) << 9) | ((0x0) << 8) | ((0x1) << 4) | ((0x0) << 1) | ((0x1) << 0))
  ((((((4) - 1) + 16)) << 24) | ((0x0) << 16) | ((0x0) << 10) | ((0x0) << 9) | ((0x0) << 8) | ((0x3) << 4) | ((0x0) << 1) | ((0x1) << 0))
 >;
};

&hsem {
 st,proccid = <1 0x1>, <2 0x2>, <3 0x3>;
 st,protreg = <
  ((((0)) << 24) | ((0x0) << 16) | ((0x0) << 10) | ((0x0) << 9) | ((0x0) << 8) | ((0x0) << 4) | ((0x0) << 1) | ((0x0) << 0))
  ((((1)) << 24) | ((0x0) << 16) | ((0x0) << 10) | ((0x0) << 9) | ((0x0) << 8) | ((0x0) << 4) | ((0x0) << 1) | ((0x0) << 0))
  ((((2)) << 24) | ((0x0) << 16) | ((0x0) << 10) | ((0x0) << 9) | ((0x0) << 8) | ((0x0) << 4) | ((0x0) << 1) | ((0x0) << 0))
  ((((3)) << 24) | ((0x0) << 16) | ((0x0) << 10) | ((0x0) << 9) | ((0x0) << 8) | ((0x0) << 4) | ((0x0) << 1) | ((0x0) << 0))
  ((((4)) << 24) | ((0x0) << 16) | ((0x0) << 10) | ((0x0) << 9) | ((0x0) << 8) | ((0x0) << 4) | ((0x0) << 1) | ((0x0) << 0))
  ((((5)) << 24) | ((0x0) << 16) | ((0x0) << 10) | ((0x0) << 9) | ((0x0) << 8) | ((0x0) << 4) | ((0x0) << 1) | ((0x0) << 0))
  ((((6)) << 24) | ((0x0) << 16) | ((0x0) << 10) | ((0x0) << 9) | ((0x0) << 8) | ((0x0) << 4) | ((0x0) << 1) | ((0x0) << 0))
  ((((7)) << 24) | ((0x0) << 16) | ((0x0) << 10) | ((0x0) << 9) | ((0x0) << 8) | ((0x0) << 4) | ((0x0) << 1) | ((0x0) << 0))
  ((((8)) << 24) | ((0x0) << 16) | ((0x0) << 10) | ((0x0) << 9) | ((0x0) << 8) | ((0x0) << 4) | ((0x0) << 1) | ((0x0) << 0))
  ((((9)) << 24) | ((0x0) << 16) | ((0x0) << 10) | ((0x0) << 9) | ((0x0) << 8) | ((0x0) << 4) | ((0x0) << 1) | ((0x0) << 0))
  ((((10)) << 24) | ((0x0) << 16) | ((0x0) << 10) | ((0x0) << 9) | ((0x0) << 8) | ((0x0) << 4) | ((0x0) << 1) | ((0x0) << 0))
  ((((11)) << 24) | ((0x0) << 16) | ((0x0) << 10) | ((0x0) << 9) | ((0x0) << 8) | ((0x0) << 4) | ((0x0) << 1) | ((0x0) << 0))
  ((((12)) << 24) | ((0x0) << 16) | ((0x0) << 10) | ((0x0) << 9) | ((0x0) << 8) | ((0x0) << 4) | ((0x0) << 1) | ((0x0) << 0))
  ((((13)) << 24) | ((0x0) << 16) | ((0x0) << 10) | ((0x0) << 9) | ((0x0) << 8) | ((0x0) << 4) | ((0x0) << 1) | ((0x0) << 0))
  ((((14)) << 24) | ((0x0) << 16) | ((0x0) << 10) | ((0x0) << 9) | ((0x0) << 8) | ((0x0) << 4) | ((0x0) << 1) | ((0x0) << 0))
  ((((15)) << 24) | ((0x0) << 16) | ((0x0) << 10) | ((0x0) << 9) | ((0x0) << 8) | ((0x0) << 4) | ((0x0) << 1) | ((0x0) << 0))
 >;
};

&tfa_bl31 {
 st,protreg = <(((0x0) << 31) | ((0x0) << 27) | ((0x1) << 26) | ((0x0) << 25) | ((0x1) << 24) | (((1 << 0x1)) << 16) | (((1 << 0x1)) << 8) | ((1 << 0x1)))>;
};

&hpdma_lli {
 st,protreg = <(((0x0) << 31) | ((0x0) << 27) | ((0x0) << 26) | ((0x0) << 25) | ((0x1) << 24) | (((1 << 0x1)) << 16) | (((1 << 0x1)) << 8) | ((1 << 0x1)))>;
};

&bsec_mirror {
 st,protreg = <(((0x0) << 31) | ((0x0) << 27) | ((0x1) << 26) | ((0x0) << 25) | ((0x1) << 24) | (((1 << 0x1)) << 16) | (((1 << 0x1)|(1 << 0x2)) << 8) | ((1 << 0x1)|(1 << 0x2)))>;
};

&cm33_sram1 {
 st,protreg = <(((0x0) << 31) | ((0x0) << 27) | ((0x0) << 26) | ((0x0) << 25) | ((0x1) << 24) | (((1 << 0x2)) << 16) | (((1 << 0x2)) << 8) | (0))>;
};

&cm33_sram2 {
 st,protreg = <(((0x0) << 31) | ((0x0) << 27) | ((0x0) << 26) | ((0x0) << 25) | ((0x1) << 24) | (((1 << 0x2)) << 16) | (((1 << 0x2)) << 8) | (0))>;
};

&cm33_retram {
 st,protreg = <(((0x0) << 31) | ((0x0) << 27) | ((0x1) << 26) | ((0x0) << 25) | ((0x1) << 24) | (((1 << 0x2)) << 16) | (((1 << 0x2)) << 8) | (0))>;
};

&ddr_param {
 st,protreg = <(((0x0) << 31) | ((0x0) << 27) | ((0x1) << 26) | ((0x0) << 25) | ((0x1) << 24) | (((1 << 0x1)) << 16) | (((1 << 0x1)) << 8) | ((1 << 0x1)))>;
};

&risab1 {
 memory-region = <&tfa_bl31>;
};

&risab2 {
 memory-region = <&hpdma_lli>;
};

&risab3 {
 st,srwiad;
 memory-region = <&bsec_mirror>, <&cm33_sram1>;
};

&risab4 {
 st,srwiad;
 memory-region = <&cm33_sram2>;
};

&risab5 {
 st,srwiad;
 memory-region = <&cm33_retram>, <&ddr_param>;
};

&ommanager {
 st,protreg = <
  (((74) << 24) | ((0x0) << 16) | ((0x0) << 10) | ((0x0) << 9) | ((0x0) << 8) | ((0x0) << 4) | ((0x1) << 1) | ((0x1) << 0))
  (((75) << 24) | ((0x0) << 16) | ((0x0) << 10) | ((0x0) << 9) | ((0x0) << 8) | ((0x0) << 4) | ((0x1) << 1) | ((0x1) << 0))
  (((111) << 24) | ((0x0) << 16) | ((0x0) << 10) | ((0x0) << 9) | ((0x0) << 8) | ((0x0) << 4) | ((0x1) << 1) | ((0x1) << 0))
  (((125) << 24) | ((0x0) << 16) | ((0x0) << 10) | ((0x0) << 9) | ((0x0) << 8) | ((0x0) << 4) | ((0x1) << 1) | ((0x1) << 0))
  (((126) << 24) | ((0x0) << 16) | ((0x0) << 10) | ((0x0) << 9) | ((0x0) << 8) | ((0x0) << 4) | ((0x1) << 1) | ((0x1) << 0))
 >;

 st,omm-mux = <0x0>;

};

&bl31_lowpower {
 st,protreg = <((((1 << 0x1)) << 24) | (((1 << 0x1)) << 16) | (((1 << 0x1)) << 8) | ((0x0) << 6) | ((0x1) << 5) | ((0x1) << 4) | ((1)))>;
};

&tfm_its {
 st,protreg = <((((1 << 0x2)) << 24) | (((1 << 0x2)) << 16) | (((1 << 0x2)) << 8) | ((0x0) << 6) | ((0x1) << 5) | ((0x1) << 4) | ((2)))>;
};

&risaf1 {
 memory-region= <&bl31_lowpower>, <&tfm_its>;
};

&tfm_code {
 st,protreg = <((((1 << 0x2)) << 24) | (((1 << 0x2)) << 16) | ((0x0) << 8) | ((0x2) << 6) | ((0x1) << 5) | ((0x1) << 4) | ((1)))>;
};

&cm33_cube_fw {
 st,protreg = <((((1 << 0x2)) << 24) | (((1 << 0x2)) << 16) | ((0x0) << 8) | ((0x0) << 6) | ((0x0) << 5) | ((0x1) << 4) | ((2)))>;
};

&tfm_data {
 st,protreg = <((((1 << 0x2)) << 24) | (((1 << 0x2)) << 16) | ((0x0) << 8) | ((0x2) << 6) | ((0x1) << 5) | ((0x1) << 4) | ((3)))>;
};

&cm33_cube_data {
 st,protreg = <((((1 << 0x2)) << 24) | (((1 << 0x2)) << 16) | ((0x0) << 8) | ((0x0) << 6) | ((0x0) << 5) | ((0x1) << 4) | ((4)))>;
};

&ipc_shmem {
 st,protreg = <((((1 << 0x1)|(1 << 0x2)) << 24) | (((1 << 0x1)|(1 << 0x2)) << 16) | ((0x0) << 8) | ((0x0) << 6) | ((0x0) << 5) | ((0x1) << 4) | ((5)))>;
};

&spare1 {
 st,protreg = <(((0x0) << 24) | ((0x0) << 16) | ((0x0) << 8) | ((0x0) << 6) | ((0x0) << 5) | ((0x1) << 4) | ((6)))>;
};

&bl31_context {
 st,protreg = <((((1 << 0x1)) << 24) | (((1 << 0x1)) << 16) | (((1 << 0x1)) << 8) | ((0x2) << 6) | ((0x1) << 5) | ((0x1) << 4) | ((7)))>;
};

&op_tee {
 st,protreg = <((((1 << 0x1)) << 24) | (((1 << 0x1)) << 16) | ((0x0) << 8) | ((0x2) << 6) | ((0x1) << 5) | ((0x1) << 4) | ((8)))>;
};

&linuxkernel1 {
 st,protreg = <((((1 << 0x1)|(1 << 0x4)) << 24) | (((1 << 0x1)|(1 << 0x4)) << 16) | ((0x0) << 8) | ((0x0) << 6) | ((0x0) << 5) | ((0x1) << 4) | ((9)))>;
};

&gpu_reserved {
 st,protreg = <((((1 << 0x1)|(1 << 0x4)) << 24) | (((1 << 0x1)|(1 << 0x4)) << 16) | ((0x0) << 8) | ((0x0) << 6) | ((0x0) << 5) | ((0x1) << 4) | ((10)))>;
};

&ltdc_sec_layer {
 st,protreg = <((((1 << 0x1)|(1 << 0x4)) << 24) | (((1 << 0x1)|(1 << 0x4)) << 16) | ((0x0) << 8) | ((0x0) << 6) | ((0x1) << 5) | ((0x1) << 4) | ((13)))>;
};

&ltdc_sec_rotation {
 st,protreg = <((((1 << 0x1)|(1 << 0x4)) << 24) | (((1 << 0x1)|(1 << 0x4)) << 16) | ((0x0) << 8) | ((0x0) << 6) | ((0x0) << 5) | ((0x1) << 4) | ((14)))>;
};

&linuxkernel2 {
 st,protreg = <((((1 << 0x1)) << 24) | (((1 << 0x1)) << 16) | ((0x0) << 8) | ((0x0) << 6) | ((0x0) << 5) | ((0x1) << 4) | ((15)))>;
};

&risaf4 {
 memory-region= <&tfm_code>, <&cm33_cube_fw>, <&tfm_data>, <&cm33_cube_data>, <&ipc_shmem>, <&spare1>, <&bl31_context>, <&op_tee>, <&linuxkernel1>, <&gpu_reserved>, <&ltdc_sec_layer>, <&ltdc_sec_rotation>, <&linuxkernel2>;
};
# 24 "../myir-st-external-dt/optee/myb-stm32mp257x-2GB-ca35tdcid-ostl.dts" 2
# 1 "core/arch/arm/dts/stm32mp25-pinctrl.dtsi" 1





# 1 "core/include/dt-bindings/pinctrl/stm32-pinfunc.h" 1
# 7 "core/arch/arm/dts/stm32mp25-pinctrl.dtsi" 2

&pinctrl {
 i2c7_pins_a: i2c7-0 {
  pins1 {
   pinmux = <(((((('D') - 'A') * 0x10 + (15))) << 8) | (0xb))>,
     <(((((('D') - 'A') * 0x10 + (14))) << 8) | (0xb))>;
   bias-disable;
   drive-open-drain;
   slew-rate = <0>;
  };
 };

 i2c7_sleep_pins_a: i2c7-sleep-0 {
  pins1 {
   pinmux = <(((((('D') - 'A') * 0x10 + (15))) << 8) | (0x11))>,
     <(((((('D') - 'A') * 0x10 + (14))) << 8) | (0x11))>;
  };
 };

 ospi_port1_clk_pins_a: ospi-port1-clk-0 {
  pins {
   pinmux = <(((((('D') - 'A') * 0x10 + (0))) << 8) | (0xb))>;
   bias-disable;
   drive-push-pull;
   slew-rate = <2>;
  };
 };

 ospi_port1_clk_sleep_pins_a: ospi-port1-clk-sleep-0 {
  pins {
   pinmux = <(((((('D') - 'A') * 0x10 + (0))) << 8) | (0x11))>;
  };
 };

 ospi_port1_cs0_pins_a: ospi-port1-cs0-0 {
  pins {
   pinmux = <(((((('D') - 'A') * 0x10 + (3))) << 8) | (0xb))>;
   bias-pull-up;
   drive-push-pull;
   slew-rate = <0>;
  };
 };

 ospi_port1_cs0_sleep_pins_a: ospi-port1-cs0-sleep-0 {
  pins {
   pinmux = <(((((('D') - 'A') * 0x10 + (3))) << 8) | (0x11))>;
  };
 };

 ospi_port1_io03_pins_a: ospi-port1-io03-0 {
  pins {
   pinmux = <(((((('D') - 'A') * 0x10 + (4))) << 8) | (0xb))>,
     <(((((('D') - 'A') * 0x10 + (5))) << 8) | (0xb))>,
     <(((((('D') - 'A') * 0x10 + (6))) << 8) | (0xb))>,
     <(((((('D') - 'A') * 0x10 + (7))) << 8) | (0xb))>;
   bias-disable;
   drive-push-pull;
   slew-rate = <0>;
  };
 };

 ospi_port1_io03_sleep_pins_a: ospi-port1-io03-sleep-0 {
  pins {
   pinmux = <(((((('D') - 'A') * 0x10 + (4))) << 8) | (0x11))>,
     <(((((('D') - 'A') * 0x10 + (5))) << 8) | (0x11))>,
     <(((((('D') - 'A') * 0x10 + (6))) << 8) | (0x11))>,
     <(((((('D') - 'A') * 0x10 + (7))) << 8) | (0x11))>;
  };
 };

 tamp_in1_pin_a: tamp-in1-pin-0 {
  pins {
   pinmux = <(((((('I') - 'A') * 0x10 + (8))) << 8) | (0x12))>;
   st,tamp-id = <1>;
  };
 };

 tamp_in3_pin_a: tamp-in3-pin-0 {
  pins {
   pinmux = <(((((('Z') - 'A') * 0x10 + (2))) << 8) | (0x12))>;
   st,tamp-id = <3>;
  };
 };

 usart2_pins_a: usart2-0 {
  pins1 {
   pinmux = <(((((('A') - 'A') * 0x10 + (4))) << 8) | (0x7))>;
   bias-disable;
   drive-push-pull;
   slew-rate = <0>;
  };
  pins2 {
   pinmux = <(((((('A') - 'A') * 0x10 + (8))) << 8) | (0x9))>;
   bias-disable;
  };
 };

 wakeup_pins: wakeup_pins-0 {
  wakeup_pin_1: pins1 {
   pinmux = <(((((('A') - 'A') * 0x10 + (0))) << 8) | (0x0))>;
  };
  wakeup_pin_2: pins2 {
   pinmux = <(((((('H') - 'A') * 0x10 + (5))) << 8) | (0x0))>;
  };
  wakeup_pin_3: pins3 {
   pinmux = <(((((('G') - 'A') * 0x10 + (1))) << 8) | (0x0))>;
  };
  wakeup_pin_4: pins4 {
   pinmux = <(((((('I') - 'A') * 0x10 + (6))) << 8) | (0x0))>;
  };
  wakeup_pin_5: pins5 {
   pinmux = <(((((('G') - 'A') * 0x10 + (2))) << 8) | (0x0))>;
  };
  wakeup_pin_6: pins6 {
   pinmux = <(((((('G') - 'A') * 0x10 + (3))) << 8) | (0x0))>;
  };
 };
};
# 25 "../myir-st-external-dt/optee/myb-stm32mp257x-2GB-ca35tdcid-ostl.dts" 2
# 1 "core/arch/arm/dts/stm32mp25xxal-pinctrl.dtsi" 1






&pinctrl {
 gpioa: gpio@44240000 {
  status = "okay";
  ngpios = <16>;
  gpio-ranges = <&pinctrl 0 0 16>;
 };

 gpiob: gpio@44250000 {
  status = "okay";
  ngpios = <16>;
  gpio-ranges = <&pinctrl 0 16 16>;
 };

 gpioc: gpio@44260000 {
  status = "okay";
  ngpios = <14>;
  gpio-ranges = <&pinctrl 0 32 14>;
 };

 gpiod: gpio@44270000 {
  status = "okay";
  ngpios = <16>;
  gpio-ranges = <&pinctrl 0 48 16>;
 };

 gpioe: gpio@44280000 {
  status = "okay";
  ngpios = <16>;
  gpio-ranges = <&pinctrl 0 64 16>;
 };

 gpiof: gpio@44290000 {
  status = "okay";
  ngpios = <16>;
  gpio-ranges = <&pinctrl 0 80 16>;
 };

 gpiog: gpio@442a0000 {
  status = "okay";
  ngpios = <16>;
  gpio-ranges = <&pinctrl 0 96 16>;
 };

 gpioh: gpio@442b0000 {
  status = "okay";
  ngpios = <12>;
  gpio-ranges = <&pinctrl 2 114 12>;
 };

 gpioi: gpio@442c0000 {
  status = "okay";
  ngpios = <12>;
  gpio-ranges = <&pinctrl 0 128 12>;
 };
};

&pinctrl_z {
 gpioz: gpio@46200000 {
  status = "okay";
  ngpios = <10>;
  gpio-ranges = <&pinctrl_z 0 400 10>;
 };
};
# 26 "../myir-st-external-dt/optee/myb-stm32mp257x-2GB-ca35tdcid-ostl.dts" 2

/ {
 model = "STMicroelectronics STM32MP257F-DK CA35TDCID OSTL Discovery Board";
 compatible = "st,stm32mp257f-dk-ca35tdcid-ostl", "st,stm32mp257f-dk", "st,stm32mp257";

 aliases {
  serial0 = &usart2;
 };

 chosen {
  stdout-path = "serial0:115200n8";
 };

 memory@80000000 {
  device_type = "memory";
  reg = <0x0 0x80000000 0x1 0x00000000>;
 };

 shadow-prov {
  compatible = "st,provisioning";
  hconf1_prov {
   nvmem-cells = <&hconf1_otp>;
   st,shadow-value = <0x00018DB6>;
  };
 };
};

&cpu0 {
 cpu-supply = <&vddcpu>;
};

&hash {
 status = "okay";
};

&hse_monitor {
 status = "okay";
};

&hsi_calibration {
 status = "okay";
};

&i2c7 {
 pinctrl-names = "default", "sleep";
 pinctrl-0 = <&i2c7_pins_a>;
 pinctrl-1 = <&i2c7_sleep_pins_a>;
 i2c-scl-rising-time-ns = <185>;
 i2c-scl-falling-time-ns = <20>;
 clock-frequency = <400000>;
 status = "okay";
 #address-cells = <1>;
 #size-cells = <0>;

 pmic2: stpmic2@33 {
  compatible = "st,stpmic2";
  reg = <0x33>;
  st,wakeup-pin-number = <1>;
  st,pmic-it-id = <0 1>;
  st,notif-it-id = <0 1>;
  status = "okay";

  regulators {
   compatible = "st,stpmic2-regulators";

   ldo1-supply = <&vddio_pmic>;

   vddcpu: buck1 {
    regulator-name = "vddcpu";
    regulator-min-microvolt = <800000>;
    regulator-max-microvolt = <910000>;
    regulator-always-on;
    st,pwrctrl-sel = <2>;
    st,pwrctrl-enable;

    default {
     regulator-off-in-suspend;
    };
    lplv {
     regulator-off-in-suspend;
    };
    standby {
     regulator-off-in-suspend;
    };
    off {
     regulator-off-in-suspend;
    };
   };
   vddcore: buck2 {
    regulator-name = "vddcore";
    regulator-min-microvolt = <820000>;
    regulator-max-microvolt = <820000>;
    regulator-always-on;
    st,pwrctrl-sel = <1>;
    st,pwrctrl-enable;

    default {
     regulator-on-in-suspend;
     regulator-suspend-microvolt = <820000>;
    };
    lplv {
     regulator-on-in-suspend;
     regulator-suspend-microvolt = <670000>;
    };
    standby {
     regulator-off-in-suspend;
    };
    off {
     regulator-off-in-suspend;
    };
   };
   vddgpu_pmic: buck3 {
    regulator-name = "vddgpu_pmic";
    regulator-min-microvolt = <800000>;
    regulator-max-microvolt = <900000>;
    regulator-over-current-protection;
   };
   vddio_pmic: buck4 {
    regulator-name = "vddio_pmic";
    regulator-min-microvolt = <3300000>;
    regulator-max-microvolt = <3300000>;
    regulator-always-on;
    st,mask-reset;
    st,pwrctrl-sel = <1>;
    st,pwrctrl-enable;

    default {
     regulator-on-in-suspend;
     regulator-suspend-microvolt = <3300000>;
    };
    lplv {
     regulator-on-in-suspend;
     regulator-suspend-microvolt = <3300000>;
    };
    standby {
     regulator-on-in-suspend;
     regulator-suspend-microvolt = <3300000>;
    };
    off {

     regulator-on-in-suspend;
     regulator-suspend-microvolt = <3300000>;
    };
   };
   v1v8: buck5 {
    regulator-name = "v1v8";
    regulator-min-microvolt = <1800000>;
    regulator-max-microvolt = <1800000>;
    regulator-always-on;
    st,pwrctrl-sel = <1>;
    st,pwrctrl-enable;

    default {
     regulator-on-in-suspend;
     regulator-suspend-microvolt = <1800000>;
    };
    lplv {
     regulator-on-in-suspend;
     regulator-suspend-microvolt = <1800000>;
    };
    standby {
     regulator-off-in-suspend;
    };
    off {
     regulator-off-in-suspend;
    };
   };
   vdd2_ddr: buck6 {
    regulator-name = "vdd2_ddr";
    regulator-min-microvolt = <1100000>;
    regulator-max-microvolt = <1100000>;
    regulator-always-on;
    st,pwrctrl-sel = <1>;
    st,pwrctrl-enable;

    default {
     regulator-on-in-suspend;
     regulator-suspend-microvolt = <1100000>;
    };
    lplv {
     regulator-on-in-suspend;
     regulator-suspend-microvolt = <1100000>;
    };
    standby {
     regulator-on-in-suspend;
     regulator-suspend-microvolt = <1100000>;
    };
    off {
     regulator-off-in-suspend;
    };
   };
   v3v3: buck7 {
    regulator-name = "v3v3";
    regulator-min-microvolt = <3300000>;
    regulator-max-microvolt = <3300000>;
    regulator-always-on;
    regulator-over-current-protection;
    st,pwrctrl-sel = <1>;
    st,pwrctrl-enable;

    default {
     regulator-on-in-suspend;
     regulator-suspend-microvolt = <3300000>;
    };
    lplv {
     regulator-on-in-suspend;
     regulator-suspend-microvolt = <3300000>;
    };
    standby {
     regulator-off-in-suspend;
    };
    off {
     regulator-off-in-suspend;
    };
   };
   vdda1v8_aon: ldo1 {
    regulator-name = "vdda1v8_aon";
    regulator-min-microvolt = <1800000>;
    regulator-max-microvolt = <1800000>;
    regulator-always-on;
    st,alternate-input-source;
    st,mask-reset;
   };
   vdd_emmc: ldo2 {
    regulator-name = "vdd_emmc";
    regulator-min-microvolt = <3300000>;
    regulator-max-microvolt = <3300000>;
    regulator-over-current-protection;
    st,pwrctrl-sel = <3>;
    st,pwrctrl-reset;
   };
   vdd1_ddr: ldo3 {
    regulator-name = "vdd1_ddr";
    regulator-min-microvolt = <1800000>;
    regulator-max-microvolt = <1800000>;
    regulator-always-on;
    st,pwrctrl-sel = <1>;
    st,pwrctrl-enable;

    default {
     regulator-on-in-suspend;
     regulator-suspend-microvolt = <1800000>;
    };
    lplv {
     regulator-on-in-suspend;
     regulator-suspend-microvolt = <1800000>;
    };
    standby {
     regulator-on-in-suspend;
     regulator-suspend-microvolt = <1800000>;
    };
    off {
     regulator-off-in-suspend;
    };
   };
   vdd3v3_usb: ldo4 {
    regulator-name = "vdd3v3_usb";
    regulator-min-microvolt = <3300000>;
    regulator-max-microvolt = <3300000>;
    regulator-always-on;
    regulator-over-current-protection;
   };
   v5v_hdmi: ldo5 {
    regulator-name = "v5v_hdmi";
    regulator-min-microvolt = <5000000>;
    regulator-max-microvolt = <5000000>;
    st,regulator-bypass-microvolt = <5000000>;
    st,pwrctrl-sel = <0>;
    st,pwrctrl-enable;
   };
   v5v_vconn: ldo6 {
    regulator-name = "v5v_vconn";
    regulator-min-microvolt = <5000000>;
    regulator-max-microvolt = <5000000>;
    regulator-always-on;
    st,regulator-bypass-microvolt = <5000000>;
    st,pwrctrl-sel = <0>;
    st,pwrctrl-reset;
   };
   vdd_sdcard: ldo7 {
    regulator-name = "vdd_sdcard";
    regulator-min-microvolt = <3300000>;
    regulator-max-microvolt = <3300000>;
    regulator-over-current-protection;
    st,regulator-bypass-microvolt = <3300000>;
    st,pwrctrl-sel = <3>;
    st,pwrctrl-reset;
   };
   vddio_sdcard: ldo8 {
    regulator-name = "vddio_sdcard";
    regulator-min-microvolt = <1800000>;
    regulator-max-microvolt = <3300000>;
    regulator-over-current-protection;
    st,regulator-bypass-microvolt = <3300000>;

    st,pwrctrl-sel = <3>;
    st,pwrctrl-reset;
   };
  };
 };
};

&iwdg1 {
 timeout-sec = <32>;
 status = "okay";
};

&lptimer1 {
 status = "okay";

 counter {
  status = "okay";
 };
};

&ltdc {
 status = "okay";
};

&m33_rproc {
 compatible = "st,stm32mp2-m33-tee";
 memory-region = <&cm33_cube_fw>, <&cm33_cube_data>,
   <&ipc_shmem>, <&tfm_code>, <&tfm_data>,
   <&cm33_sram2>;
 status = "okay";
};

&pka {
 status = "okay";
};

&pwr {
 pinctrl-names = "default";
 pinctrl-0 = <&wakeup_pins>;
 status = "okay";

 vdd33ucpd: vdd33ucpd {
  status = "okay";
  regulator-min-microvolt = <3300000>;
  regulator-max-microvolt = <3300000>;
  vdd33ucpd-supply = <&vdd3v3_usb>;
  regulator-always-on;
 };

 vdda18adc: vdda18adc {
  status = "okay";
  regulator-min-microvolt = <1800000>;
  regulator-max-microvolt = <1800000>;
  vdda18adc-supply = <&v1v8>;
  regulator-always-on;
 };

 vddgpu: vddgpu {
  status = "okay";
  vddgpu-supply = <&vddgpu_pmic>;
 };

 vddio1: vddio1 {
  status = "okay";
  regulator-min-microvolt = <1800000>;
  regulator-max-microvolt = <3300000>;
  vddio1-supply = <&vddio_sdcard>;
 };

 vddio2: vddio2 {
  status = "okay";
  vddio2-supply = <&v1v8>;
  regulator-always-on;
 };

 vddio3: vddio3 {
  status = "okay";
  vddio3-supply = <&vddio_pmic>;
  regulator-always-on;
 };

 vddio4: vddio4 {
  status = "okay";
  vddio4-supply = <&vddio_pmic>;
  regulator-always-on;
 };

 vddio: vddio {
  status = "okay";
  vdd-supply = <&vddio_pmic>;
 };
};

&rcc {
 st,c1msrd = <2>;
 st,clk_opp {
  st,ck_cpu1 {
   cfg_1 {
    hz = <1500000000>;
    st,clksrc = <0>;
    st,pll = <&pll1_cfg_1500Mhz>;
   };

   cfg_2 {
    hz = <1200000000>;
    st,clksrc = <0>;
    st,pll = <&pll1_cfg_1200Mhz>;
   };
  };
 };
};

&risaf2 {
 status = "okay";
};

&risaf5 {
 status = "okay";
};

&rtc {
 status = "okay";
};

&saes {
 status = "okay";
};

&scmi_regu {
 scmi_vddcore: voltd-vddcore {
  reg = <11>;
  voltd-supply = <&vddcore>;
 };
 scmi_v1v8: voltd-v1v8 {
  reg = <14>;
  voltd-supply = <&v1v8>;
 };
 scmi_v3v3: voltd-v3v3 {
  reg = <16>;
  voltd-supply = <&v3v3>;
 };
 scmi_v5v_hdmi: voltd-v5v-hdmi {
  reg = <21>;
  voltd-supply = <&v5v_hdmi>;
 };
 scmi_v5v_vconn: voltd-v5v-vconn {
  reg = <22>;
  voltd-supply = <&v5v_vconn>;
 };
 scmi_vdd_emmc: voltd-vdd-emmc {
  reg = <18>;
  voltd-supply = <&vdd_emmc>;
 };
 scmi_vdd3v3_usb: voltd-vdd3v3-usb {
  reg = <20>;
  voltd-supply = <&vdd3v3_usb>;
 };
 scmi_vdd_sdcard: voltd-vdd_sdcard {
  reg = <23>;
  voltd-supply = <&vdd_sdcard>;
 };
};

&tamp {
 wakeup-source;
 wakeup-parent = <&exti2>;
 st,tamp-passive-precharge = <2>;
 st,tamp-passive-nb-sample = <4>;
 st,tamp-passive-sample-clk-div = <16384>;


 tamp_button: tamp-passive@3 {
  status = "disabled";
  reg = <3 0>;
  pinctrl-0 = <&tamp_in3_pin_a>;
  st,tamp-mode = <2>;
 };
};

&usart2 {
 pinctrl-names = "default";
 pinctrl-0 = <&usart2_pins_a>;
 status = "okay";
};
